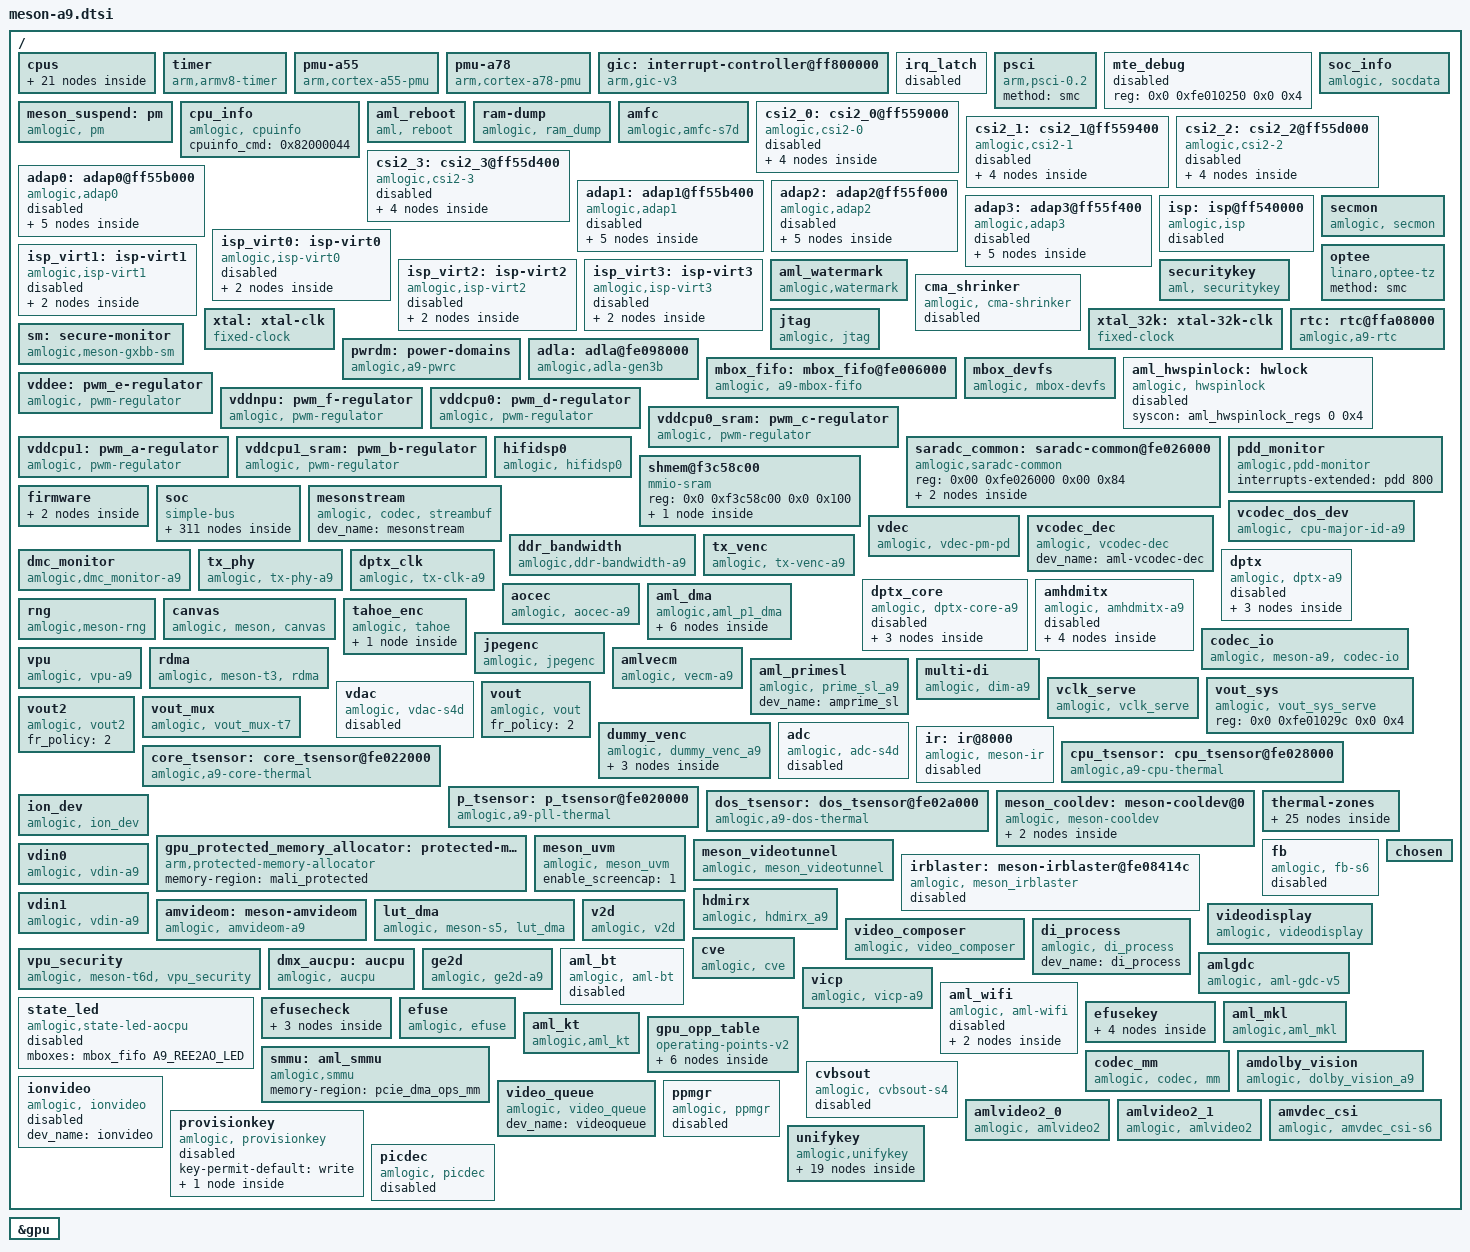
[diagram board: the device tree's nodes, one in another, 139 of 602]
// SPDX-License-Identifier: (GPL-2.0+ OR MIT)
/*
 * Copyright (c) 2019 Amlogic, Inc. All rights reserved.
 */

#include <dt-bindings/clock/axg-audio-clkc.h>
#include <dt-bindings/clock/amlogic,a9-scmi-clkc.h>
#include <dt-bindings/clock/amlogic,a9-clkc.h>
#include <dt-bindings/interrupt-controller/irq.h>
#include <dt-bindings/interrupt-controller/arm-gic.h>
#include <dt-bindings/power/a9-pd.h>
#include <dt-bindings/power/amlogic-a9-power.h>
#include <dt-bindings/dma/amlogic,a9-dma.h>
#include <dt-bindings/gpio/gpio.h>
#include <dt-bindings/gpio/meson-a9-gpio.h>
#include <dt-bindings/reset/amlogic,meson-a9-reset.h>
#include <dt-bindings/pwm/pwm.h>
#include <dt-bindings/pwm/meson.h>
#include <dt-bindings/input/input.h>
#include <dt-bindings/input/meson_ir.h>
#include <dt-bindings/mailbox/amlogic,mbox.h>
#include <dt-bindings/firmware/amlogic,firmware.h>
#include <dt-bindings/mailbox/a9-mbox.h>
#include <dt-bindings/iio/adc/amlogic-saradc.h>
#include <dt-bindings/thermal/ddr-params.h>
#include <dt-bindings/pinctrl/amlogic,pinctrl.h>
#include "meson-ir-map.dtsi"
#include "meson-avalon.dtsi"
#include <dt-bindings/power/meson-pm.h>
#include <dt-bindings/i2c/i2c-meson.h>
/ {
	cpus:cpus {
		#address-cells = <2>;
		#size-cells = <0>;

		cpu-map {
			cluster0:cluster0 {
				core0 {
					cpu = <&CPU0>;
				};
				core1 {
					cpu = <&CPU1>;
				};
				core2 {
					cpu = <&CPU2>;
				};
				core3 {
					cpu = <&CPU3>;
				};
				core4 {
					cpu = <&CPU4>;
				};
				core5 {
					cpu = <&CPU5>;
				};
				core6 {
					cpu = <&CPU6>;
				};
				core7 {
					cpu = <&CPU7>;
				};
			};
		};

		CPU0:cpu@0 {
			device_type = "cpu";
			compatible = "arm,cortex-a55","arm,armv8";
			reg = <0x0 0x0>;
			enable-method = "psci";
			cpu-idle-states = <&CPU_SLEEP_0 &SYSTEM_SLEEP_0>;
			capacity-dmips-mhz = <430>;
			dynamic-power-coefficient = <59>;
			#cooling-cells = <2>;
		};

		CPU1:cpu@1 {
			device_type = "cpu";
			compatible = "arm,cortex-a55","arm,armv8";
			reg = <0x0 0x100>;
			enable-method = "psci";
			cpu-idle-states = <&CPU_SLEEP_0 &SYSTEM_SLEEP_0>;
			capacity-dmips-mhz = <430>;
			dynamic-power-coefficient = <59>;
			#cooling-cells = <2>;
		};

		CPU2:cpu@2 {
			device_type = "cpu";
			compatible = "arm,cortex-a55","arm,armv8";
			reg = <0x0 0x200>;
			enable-method = "psci";
			cpu-idle-states = <&CPU_SLEEP_0 &SYSTEM_SLEEP_0>;
			capacity-dmips-mhz = <430>;
			dynamic-power-coefficient = <59>;
			#cooling-cells = <2>;
		};

		CPU3:cpu@3 {
			device_type = "cpu";
			compatible = "arm,cortex-a55","arm,armv8";
			reg = <0x0 0x300>;
			enable-method = "psci";
			cpu-idle-states = <&CPU_SLEEP_0 &SYSTEM_SLEEP_0>;
			capacity-dmips-mhz = <430>;
			dynamic-power-coefficient = <59>;
			#cooling-cells = <2>;
		};

		CPU4:cpu@4 {
			device_type = "cpu";
			compatible = "arm,cortex-a55","arm,armv8";
			reg = <0x0 0x400>;
			enable-method = "psci";
			cpu-idle-states = <&CPU_SLEEP_0 &SYSTEM_SLEEP_0>;
			capacity-dmips-mhz = <430>;
			dynamic-power-coefficient = <59>;
			#cooling-cells = <2>;
		};

		CPU5:cpu@5 {
			device_type = "cpu";
			compatible = "arm,cortex-a55","arm,armv8";
			reg = <0x0 0x500>;
			enable-method = "psci";
			cpu-idle-states = <&CPU_SLEEP_0 &SYSTEM_SLEEP_0>;
			capacity-dmips-mhz = <430>;
			dynamic-power-coefficient = <59>;
			#cooling-cells = <2>;
		};

		CPU6:cpu@6 {
			device_type = "cpu";
			compatible = "arm,cortex-a78","arm,armv8";
			reg = <0x0 0x600>;
			enable-method = "psci";
			cpu-idle-states = <&CPU_SLEEP_0 &SYSTEM_SLEEP_0>;
			capacity-dmips-mhz = <1024>;
			dynamic-power-coefficient = <416>;
			#cooling-cells = <2>;
		};

		CPU7:cpu@7 {
			device_type = "cpu";
			compatible = "arm,cortex-a78","arm,armv8";
			reg = <0x0 0x700>;
			enable-method = "psci";
			cpu-idle-states = <&CPU_SLEEP_0 &SYSTEM_SLEEP_0>;
			capacity-dmips-mhz = <1024>;
			dynamic-power-coefficient = <416>;
			#cooling-cells = <2>;
		};

		idle-states {
			entry-method = "arm,psci-0.2";
			CPU_SLEEP_0: cpu-sleep-0 {
					compatible = "arm,idle-state";
					arm,psci-suspend-param = <0x0010000>;
					local-timer-stop;
					entry-latency-us = <300>;
					exit-latency-us = <534>;
					min-residency-us = <1600>;
			};
			SYSTEM_SLEEP_0: system-sleep-0 {
					compatible = "arm,idle-state";
					arm,psci-suspend-param = <0x0000000>;
					entry-latency-us = <0x3fffffff>;
					exit-latency-us = <0x40000000>;
					min-residency-us = <0xffffffff>;
			};
		};
	};

	timer {
		compatible = "arm,armv8-timer";
		interrupts = <GIC_PPI 13 0xff08>,
				<GIC_PPI 14 0xff08>,
				<GIC_PPI 11 0xff08>,
				<GIC_PPI 10 0xff08>;
	};

	pmu-a55 {
		compatible = "arm,cortex-a55-pmu";
		private-interrupts;
		interrupts = <GIC_SPI 359 IRQ_TYPE_LEVEL_HIGH>,
			     <GIC_SPI 360 IRQ_TYPE_LEVEL_HIGH>,
			     <GIC_SPI 361 IRQ_TYPE_LEVEL_HIGH>,
			     <GIC_SPI 362 IRQ_TYPE_LEVEL_HIGH>,

			     <GIC_SPI 363 IRQ_TYPE_LEVEL_HIGH>,
			     <GIC_SPI 364 IRQ_TYPE_LEVEL_HIGH>;
		interrupt-affinity = <&CPU0>,
				     <&CPU1>,
				     <&CPU2>,
				     <&CPU3>,
				     <&CPU4>,
				     <&CPU5>;
	};

	pmu-a78 {
		compatible = "arm,cortex-a78-pmu";
		private-interrupts;
		interrupts = <GIC_SPI 365 IRQ_TYPE_LEVEL_HIGH>,
			     <GIC_SPI 366 IRQ_TYPE_LEVEL_HIGH>;
		interrupt-affinity = <&CPU6>,
				     <&CPU7>;
	};

	gic: interrupt-controller@ff800000 {
		compatible = "arm,gic-v3";
		#interrupt-cells = <3>;
		#address-cells = <0>;
		interrupt-controller;
		reg = <0x0 0xff800000 0 0x10000>,
		      <0x0 0xff840000 0 0x100000>;
		interrupts = <GIC_PPI 9 0xf04>;
	};

	irq_latch {
		/* only for GICv3 */
		status = "disabled";
		reg = <0x0 0xfe00a140 0x0 0x30>, /*mode*/
			<0x0 0xfe00a1c0 0x0 0x30>; /*latch clear*/
	};

	psci {
		compatible = "arm,psci-0.2";
		method = "smc";
	};

	mte_debug {
		status = "disabled";
		reg = <0x0 0xfe010250 0x0 0x4>; /*SYSCTRL_DEBUG_REG4*/
	};

	meson_suspend:pm {
		compatible = "amlogic, pm";
		status = "okay";
		device_name = "aml_pm";
		extend_resume_reason;
		clear_suspend_reason = <9>; /* Clear netflix wakeup reason */
		reg = <0x0 0xffa800e4 0x0 0x4>, /*SYSCTRL_STATUS_REG2*/
			<0x0 0xffa8005c 0x0 0x4>; /*SYSCTRL_STICKY_REG7*/
//		deep_mode = <SYSTEM_SUSPEND_EE_PWR_DOWN>;
		/*deep_mode supports custom configuration */
		deep_mode = <(DEFINE(DDR, NORMAL) | DEFINE(EE_PWR_DN, OFF))>;
	};

	cpu_info {
		compatible = "amlogic, cpuinfo";
		status = "okay";
		cpuinfo_cmd = <0x82000044>;
	};

	soc_info {
		compatible = "amlogic, socdata";
		reg =	<0x0 0xfe010000 0x0 0xc>,
			<0x0 0xfe010180 0x0 0x4>;
		read_nocsdata_cmd =<0x82000039>;
		write_nocsdata_cmd=<0x82000038>;
		auth_reg_ops_cmd=<0x820000f0>;
	};

	aml_reboot {
		compatible = "aml, reboot";
		sys_reset = <0x84000009>;
		sys_poweroff = <0x84000008>;
		dis_nb_cpus_in_shutdown;
		extend_reboot_reason; /* Support up to 128 reboot reasons*/
		reg = <0x0 0xfe01037c 0x0 0x4>; /* SEC_AO_SEC_SD_CFG15 */
		status = "okay";
	};

	ram-dump {
		compatible = "amlogic, ram_dump";
		status = "okay";
		reg = <0x0 0xFFA80058 0x0 4>;
		reg-names = "SYSCTRL_STICKY_REG6";
		store_device = "data";
	};

	amfc {
		compatible = "amlogic,amfc-s7d";
		status = "okay";
		/* registers and clk */
		reg = <0x0 0xfe024000 0x0 0x200
		       0x0 0xfe000000 0x0 0x400>;
		interrupts = <0 185 IRQ_TYPE_EDGE_RISING
			      0 186 IRQ_TYPE_EDGE_RISING>;
		interrupt-names = "amfc0", "amfc1";
		power-domains=<&pwrdm PWRC_A9_AMFC_ID>;
		clocks = <&clkc CLKID_AMFC>;
		assigned-clocks = <&clkc CLKID_AMFC>;
		assigned-clock-rates = <666666666>;
	};

	csi2_0: csi2_0@ff559000 {
		compatible = "amlogic,csi2-0";
		reg = <0x0 0xff558000 0x0 0x68>,
		      <0x0 0xff559000 0x0 0x290>,
		      <0x0 0xff55a000 0x0 0xd8>;
		reg-names = "aphy", "dphy", "host";
		clocks = <&clkc CLKID_CSI_PHY>;
		clock-names = "phy";
		assigned-clocks = <&clkc CLKID_CSI_PHY>;
		assigned-clock-rates = <200000000>;
		status = "disabled";

		ports {
			#address-cells = <1>;
			#size-cells = <0>;

			port@0 {
				reg = <0>;
			};

			port@1 {
				reg = <1>;
				csi2_0_out: endpoint {
					remote-endpoint = <&adap0_in>;
				};
			};
		};
	};

	csi2_1: csi2_1@ff559400 {
		compatible = "amlogic,csi2-1";
		reg = <0x0 0xff558000 0x0 0x68>,
		      <0x0 0xff559400 0x0 0x290>,
		      <0x0 0xff55a400 0x0 0xd8>;
		reg-names = "aphy", "dphy", "host";
		clocks = <&clkc CLKID_CSI_PHY>;
		clock-names = "phy";
		assigned-clocks = <&clkc CLKID_CSI_PHY>;
		assigned-clock-rates = <200000000>;
		status = "disabled";

		ports {
			#address-cells = <1>;
			#size-cells = <0>;

			port@0 {
				reg = <0>;
			};

			port@1 {
				reg = <1>;
				csi2_1_out: endpoint {
					remote-endpoint = <&adap1_in>;
				};
			};
		};
	};

	csi2_2: csi2_2@ff55d000 {
		compatible = "amlogic,csi2-2";
		reg = <0x0 0xff55c000 0x0 0x68>,
		      <0x0 0xff55d000 0x0 0x290>,
		      <0x0 0xff55e000 0x0 0xd8>;
		reg-names = "aphy", "dphy", "host";
		clocks = <&clkc CLKID_CSI_PHY>;
		clock-names = "phy";
		assigned-clocks = <&clkc CLKID_CSI_PHY>;
		assigned-clock-rates = <200000000>;
		status = "disabled";

		ports {
			#address-cells = <1>;
			#size-cells = <0>;

			port@0 {
				reg = <0>;
			};

			port@1 {
				reg = <1>;
				csi2_2_out: endpoint {
					remote-endpoint = <&adap2_in>;
				};
			};
		};
	};

	csi2_3: csi2_3@ff55d400 {
		compatible = "amlogic,csi2-3";
		reg = <0x0 0xff55c000 0x0 0x68>,
		      <0x0 0xff55d400 0x0 0x290>,
		      <0x0 0xff55e400 0x0 0xd8>;
		reg-names = "aphy", "dphy", "host";
		clocks = <&clkc CLKID_CSI_PHY>;
		clock-names = "phy";
		assigned-clocks = <&clkc CLKID_CSI_PHY>;
		assigned-clock-rates = <200000000>;
		status = "disabled";

		ports {
			#address-cells = <1>;
			#size-cells = <0>;

			port@0 {
				reg = <0>;
			};

			port@1 {
				reg = <1>;
				csi2_3_out: endpoint {
					remote-endpoint = <&adap3_in>;
				};
			};
		};
	};

	adap0: adap0@ff55b000 {
		compatible = "amlogic,adap0";
		reg = <0x0 0xff55b000 0x0 0xe4>;
		reg-names = "adap";
		power-domains = <&pwrdm PWRC_A9_OPP_ID>;
		clocks = <&clkc CLKID_ISP>;
		clock-names = "isp";
		assigned-clocks = <&clkc CLKID_ISP>;
		assigned-clock-rates = <400000000>;
		status = "disabled";

		ports {
			#address-cells = <1>;
			#size-cells = <0>;

			port@0 {
				reg = <0>;
				adap0_in: endpoint {
					remote-endpoint = <&csi2_0_out>;
				};
			};

			port@1 {
				reg = <1>;
				adap0_out: endpoint {
					remote-endpoint = <&isp_virt0_in>;
				};
			};
		};
	};

	adap1: adap1@ff55b400 {
		compatible = "amlogic,adap1";
		reg = <0x0 0xff55b400 0x0 0xe4>;
		reg-names = "adap";
		power-domains = <&pwrdm PWRC_A9_OPP_ID>;
		clocks = <&clkc CLKID_ISP>;
		clock-names = "isp";
		assigned-clocks = <&clkc CLKID_ISP>;
		assigned-clock-rates = <400000000>;
		status = "disabled";

		ports {
			#address-cells = <1>;
			#size-cells = <0>;

			port@0 {
				reg = <0>;
				adap1_in: endpoint {
					remote-endpoint = <&csi2_1_out>;
				};
			};

			port@1 {
				reg = <1>;
				adap1_out: endpoint {
					remote-endpoint = <&isp_virt1_in>;
				};
			};
		};
	};

	adap2: adap2@ff55f000 {
		compatible = "amlogic,adap2";
		reg = <0x0 0xff55f000 0x0 0xe4>;
		reg-names = "adap";
		power-domains = <&pwrdm PWRC_A9_OPP_ID>;
		clocks = <&clkc CLKID_ISP>;
		clock-names = "isp";
		assigned-clocks = <&clkc CLKID_ISP>;
		assigned-clock-rates = <400000000>;
		status = "disabled";

		ports {
			#address-cells = <1>;
			#size-cells = <0>;

			port@0 {
				reg = <0>;
				adap2_in: endpoint {
					remote-endpoint = <&csi2_2_out>;
				};
			};

			port@1 {
				reg = <1>;
				adap2_out: endpoint {
					remote-endpoint = <&isp_virt2_in>;
				};
			};
		};
	};

	adap3: adap3@ff55f400 {
		compatible = "amlogic,adap3";
		reg = <0x0 0xff55f400 0x0 0xe4>;
		reg-names = "adap";
		power-domains = <&pwrdm PWRC_A9_OPP_ID>;
		clocks = <&clkc CLKID_ISP>;
		clock-names = "isp";
		assigned-clocks = <&clkc CLKID_ISP>;
		assigned-clock-rates = <400000000>;
		status = "disabled";

		ports {
			#address-cells = <1>;
			#size-cells = <0>;

			port@0 {
				reg = <0>;
				adap3_in: endpoint {
					remote-endpoint = <&csi2_3_out>;
				};
			};

			port@1 {
				reg = <1>;
				adap3_out: endpoint {
					remote-endpoint = <&isp_virt3_in>;
				};
			};
		};
	};

	isp: isp@ff540000 {
			compatible = "amlogic,isp";
			reg = <0x0 0xff540000 0x0 0x17780>,
			      <0x0 0xff566000 0x0 0x520>;
			reg-names = "base", "disp";
			interrupts = <GIC_SPI 382 IRQ_TYPE_EDGE_RISING>,
				     <GIC_SPI 371 IRQ_TYPE_EDGE_RISING>,
				     <GIC_SPI 372 IRQ_TYPE_EDGE_RISING>,
				     <GIC_SPI 373 IRQ_TYPE_EDGE_RISING>,
				     <GIC_SPI 379 IRQ_TYPE_EDGE_RISING>;
			interrupt-names = "fe_rst", "fe_done", "be_done",
					  "opp_done", "intf";
			status = "disabled";
	};

	isp_virt0: isp-virt0 {
		compatible = "amlogic,isp-virt0";
		isp = <&isp>;
		power-domains = <&pwrdm PWRC_A9_CVE_ID>;
		clocks = <&clkc CLKID_DEWARPA>, <&clkc CLKID_ISP>;
		clock-names = "dewarp", "isp";
		assigned-clocks = <&clkc CLKID_DEWARPA>, <&clkc CLKID_ISP>;
		assigned-clock-rates = <800000000>, <800000000>;
		status = "disabled";

		port {
			isp_virt0_in: endpoint {
				remote-endpoint = <&adap0_out>;
			};
		};
	};

	isp_virt1: isp-virt1 {
		compatible = "amlogic,isp-virt1";
		isp = <&isp>;
		power-domains = <&pwrdm PWRC_A9_CVE_ID>;
		clocks = <&clkc CLKID_DEWARPA>, <&clkc CLKID_ISP>;
		clock-names = "dewarp", "isp";
		assigned-clocks = <&clkc CLKID_DEWARPA>, <&clkc CLKID_ISP>;
		assigned-clock-rates = <800000000>, <800000000>;
		status = "disabled";

		port {
			isp_virt1_in: endpoint {
				remote-endpoint = <&adap1_out>;
			};
		};
	};

	isp_virt2: isp-virt2 {
		compatible = "amlogic,isp-virt2";
		isp = <&isp>;
		power-domains = <&pwrdm PWRC_A9_CVE_ID>;
		clocks = <&clkc CLKID_DEWARPA>, <&clkc CLKID_ISP>;
		clock-names = "dewarp", "isp";
		assigned-clocks = <&clkc CLKID_DEWARPA>, <&clkc CLKID_ISP>;
		assigned-clock-rates = <800000000>, <800000000>;
		status = "disabled";

		port {
			isp_virt2_in: endpoint {
				remote-endpoint = <&adap2_out>;
			};
		};
	};

	isp_virt3: isp-virt3 {
		compatible = "amlogic,isp-virt3";
		isp = <&isp>;
		power-domains = <&pwrdm PWRC_A9_CVE_ID>;
		clocks = <&clkc CLKID_DEWARPA>, <&clkc CLKID_ISP>;
		clock-names = "dewarp", "isp";
		assigned-clocks = <&clkc CLKID_DEWARPA>, <&clkc CLKID_ISP>;
		assigned-clock-rates = <800000000>, <800000000>;
		status = "disabled";

		port {
			isp_virt3_in: endpoint {
				remote-endpoint = <&adap3_out>;
			};
		};
	};

	secmon:secmon {
		compatible = "amlogic, secmon";
		memory-region = <&secmon_reserved>;
		in_base_func = <0x82000020>;
		out_base_func = <0x82000021>;
		inout_size_func = <0x8200002a>;
		reserve_mem_size = <0x03300000>;
	};

	optee {
		compatible = "linaro,optee-tz";
		method = "smc";
	};

	aml_watermark {
		compatible = "amlogic,watermark";
		soc-name = "s6";
		interrupts = <GIC_SPI 197 IRQ_TYPE_EDGE_RISING>; //=viu-vsync
		interrupt-names = "wm-vsync";
	};

	cma_shrinker: cma_shrinker {
		compatible = "amlogic, cma-shrinker";
		status = "disabled";
		adj  = <0 100 200 250 900 950>;
		free = <8192 12288 16384 24576 28672 32768>;
	};

	securitykey {
		compatible = "aml, securitykey";
		storage_query = <0x82000060>;
		storage_read = <0x82000061>;
		storage_write = <0x82000062>;
		storage_tell = <0x82000063>;
		storage_verify = <0x82000064>;
		storage_status = <0x82000065>;
		storage_list = <0x82000067>;
		storage_remove = <0x82000068>;
		storage_in_func = <0x82000023>;
		storage_out_func = <0x82000024>;
		storage_block_func = <0x82000025>;
		storage_size_func = <0x82000027>;
		storage_set_enctype = <0x8200006A>;
		storage_get_enctype = <0x8200006B>;
		storage_version = <0x8200006C>;
	};

	xtal: xtal-clk {
		compatible = "fixed-clock";
		clock-frequency = <24000000>;
		clock-output-names = "xtal";
		#clock-cells = <0>;
	};

	xtal_32k: xtal-32k-clk {
		compatible = "fixed-clock";
		clock-frequency = <32768>;
		clock-output-names = "xtal_32k";
		#clock-cells = <0>;
	};

	rtc: rtc@ffa08000 {
		compatible = "amlogic,a9-rtc", "amlogic,a4-rtc";
		reg = <0x0 0xffa08000 0x0 0x38>;
		interrupts = <GIC_SPI 404 IRQ_TYPE_LEVEL_HIGH>;
		pinctrl-0 = <&rtc_32k_pins>;
		pinctrl-names = "default";
		clocks = <&xtal_32k>, <&ao_clkc CLKID_AO_SYS_RTC_DIG>;
		clock-names = "osc", "sys";
		status = "okay";
	};

	sm: secure-monitor {
		compatible = "amlogic,meson-gxbb-sm";
	};

	pwrdm: power-domains {
		compatible = "amlogic,a9-pwrc";
		#power-domain-cells = <1>;
		status = "okay";
	};

	adla: adla@fe098000 {
		compatible = "amlogic,adla-gen3b";
		dev_name = "adla";
		status = "okay";
		reg = <0x0 0xfe098000 0x0 0x2000
			0x0 0xf3c19000 0x0 0x3c000
			>;
		reg-names = "adla_reg\0adla_sram";
		interrupt-names = "adla";
		interrupts = <GIC_SPI 260 IRQ_TYPE_LEVEL_HIGH>;
		clocks = <&clkc CLKID_NNA_CORE>;
		clock-names = "adla_core_clk";
		power-domains=<&pwrdm PWRC_A9_NNA_4T_ID>;
		nn_hw_version="r4p0";
		adla_core_clk_rate = <1000000000>;
		adla_smc_cmd = <0x820000b2>;
		smmu;
	};

	jtag {
		compatible = "amlogic, jtag";
		status = "okay";
		select = "disable"; /* disable/jtag_a/jtag_b */
		pinctrl-names="jtag_a_pins", "jtag_b_pins";
		pinctrl-0=<&jtag_a_pins>;
		pinctrl-1=<&jtag_b_pins>;
	};

	mbox_fifo: mbox_fifo@fe006000 {
		status = "okay";
		compatible = "amlogic, a9-mbox-fifo";
		reg = <0x0 0xfe006000 0x0 0x800>,  /* mbox wr fifo */
		      <0x0 0xfe006800 0x0 0x800>,  /* mbox rd fifo */
		      <0x0 0xfe0070c0 0x0 0x40>,   /* mbox set reg */
		      <0x0 0xfe007100 0x0 0x40>,   /* mbox clr reg */
		      <0x0 0xfe007140 0x0 0x40>,   /* mbox sts reg */
		      <0x0 0xfe007020 0x0 0x40>;   /* mbox irqctrl reg */
		interrupts = <GIC_SPI 248 IRQ_TYPE_EDGE_RISING>;   /* mbox top irq */
		mbox-irqctlr = <0>;
		mbox-nums = <A9_MBOX_NUMS>;
		mboxids = <A9_MBOX_DSPA2REE>,
			  <A9_MBOX_REE2DSPA>,
			  <A9_MBOX_AO2REE>,
			  <A9_MBOX_REE2AO>;
		#mbox-cells = <1>;
		mbox-dests = <MAILBOX_ARM>,
			     <MAILBOX_DSPA>,
			     <MAILBOX_ARM>,
			     <MAILBOX_AOCPU>;
		dspa-hang-detect;
		aocpu-sts-mboxid = <A9_AOCPU_STS_CHAN>;
	};

	mbox_devfs {
		status = "okay";
		compatible = "amlogic, mbox-devfs";
		mbox-nums = <4>;
		mbox-names = "ree2aocpu",
			     "aocpu2ree",
			     "dsp_dev",
			     "dspa2ree";
		mboxes = <&mbox_fifo A9_REE2AO_DEV>,
			 <&mbox_fifo A9_AO2REE_DEV>,
			 <&mbox_fifo A9_REE2DSPA_DEV>,
			 <&mbox_fifo A9_DSPA2REE_DEV>;
	};

	aml_hwspinlock: hwlock {
		status = "disabled";
		compatible = "amlogic, hwspinlock";
		syscon = <&aml_hwspinlock_regs 0 0x4>;
		#hwlock-cells = <1>;
	};

	vddee: pwm_e-regulator { //default ee/gpu/ddr and npu_sram/gpu_sram on United One-Way Power
		compatible = "amlogic, pwm-regulator";
		pwms = <&pwm_e MESON_PWM_0 630 0>;
		regulator-name = "vddee";
		regulator-min-microvolt = <680000>;
		regulator-max-microvolt = <830000>;
		regulator-always-on;
		max-duty-cycle = <630>;
		amlogic,vsel-step = <3>;
		amlogic,usleep-time = <200>;
		amlogic,udelay-time = <40 20>;	//pwm 1nF
		/* Voltage Duty-Cycle */
		voltage-table = <830000 0>,
				<820000 7>,
				<810000 13>,
				<800000 20>,
				<790000 27>,
				<780000 33>,
				<770000 40>,
				<760000 47>,
				<750000 53>,
				<740000 60>,
				<730000 67>,
				<720000 73>,
				<710000 80>,
				<700000 87>,
				<690000 93>,
				<680000 100>;
		status = "okay";
	};

	vddnpu: pwm_f-regulator {
		compatible = "amlogic, pwm-regulator";
		pwms = <&pwm_f MESON_PWM_0 840 0>;
		regulator-name = "vddnpu";
		regulator-min-microvolt = <660000>;
		regulator-max-microvolt = <860000>;
		regulator-always-on;
		max-duty-cycle = <840>;
		amlogic,vsel-step = <3>;
		amlogic,usleep-time = <200>;
		amlogic,udelay-time = <40 20>;
		/* Voltage Duty-Cycle */
		voltage-table = <860000 0>,
				<850000 5>,
				<840000 10>,
				<830000 15>,
				<820000 20>,
				<810000 25>,
				<800000 30>,
				<790000 35>,
				<780000 40>,
				<770000 45>,
				<760000 50>,
				<750000 55>,
				<740000 60>,
				<730000 65>,
				<720000 70>,
				<710000 75>,
				<700000 80>,
				<690000 85>,
				<680000 90>,
				<670000 95>,
				<660000 100>;
		status = "okay";
	};

	vddcpu0: pwm_d-regulator {
		compatible = "amlogic, pwm-regulator";
		pwms = <&pwm_d MESON_PWM_0 1260 0>;
		regulator-name = "vddcpu0";
		regulator-min-microvolt = <679000>;
		regulator-max-microvolt = <979000>;
		regulator-always-on;
		max-duty-cycle = <1260>;
		/* Voltage Duty-Cycle */
		voltage-table = <979000 0>,
				<969000 3>,
				<959000 7>,
				<949000 10>,
				<939000 13>,
				<929000 17>,
				<919000 20>,
				<909000 23>,
				<899000 27>,
				<889000 30>,
				<879000 33>,
				<869000 37>,
				<859000 40>,
				<849000 43>,
				<839000 47>,
				<829000 50>,
				<819000 53>,
				<809000 57>,
				<799000 60>,
				<789000 63>,
				<779000 67>,
				<769000 70>,
				<759000 73>,
				<749000 77>,
				<739000 80>,
				<729000 83>,
				<719000 87>,
				<709000 90>,
				<699000 93>,
				<689000 97>,
				<679000 100>;
		status = "okay";
	};

	vddcpu0_sram: pwm_c-regulator {
		vin-supply = <&vdd1v8_ao_reg>;
		compatible = "amlogic, pwm-regulator";
		pwms = <&pwm_c MESON_PWM_0 1260 0>;
		regulator-name = "vddcpu0_sram";
		regulator-min-microvolt = <679000>;
		regulator-max-microvolt = <979000>;
		regulator-always-on;
		max-duty-cycle = <1260>;
		/* Voltage Duty-Cycle */
		voltage-table = <979000 0>,
				<969000 3>,
				<959000 7>,
				<949000 10>,
				<939000 13>,
				<929000 17>,
				<919000 20>,
				<909000 23>,
				<899000 27>,
				<889000 30>,
				<879000 33>,
				<869000 37>,
				<859000 40>,
				<849000 43>,
				<839000 47>,
				<829000 50>,
				<819000 53>,
				<809000 57>,
				<799000 60>,
				<789000 63>,
				<779000 67>,
				<769000 70>,
				<759000 73>,
				<749000 77>,
				<739000 80>,
				<729000 83>,
				<719000 87>,
				<709000 90>,
				<699000 93>,
				<689000 97>,
				<679000 100>;
		status = "okay";
	};

	vddcpu1: pwm_a-regulator {
		compatible = "amlogic, pwm-regulator";
		pwms = <&pwm_a MESON_PWM_0 1260 0>;
		regulator-name = "vddcpu1";
		regulator-min-microvolt = <679000>;
		regulator-max-microvolt = <979000>;
		regulator-always-on;
		max-duty-cycle = <1260>;
		/* Voltage Duty-Cycle */
		voltage-table = <979000 0>,
				<969000 3>,
				<959000 7>,
				<949000 10>,
				<939000 13>,
				<929000 17>,
				<919000 20>,
				<909000 23>,
				<899000 27>,
				<889000 30>,
				<879000 33>,
				<869000 37>,
				<859000 40>,
				<849000 43>,
				<839000 47>,
				<829000 50>,
				<819000 53>,
				<809000 57>,
				<799000 60>,
				<789000 63>,
				<779000 67>,
				<769000 70>,
				<759000 73>,
				<749000 77>,
				<739000 80>,
				<729000 83>,
				<719000 87>,
				<709000 90>,
				<699000 93>,
				<689000 97>,
				<679000 100>;
		status = "okay";
	};

	vddcpu1_sram: pwm_b-regulator {
		vin-supply = <&vdd1v8_ao_reg>;
		compatible = "amlogic, pwm-regulator";
		pwms = <&pwm_b MESON_PWM_0 1260 0>;
		regulator-name = "vddcpu1_sram";
		regulator-min-microvolt = <679000>;
		regulator-max-microvolt = <979000>;
		regulator-always-on;
		max-duty-cycle = <1260>;
		/* Voltage Duty-Cycle */
		voltage-table = <979000 0>,
				<969000 3>,
				<959000 7>,
				<949000 10>,
				<939000 13>,
				<929000 17>,
				<919000 20>,
				<909000 23>,
				<899000 27>,
				<889000 30>,
				<879000 33>,
				<869000 37>,
				<859000 40>,
				<849000 43>,
				<839000 47>,
				<829000 50>,
				<819000 53>,
				<809000 57>,
				<799000 60>,
				<789000 63>,
				<779000 67>,
				<769000 70>,
				<759000 73>,
				<749000 77>,
				<739000 80>,
				<729000 83>,
				<719000 87>,
				<709000 90>,
				<699000 93>,
				<689000 97>,
				<679000 100>;
		status = "okay";
	};

	saradc_common: saradc-common@fe026000 {
		compatible = "amlogic,saradc-common";
		reg = <0x00 0xfe026000 0x00 0x84>;

		saradc: saradc {
			compatible = "amlogic,saradc", "amlogic,a9-saradc";
			interrupts = <GIC_SPI 181 IRQ_TYPE_EDGE_RISING>;
			clock-names = "src", "core", "gate", "mux";
			clocks = <&xtal>,
				 <&clkc CLKID_SYS_SAR_ADC>,
				 <&clkc CLKID_SAR_ADC>,
				 <&clkc CLKID_SAR_ADC_MUX>;
			#io-channel-cells = <1>;
			amlogic,clock-frequency = <3000000>;
			amlogic,test-channel = <7>;
			amlogic,fifo-data-width = <16>;
			/* Filter control */
			amlogic,reg7-init = <0x00000c11>;
			amlogic,reg8-init = <0x0280614d>;
			/* Delay configure */
			amlogic,reg3-init = <0x10a02403>;
			amlogic,reg4-init = <0x021dd080>;
			/* Set aux and external vref */
			amlogic,reg9-init = <0x0000f0f0>;
			amlogic,reg10-init = <0x70503010>;
			amlogic,reg11-init = <0xf0d0b090>;
			status = "okay";
		};

		pdd: pdd {
			compatible = "amlogic,pdd";
			interrupt-controller;
			#interrupt-cells = <1>;
			clock-names = "core";
			clocks = <&clkc CLKID_SYS_SAR_ADC>;
			amlogic,interrupt = <182>;
			amlogic,digital-maps = <0x18 26>, <0x18 23>, <0x18 17>,
					       <0x18 12>, <0x18 14>;
			amlogic,analog-maps = <0x14 26>, <0x14 22>, <0x14 24>;
			amlogic,voltage-maps = <400>, <800>, <800>, <1200>;
			status = "okay";
		};
	};

	pdd_monitor {
		compatible = "amlogic,pdd-monitor";
		/* Trigger threshold voltage: 800 mV */
		interrupts-extended = <&pdd 800>;
		status = "okay";
	};

	hifidsp0: hifidsp0 {
		compatible = "amlogic, hifidsp0";
		status = "okay";
		startup-position = /bits/ 8 <PURE_DDR>; /*host dsp start mode : DDR*/
		memory-region = <&dsp_fw_reserved>;
		reg-names = "base-reg",
			    "health-reg",
			    "device-support-reg",
			    "ddrfw-region",
			    "shm-region";
		reg = <0x0 0xfe350000 0x0 0x114>, /*host base address*/
		      <0x0 0xfe010258 0x0 0x4>, /*host health reg address*/
		      <0x0 0xfe44006c 0x0 0x4>, /*dsp support region*/
		      <0x0 0x0 0x0 0x800000>, /*host ddrfw region [offset size]*/
		      <0x0 0x780000 0x0 0x80000>; /*host shm region [offset size]*/
		clocks = <&clkc CLKID_DSPA>;
		clock-names = "dspa_clk";
		/* host dsp support bit
		 * efuse reg OTP_LIC23 bit[24]
		 * 1: disable
		 * 0: enable
		 */
		dsp-support-bit = <0x1000000>;
		/* bit0: pm_support_suspend
		 * bit1: pm_support_always_on
		 * bit2: pm_support_ffv
		 */
		pm-support = /bits/ 8 <0x0>;
		power-domains = <&pwrdm PWRC_A9_DSPA_ID>;
		power-domain-names = "dspa";
		mboxes = <&mbox_fifo A9_REE2DSPA_HOST>;
		//logbuff-polling-ms = <50>;
		health-polling-ms = <1000>;
		clkfreq-khz = <800000>;
	};

	shmem@f3c58c00 {
		compatible = "mmio-sram";
		status = "okay";
		reg = <0x0 0xf3c58c00 0x0 0x100>;
		#address-cells = <1>;
		#size-cells = <1>;
		ranges = <0 0x0 0xf3c58c00 0x100>;

		scmi_shmem: shmem@0 {
			compatible = "arm,scmi-shmem";
			reg = <0x0 0x100>;
		};
	};

	firmware {
		scmi: scmi {
			compatible = "arm,scmi-smc";
			status = "okay";
			arm,smc-id = <0x820000C1>;
			shmem = <&scmi_shmem>;
			#address-cells = <1>;
			#size-cells = <0>;

			scmi_clk: protocol@14 {
				reg = <0x14>;
				#clock-cells = <1>;
			};
		};
	};

	soc {
		compatible = "simple-bus";
		#address-cells = <2>;
		#size-cells = <2>;
		ranges;

		apb4: apb4@fe000000 {
			compatible = "simple-bus";
			reg = <0x0 0xfe000000 0x0 0x480000>;
			#address-cells = <2>;
			#size-cells = <2>;
			ranges = <0x0 0x0 0x0 0xfe000000 0x0 0x480000>;

			clkc: clock-controller@0 {
				compatible = "amlogic,a9-clkc";
				#clock-cells = <1>;
				reg = <0x0 0x0 0x0 0x590>,
				      <0x0 0x8000 0x0 0x260>;
				reg-names = "basic", "pll";
				clocks = <&xtal>,
					 <&scmi_clk CLKID_GP0_PLL_OSC>,
					 <&scmi_clk CLKID_HIFI_PLL_OSC>,
					 <&scmi_clk CLKID_MCLK_PLL_OSC>,
					 <&scmi_clk CLKID_FCLK_50M>,
					 <&scmi_clk CLKID_FCLK_DIV2>,
					 <&scmi_clk CLKID_FCLK_DIV2P5>,
					 <&scmi_clk CLKID_FCLK_DIV3>,
					 <&scmi_clk CLKID_FCLK_DIV4>,
					 <&scmi_clk CLKID_FCLK_DIV5>,
					 <&scmi_clk CLKID_FCLK_DIV7>,
					 <&scmi_clk CLKID_SYS_CLK>,
					 <&scmi_clk CLKID_AXI_CLK>,
					 <&scmi_clk CLKID_GP1_PLL>,
					 <&scmi_clk CLKID_GP2_PLL>,
					 <&scmi_clk CLKID_SYS_PLL_DIV16>,
					 <&scmi_clk CLKID_CPU_CLK_DIV16>,
					 <&scmi_clk CLKID_A78_CLK_DIV16>,
					 <&scmi_clk CLKID_DSU_CLK_DIV16>,
					 <&scmi_clk CLKID_RTC_CLK>;
				clock-names = "xtal",
					      "gp0_osc",
					      "hifi_osc",
					      "mclk_osc",
					      "fclk_div50m",
					      "fclk_div2",
					      "fclk_div2p5",
					      "fclk_div3",
					      "fclk_div4",
					      "fclk_div5",
					      "fclk_div7",
					      "sys_clk",
					      "axi_clk",
					      "gp1_pll",
					      "gp2_pll",
					      "sys_pll_div16",
					      "cpu_clk_div16",
					      "a78_clk_div16",
					      "dsu_clk_div16",
					      "rtc_clk";
			};

			meson_clk_msr@48000 {
				compatible = "amlogic,meson-a9-clk-measure";
				reg = <0x0 0x48000 0x0 0x1c>;
			};

			watchdog@2100 {
				compatible = "amlogic,meson-a4-wdt";
				status = "okay";
				/* 0:userspace, 1:kernel */
				amlogic,feed_watchdog_mode = <1>;
				reg = <0x0 0x2100 0x0 0x10>,
				      <0x0 0x2124 0x0 0x04>;
				interrupts = <GIC_SPI 9 IRQ_TYPE_EDGE_RISING>;
				clocks = <&xtal>;
			};

			periphs_pinctrl: pinctrl@4000 {
				compatible = "amlogic,pinctrl-a9";
				#address-cells = <2>;
				#size-cells = <2>;
				ranges = <0x0 0x0 0x0 0x4000 0x0 0x340>;
				interrupt-parent = <&gpio_intc>;

				gpioz: gpio@c0 {
					reg = <0 0xc0 0 0x20>, <0 0x18 0 0x8>;
					reg-names = "gpio", "mux";
					gpio-controller;
					#gpio-cells = <2>;
					gpio-ranges = <&periphs_pinctrl 0 (AMLOGIC_GPIO_Z<<8) 16>;
					hw-irq = <48>;
				};

				gpiox: gpio@100 {
					reg = <0 0x100 0 0x24>, <0 0xc 0 0x8>;
					reg-names = "gpio", "mux";
					gpio-controller;
					#gpio-cells = <2>;
					gpio-ranges = <&periphs_pinctrl 0 (AMLOGIC_GPIO_X<<8) 18>;
					hw-irq = <30>;
				};

				gpioh: gpio@140 {
					reg = <0 0x140 0 0x20>, <0 0x2c 0 0x4>;
					reg-names = "gpio", "mux";
					gpio-controller;
					#gpio-cells = <2>;
					gpio-ranges = <&periphs_pinctrl 0 (AMLOGIC_GPIO_H<<8) 8>;
					hw-irq = <22>;
				};

				gpiom: gpio@1a0 {
					reg = <0 0x1a0 0 0x20>, <0 0x20 0 0x4>;
					reg-names = "gpio", "mux";
					gpio-controller;
					#gpio-cells = <2>;
					gpio-ranges = <&periphs_pinctrl 0 (AMLOGIC_GPIO_M<<8) 8>;
					hw-irq = <14>;
				};

				gpiob: gpio@240 {
					reg = <0 0x240 0 0x20>, <0 0x0 0 0x8>;
					reg-names = "gpio", "mux";
					gpio-controller;
					#gpio-cells = <2>;
					gpio-ranges = <&periphs_pinctrl 0 (AMLOGIC_GPIO_B<<8) 14>;
					hw-irq = <0>;
				};

				gpioa: gpio@280 {
					reg = <0 0x280 0 0x24>, <0 0x40 0 0xc>;
					reg-names = "gpio", "mux";
					gpio-controller;
					#gpio-cells = <2>;
					gpio-ranges = <&periphs_pinctrl 0 (AMLOGIC_GPIO_A<<8) 20>;
					hw-irq = <64>;
				};

				gpioy: gpio@2c0 {
					reg = <0 0x2c0 0 0x20>, <0 0x30 0 0x8>;
					reg-names = "gpio", "mux";
					gpio-controller;
					#gpio-cells = <2>;
					gpio-ranges = <&periphs_pinctrl 0 (AMLOGIC_GPIO_Y<<8) 10>;
					hw-irq = <86>;
				};

				gpiocc: gpio@300 {
					reg = <0 0x300 0 0x20>, <0 0x14 0 0x4>;
					reg-names = "gpio", "mux";
					gpio-controller;
					#gpio-cells = <2>;
					gpio-ranges = <&periphs_pinctrl 0 (AMLOGIC_GPIO_CC<<8) 2>;
					hw-irq = <84>;
				};
			};

			gpio_intc: interrupt-controller@4080 {
				compatible = "amlogic,meson-a9-gpio-intc",
					     "amlogic,meson-gpio-intc";
				reg = <0x0 0x4080 0x0 0x20>;
				interrupt-controller;
				#interrupt-cells = <2>;
				amlogic,channel-interrupts =
					<10 11 12 13 14 15 16 17 18 19 20 21>;
			};

			gbl_timer_core: global-timer@30000 {
				compatible = "amlogic,meson-glb-timer-core";
				reg = <0x0 0x30000 0x0 0x28>;
				reg-names = "topctrl";
				clocks = <&clkc CLKID_SYS_GLB>;
				clock-names = "glb_clk";
				//hwlocks = <&aml_hwlock HWSPINLOCK_ID_GLB_TIMER>;
			};

			gbl_timer_isp: global-timer@830040 {
				compatible = "amlogic,meson-glb-timer-isp";
				reg = <0x0 0x30040 0x0 0x140>;
				reg-names = "isp";
			};

			gbl_timer_gpio_input: global-timer@30180 {
				compatible = "amlogic,meson-glb-timer-gpio-input";
				reg-names = "input-src-sel";
				// first 20 trigger sources is ao_irq.
				first_irq_ranges = <384 403>;
				reg = <0x0 0x30180 0x0 0x56c>;
			};

			spisg_c: spi@50000 {
				compatible = "amlogic,meson-t6x-spicc-v2";
				reg = <0x0 0x50000 0x0 0x38>;
				interrupts = <GIC_SPI 183 IRQ_TYPE_LEVEL_HIGH>;
				clocks = <&clkc CLKID_SYS_SPISG0>,
					 <&clkc CLKID_SPISG0>;
				clock-names = "sys", "spi";
				assigned-clocks = <&clkc CLKID_SPISG0>;
				assigned-clock-rates = <500000000>;
				#address-cells = <1>;
				#size-cells = <0>;
				status = "disabled";
			};

/*
			spisg_e: spi@50100 {
				compatible = "amlogic,meson-t6x-spicc-v2";
				reg = <0x0 0x50100 0x0 0x38>;
				interrupts = <GIC_SPI 184 IRQ_TYPE_LEVEL_HIGH>;
				clocks = <&clkc CLKID_SYS_SPISG0>,
					 <&clkc CLKID_SPISG1>;
				clock-names = "sys", "spi";
				assigned-clocks = <&clkc CLKID_SPISG1>;
				assigned-clock-rates = <500000000>;
				#address-cells = <1>;
				#size-cells = <0>;
				status = "disabled";
			};
*/
			spisg_e: spi@50100 {
				compatible = "amlogic,t6x-spisg";
				reg = <0x0 0x50100 0x0 0x38>;
				interrupts = <GIC_SPI 184 IRQ_TYPE_LEVEL_HIGH>;
				clocks = <&clkc CLKID_SYS_SPISG0>,
					 <&clkc CLKID_SPISG1>;
				clock-names = "core", "pclk";
				#address-cells = <1>;
				#size-cells = <0>;
			};

			spisg_f: spi@50200 {
				compatible = "amlogic,meson-t6x-spicc-v2";
				reg = <0x0 0x50200 0x0 0x38>;
				interrupts = <GIC_SPI 187 IRQ_TYPE_LEVEL_HIGH>;
				clocks = <&clkc CLKID_SYS_SPISG0>,
					 <&clkc CLKID_SPISG2>;
				clock-names = "sys", "spi";
				assigned-clocks = <&clkc CLKID_SPISG2>;
				assigned-clock-rates = <500000000>;
				#address-cells = <1>;
				#size-cells = <0>;
				status = "disabled";
			};

			spifc: spi@56000 {
				compatible = "amlogic,meson-spifc";
				status = "disabled";
				reg = <0x0 0x56000 0x0 0x80>;
				//clock-names = "default";
				//clocks = <&clkc CLKID_SPIFC>;
				pinctrl-names = "default";
				pinctrl-0 = <&spifc_pins>;
				#address-cells = <1>;
				#size-cells = <0>;
				spi-nor@0 {
					compatible = "jedec,spi-nor";
					status = "disabled";
					reg = <0>;
					spi-max-frequency = <16000000>;
				};
			};

			pio: pio@3a6000 {
				compatible = "amlogic,pio";
				reg-names = "pio-regs";
				reg = <0x0 0x3a6000 0x0 0x160>;
				status = "disabled";
				clocks = <&clkc CLKID_SYS_PIO>;
				clock-names = "pio_clk";
				amlogic,pio_version = /bits/ 8 <2>;
				interrupt-names = "pio_irq0", "pio_irq1", "pio_debug";
				interrupts = <GIC_SPI 150 IRQ_TYPE_EDGE_RISING
					GIC_SPI 151 IRQ_TYPE_EDGE_RISING
					GIC_SPI 152 IRQ_TYPE_EDGE_RISING>;
			};

			pwm_h: pwm@58000 {
				compatible = "amlogic,meson-pwm-tee";
				reg = <0x0 0x58000 0x0 0x24>;
				#pwm-cells = <3>;
				clocks = <&clkc CLKID_PWM_H>;
				clock-names = "clkin0";
				tee_id = <7>;
				status = "disabled";
			};

			pwm_i: pwm@58200 {
				compatible = "amlogic,meson-pwm-tee";
				reg = <0x0 0x58200 0x0 0x24>;
				#pwm-cells = <3>;
				clocks = <&clkc CLKID_PWM_I>;
				clock-names = "clkin0";
				tee_id = <8>;
				status = "disabled";
			};

			pwm_j: pwm@58400 {
				compatible = "amlogic,meson-pwm-tee";
				reg = <0x0 0x58400 0x0 0x24>;
				#pwm-cells = <3>;
				clocks = <&clkc CLKID_PWM_J>;
				clock-names = "clkin0";
				tee_id = <9>;
				status = "disabled";
			};

			pwm_k: pwm@58600 {
				compatible = "amlogic,meson-pwm-tee";
				reg = <0x0 0x58600 0x0 0x24>;
				#pwm-cells = <3>;
				clocks = <&clkc CLKID_PWM_K>;
				clock-names = "clkin0";
				tee_id = <10>;
				status = "disabled";
			};

			pwm_l: pwm@58800 {
				compatible = "amlogic,meson-pwm-tee";
				reg = <0x0 0x58800 0x0 0x24>;
				#pwm-cells = <3>;
				clocks = <&clkc CLKID_PWM_L>;
				clock-names = "clkin0";
				tee_id = <11>;
				status = "disabled";
			};

			pwm_m: pwm@58a00 {
				compatible = "amlogic,meson-pwm-tee";
				reg = <0x0 0x58a00 0x0 0x24>;
				#pwm-cells = <3>;
				clocks = <&clkc CLKID_PWM_M>;
				clock-names = "clkin0";
				tee_id = <12>;
				status = "disabled";
			};

			pwm_n: pwm@58c00 {
				compatible = "amlogic,meson-pwm-tee";
				reg = <0x0 0x58c00 0x0 0x24>;
				#pwm-cells = <3>;
				clocks = <&clkc CLKID_PWM_N>;
				clock-names = "clkin0";
				tee_id = <13>;
				status = "disabled";
			};

			i2c4: i2c@3a4400 {
				compatible = "amlogic,meson-i2c-v2-1";
				reg = <0x0 0x3a4400 0x0 0x3c>;
				working_mode = <I2C_POLLING_MODE>;
				interrupts = <GIC_SPI 164 IRQ_TYPE_LEVEL_HIGH>;
				#address-cells = <1>;
				#size-cells = <0>;
				clocks = <&clkc CLKID_SYS_I2C_M_E>;
				status = "disabled";
			};

			i2c5: i2c@3a4500 {
				compatible = "amlogic,meson-i2c-v2-1";
				reg = <0x0 0x3a4500 0x0 0x3c>;
				interrupts = <GIC_SPI 165 IRQ_TYPE_LEVEL_HIGH>;
				#address-cells = <1>;
				#size-cells = <0>;
				clocks = <&clkc CLKID_SYS_I2C_M_I>;
				status = "disabled";
			};

			i2c6: i2c@3a4600 {
				compatible = "amlogic,meson-i2c-v2-1";
				reg = <0x0 0x3a4600 0x0 0x3c>;
				interrupts = <GIC_SPI 173 IRQ_TYPE_LEVEL_HIGH>;
				#address-cells = <1>;
				#size-cells = <0>;
				clocks = <&clkc CLKID_SYS_I2C_M_G>;
				status = "disabled";
			};

			i2c7: i2c@3a4700 {
				compatible = "amlogic,meson-i2c-v2-1";
				reg = <0x0 0x3a4700 0x0 0x3c>;
				interrupts = <GIC_SPI 179 IRQ_TYPE_LEVEL_HIGH>;
				#address-cells = <1>;
				#size-cells = <0>;
				clocks = <&clkc CLKID_SYS_I2C_M_H>;
				status = "disabled";
			};

			i2c8: i2c@3a4800 {
				compatible = "amlogic,meson-i2c-v2-1";
				reg = <0x0 0x3a4800 0x0 0x3c>;
				interrupts = <GIC_SPI 166 IRQ_TYPE_LEVEL_HIGH>;
				#address-cells = <1>;
				#size-cells = <0>;
				clocks = <&clkc CLKID_SYS_I2C_M_I>;
				status = "disabled";
			};

			i3c1: i3c@3a7000 {
				compatible = "amlogic,meson-i3c-ee";
				reg = <0x0 0x3a7000 0x0 0x10000>;
				interrupts = <GIC_SPI 153 IRQ_TYPE_LEVEL_HIGH>;
				#address-cells = <3>;
				#size-cells = <0>;
				clocks = <&clkc CLKID_SYS_I2C_M_I>,
					 <&clkc CLKID_I3C>;
				clock-names = "pclk", "fast_clk";
				status = "disabled";
			};

			reset: reset-controller@2000 {
				compatible = "amlogic,meson-t7-reset";
				reg = <0x0 0x2000 0x0 0x98>;
				#reset-cells = <1>;
			};

			cpu_version {
				compatible = "amlogic,meson-gx-ao-secure", "syscon";
				reg=<0x0 0x10220 0x0 0x4>;
			};

			secao_tsens: ao-secure@10354 {
				compatible = "amlogic,meson-gx-ao-secure", "syscon";
				reg=<0x0 0x10354 0x0 0x10>;
			};

			dma: dma@3a0000 {
				compatible = "amlogic,a9-dma";
				reg = <0 0x3a0000 0 0x4000>;
				interrupts = <GIC_SPI 149 IRQ_TYPE_EDGE_RISING>;
				#dma-cells = <2>;
				dma-channels = <24>;
				clocks = <&clkc CLKID_SYS_PP_DMA>;
			};

			aml_hwspinlock_regs: syscon@e300 {
				compatible = "syscon";
				reg = <0x0 0xe300 0x0 0x20>;
			};
		};

		aobus: bus@ffa00000 {
			compatible = "simple-bus";
			reg = <0x0 0xffa00000 0x0 0x100000>;
			#address-cells = <2>;
			#size-cells = <2>;
			ranges = <0x0 0x0 0x0 0xffa00000 0x0 0x100000>;

			ao_clkc: clock-controller@1 {
				compatible = "amlogic,a9-aoclkc";
				reg = <0x0 0x0 0x0 0x58>;
				reg-names = "basic";
				#clock-cells = <1>;
				clocks = <&xtal>,
					 <&xtal_32k>,
					 <&scmi_clk CLKID_SYS_CLK>,
					 <&scmi_clk CLKID_FCLK_DIV5>,
					 <&scmi_clk CLKID_FCLK_DIV4>,
					 <&scmi_clk CLKID_FCLK_DIV3>;
				clock-names = "xtal",
					      "xtal_32k",
					      "sys_clk",
					      "fclk_div5",
					      "fclk_div4",
					      "fclk_div3";
			};

			ao_reset: ao-reset-controller@2000 {
				compatible = "amlogic,meson-a9-ao-reset";
				reg = <0x0 0x2000 0x0 0xc>;
				#reset-cells = <1>;
			};

			pwm_a: pwm@10000 {
				compatible = "amlogic,meson-pwm-tee";
				reg = <0x0 0x10000 0x0 0x24>;
				#pwm-cells = <3>;
				clocks = <&ao_clkc CLKID_AO_PWM_A>;
				clock-names = "clkin0";
				tee_id = <0>;
				status = "okay";
			};

			pwm_b: pwm@10200 {
				compatible = "amlogic,meson-pwm-tee";
				reg = <0x0 0x10200 0x0 0x24>;
				#pwm-cells = <3>;
				clocks = <&ao_clkc CLKID_AO_PWM_B>;
				clock-names = "clkin0";
				tee_id = <1>;
				status = "okay";
			};

			pwm_c: pwm@10400 {
				compatible = "amlogic,meson-pwm-tee";
				reg = <0x0  0x10400 0x0 0x24>;
				#pwm-cells = <3>;
				clocks = <&ao_clkc CLKID_AO_PWM_C>;
				clock-names = "clkin0";
				tee_id = <2>;
				status = "okay";
			};

			pwm_d: pwm@10600 {
				compatible = "amlogic,meson-pwm-tee";
				reg = <0x0 0x10600 0x0 0x24>;
				#pwm-cells = <3>;
				clocks = <&ao_clkc CLKID_AO_PWM_D>;
				clock-names = "clkin0";
				tee_id = <3>;
				status = "okay";
			};

			pwm_e: pwm@10800 {
				compatible = "amlogic,meson-pwm-tee";
				reg = <0x0 0x10800 0x0 0x24>;
				#pwm-cells = <3>;
				clocks = <&ao_clkc CLKID_AO_PWM_E>;
				clock-names = "clkin0";
				tee_id = <4>;
				status = "okay";
			};

			pwm_f: pwm@10a00 {
				compatible = "amlogic,meson-pwm-tee";
				reg = <0x0 0x10a00 0x0 0x24>;
				#pwm-cells = <3>;
				clocks = <&ao_clkc CLKID_AO_PWM_F>;
				clock-names = "clkin0";
				tee_id = <5>;
				status = "okay";
				pinctrl-names="default";
				pinctrl-0=<&pwm_f_pins1>;
			};

			pwm_g: pwm@10c00 {
				compatible = "amlogic,meson-pwm-tee";
				reg = <0x0 0x10c00 0x0 0x24>;
				#pwm-cells = <3>;
				clocks = <&ao_clkc CLKID_AO_PWM_G>;
				clock-names = "clkin0";
				tee_id = <6>;
				status = "okay";
				pinctrl-names="default";
				pinctrl-0=<&pwm_g_pins1>;
			};

			aobus_pinctrl: pinctrl@4000 {
				compatible = "amlogic,pinctrl-a9";
				#address-cells = <2>;
				#size-cells = <2>;
				ranges = <0x0 0x0 0x0 0x4000 0x0 0x0e0>;
				interrupt-parent = <&gpio_ao_intc>;

				gpioao: gpio@1c {
					reg = <0 0x1c 0 0x20>, <0 0x0 0 0x8>;
					reg-names = "gpio", "mux";
					gpio-controller;
					#gpio-cells = <2>;
					gpio-ranges = <&aobus_pinctrl 0 (AMLOGIC_GPIO_AO<<8) 13>;
					hw-irq = <0>;
				};

				gpioc: gpio@3c {
					reg = <0 0x3c 0 0x20>, <0 0x10 0 0x4>;
					reg-names = "gpio", "mux";
					gpio-controller;
					#gpio-cells = <2>;
					gpio-ranges = <&aobus_pinctrl 0 (AMLOGIC_GPIO_C<<8) 7>;
					hw-irq = <31>;
				};

				gpiod: gpio@5c {
					reg = <0 0x5c 0 0x24>, <0 0x8 0 0x8>;
					reg-names = "gpio", "mux";
					gpio-controller;
					#gpio-cells = <2>;
					gpio-ranges = <&aobus_pinctrl 0 (AMLOGIC_GPIO_D<<8) 18>;
					hw-irq = <13>;
				};

				test_n: gpio@c0 {
					reg = <0 0xc0 0 0x20>;
					reg-names = "gpio";
					gpio-controller;
					#gpio-cells = <2>;
					gpio-ranges = <&aobus_pinctrl 0 (AMLOGIC_GPIO_TEST_N<<8) 1>;
					hw-irq = <38>;
				};
			};

			i2c0: i2c@e000 {
				compatible = "amlogic,meson-i2c-v2-1";
				reg = <0x0 0xe000 0x0 0x3c>;
				interrupts = <GIC_SPI 408 IRQ_TYPE_LEVEL_HIGH>;
				#address-cells = <1>;
				#size-cells = <0>;
				clocks = <&ao_clkc CLKID_AO_SYS_I2C_M_A>;
				status = "okay";
			};

			i2c1: i2c@e100 {
				compatible = "amlogic,meson-i2c-v2-1";
				reg = <0x0 0xe100 0x0 0x3c>;
				interrupts = <GIC_SPI 409 IRQ_TYPE_LEVEL_HIGH>;
				#address-cells = <1>;
				#size-cells = <0>;
				clocks = <&ao_clkc CLKID_AO_SYS_I2C_M_B>;
				status = "disabled";
			};

			i2c2: i2c@e200 {
				compatible = "amlogic,meson-i2c-v2-1";
				reg = <0x0 0xe200 0x0 0x3c>;
				interrupts = <GIC_SPI 410 IRQ_TYPE_LEVEL_HIGH>;
				#address-cells = <1>;
				#size-cells = <0>;
				clocks = <&ao_clkc CLKID_AO_SYS_I2C_M_C>;
				status = "disabled";
			};

			i2c3: i2c@e300 {
				compatible = "amlogic,meson-i2c-v2-1";
				reg = <0x0 0xe300 0x0 0x3c>;
				working_mode = <I2C_POLLING_MODE>;
				interrupts = <GIC_SPI 411 IRQ_TYPE_LEVEL_HIGH>;
				#address-cells = <1>;
				#size-cells = <0>;
				clocks = <&ao_clkc CLKID_AO_SYS_I2C_M_D>;
				status = "disabled";
			};

			gpio_ao_intc: interrupt-controller@4080 {
				compatible = "amlogic,meson-a9-gpio-ao-intc",
					     "amlogic,meson-gpio-ao-intc";
				reg = <0x0 0x4080 0x0 0x34>;
				interrupt-controller;
				#interrupt-cells = <2>;
				amlogic,channel-interrupts =
					<384 385 386 387 388 389 390 391 392 393
					394 395 396 397 398 399 400 401 402 403>;
			};

			uart_AO_B: serial@1e000 {
				compatible = "amlogic,meson-uart";
				reg = <0x0 0x1e000 0x0 0x18>;
				interrupts = <GIC_SPI 66 IRQ_TYPE_EDGE_RISING>;
				status = "okay";
				clocks = <&xtal>;
				clock-names = "clk_uart";
				xtal_tick_en = <2>;
				fifosize = < 64 >;
				/* 0 not support; 1 support */
				support-sysrq = <1>;
			};

			uart_AO_C: serial@1c000 {
				compatible = "amlogic,meson-uart";
				reg = <0x0 0x1c000 0x0 0x18>;
				interrupts = <GIC_SPI 65 IRQ_TYPE_EDGE_RISING>;
				status = "disabled";
				clocks = <&xtal>,
					<&ao_clkc CLKID_AO_SYS_UART_C>;
				clock-names = "clk_uart", "clk_gate";
				fifosize = < 64 >;
				pinctrl-names = "default";
				pinctrl-0 = <&c_uart_pins>;
			};

			uart_AO_D: serial@1a000 {
				compatible = "amlogic,meson-uart";
				reg = <0x0 0x1a000 0x0 0x18>;
				interrupts = <GIC_SPI 64 IRQ_TYPE_EDGE_RISING>;
				status = "disabled";
				clocks = <&xtal>,
					<&ao_clkc CLKID_AO_SYS_UART_D>;
				clock-names = "clk_uart", "clk_gate";
				fifosize = < 64 >;
				pinctrl-names = "default";
				pinctrl-0 = <&d_uart_pins1>;
			};

			uart_AO_E: serial@18000 {
				compatible = "amlogic,meson-uart";
				reg = <0x0 0x18000 0x0 0x18>;
				interrupts = <GIC_SPI 415 IRQ_TYPE_EDGE_RISING>;
				status = "disabled";
				clocks = <&xtal>,
					<&ao_clkc CLKID_AO_SYS_UART_E>;
				clock-names = "clk_uart", "clk_gate";
				fifosize = < 64 >;
				pinctrl-names = "default";
				pinctrl-0 = <&e_uart_pins>;
			};

			i3c0: i3c@22000 {
				compatible = "amlogic,meson-i3c-ao";
				reg = <0x0 0x22000 0x0 0x10000>;
				interrupts = <GIC_SPI 72 IRQ_TYPE_LEVEL_HIGH>;
				#address-cells = <3>;
				#size-cells = <0>;
				clocks = <&clkc CLKID_SYS_I2C_M_I>;
				clock-names = "fast_clk";
				status = "disabled";
			};

			spisg_a: spi@30000 {
				compatible = "amlogic,meson-a4-spicc-v2";
				reg = <0x0 0x30000 0x0 0x38>;
				interrupts = <GIC_SPI 67 IRQ_TYPE_LEVEL_HIGH>;
				#address-cells = <1>;
				#size-cells = <0>;
				status = "disabled";
			};

			spisg_b: spi@30100 {
				compatible = "amlogic,meson-a4-spicc-v2";
				reg = <0x0 0x30100 0x0 0x38>;
				interrupts = <GIC_SPI 68 IRQ_TYPE_LEVEL_HIGH>;
				#address-cells = <1>;
				#size-cells = <0>;
				status = "disabled";
			};

			spisg_d: spi@30200 {
				compatible = "amlogic,meson-a4-spicc-v2";
				reg = <0x0 0x30200 0x0 0x38>;
				interrupts = <GIC_SPI 69 IRQ_TYPE_LEVEL_HIGH>;
				#address-cells = <1>;
				#size-cells = <0>;
				status = "disabled";
			};
		};

		typec_mux: mux@0xfe0086dc {
			status = "disabled";
			compatible = "amlogic,typec-mux-meson";
			reg = <0x0 0xfe0086dc 0x0 0x4>;
			mode-switch;
			orientation-switch;
		};

		usbphya: usb-phy@fe488000 {
			compatible = "amlogic,uphy-a9";
			reg = <0x0 0xfe488000 0x0 0x120>;
			#address-cells = <1>;
			#size-cells = <1>;
			ranges = <0x0 0x0 0x0 0xffffffff>;
			status = "disabled";
			u2paport0: u2p@fe488000 {
				#phy-cells = <0>;
				port-speed = <0x0>; /* 0~2: HS HSP SS */
				reg = <0xfe488000 0x100
						0xfe002000 0x100
						0xfe010330 0x4
						0xfe48e000 0x64>;
				reset-level = <0x40>;
				phy-reset-level-bits = <4>;
				usb-comb-reset-bit = <6>;
				phy-apb-reset-bit = <7>;
				pll-settings = <0x0
								0x0
								0x0
								0x0
								0x7>;
				clocks = <&clkc CLKID_SYS_USB3DRD_A>,
							<&clkc CLKID_SYS_PERIPH>,
							<&xtal>;
				clock-names = "usb_general", "apb_bus", "xtal";
				power-domains = <&pwrdm PWRC_A9_U3DRD_A_ID>;
				status = "okay";
			};

			u3paport0: u3p@fe488090 {
				#phy-cells = <0>;
				port-speed = <0x3>; /* 0~2: HS HSP SS */
				reg = <0xfe488090 0x20		/* phy3 cfg base */
						0xfe002000 0x100	/* reset base */
						0xfe48a000 0x1d4	/* phy3 ctrl base */
						0xfe01034c 0x4>;	/* phy3 trim base */
				usb3-phy-reset-bit = /bits/ 8 <3>;
				usb3-apb-reset-bit = /bits/ 8 <2>;
				usb3-controller-reset-bit = /bits/ 8 <5>;
				reset-level-shift = <0x40>;
				lane-muxed;
				clocks = <&clkc CLKID_SYS_USB3DRD_A>,
							<&clkc CLKID_SYS_PERIPH>,
							<&xtal>,
							<&clkc CLKID_USB_250M>;
				clock-names = "u3p_clk_0",
								"apb_bus",
								"xtal",
								"usb_clk_250m";
				assigned-clocks = <&clkc CLKID_USB_250M>;
				assigned-clock-rates = <250000000>;
				power-domains = <&pwrdm PWRC_A9_U3DPPHY_U3_ID>;
				status = "okay";
			};
		};

		dwc3a: dwc3a@f3b00000 {
			status = "disable";
			compatible = "snps,dwc3-meson";
			maximum-speed = "super-speed";
			dr_mode = "otg";
			phy_type = "utmi";
			reg = <0x0 0xf3b00000 0x0 0x100000>;
			interrupts = <GIC_SPI 140 IRQ_TYPE_LEVEL_HIGH>;
			interrupt-names = "dwc_usb3";
			clocks = <&clkc CLKID_SYS_USB3DRD_A>, <&xtal>, <&xtal>;
			clock-names = "bus_early", "ref", "suspend";
			phys = <&u2paport0>, <&u3paport0>;
			phy-names = "usb2-phy", "usb3-phy";
			power-domains = <&pwrdm PWRC_A9_U3DRD_A_ID>;
			resets = <&reset RESET_U3DRD>;
			snps,usb2-lpm-disable;
			//snps,usb3_lpm_capable;
			snps,usb2-gadget-lpm-disable;
			snps,has-lpm-erratum;
			snps,dis_u3_susphy_quirk;
			snps,dis_u2_susphy_quirk;
			snps,dis_enblslpm_quirk;
			snps,rx-thr-num-pkt = <2>;
			snps,rx-max-burst = <16>;
			snps,tx-thr-num-pkt = <2>;
			snps,tx-max-burst = <16>;
			tx-fifo-resize;
			tx-fifo-max-num = <3>;
			snps,incr-burst-type-adjustment = <4>;
			def-drd-controller;
			trim-reg = <0xfe010330>;
			drd-index = <0x0>;
		};

		usbphyb: usb-phy@fe4cc000 {
			compatible = "amlogic,uphy-a9";
			reg = <0x0 0xfe4cc000 0x0 0x120>;
			#address-cells = <1>;
			#size-cells = <1>;
			ranges = <0x0 0x0 0x0 0xffffffff>;
			status = "disabled";
			u2pbport0: u2p@fe4cc000 {
				#phy-cells = <0>;
				port-speed = <0x0>; /* 0~2: HS HSP SS */
				reg = <0xfe4cc000 0x100
						0xfe002000 0x100
						0xfe010330 0x4
						0xfe4ce000 0x64>;
				reset-level = <0x4c>;
				phy-reset-level-bits = <30>;
				usb-comb-reset-bit = <28>;
				phy-apb-reset-bit = <29>;
				pll-settings = <0x0
								0x0
								0x0
								0x0
								0x7>;
				clocks = <&clkc CLKID_SYS_USB3DRD_B>,
							<&clkc CLKID_SYS_PERIPH>,
							<&clkc CLKID_PP>,
							<&xtal>;
				clock-names = "usb_general", "apb_bus", "pp_clk", "xtal";
				assigned-clocks = <&clkc CLKID_PP>;
				assigned-clock-rates = <400000000>;
				power-domains = <&pwrdm PWRC_A9_U3DRD_B_ID>;
				status = "okay";
			};

			u3pbport0: u3p@fe4cc100 {
				#phy-cells = <0>;
				port-speed = <0x3>; /* 0~2: HS HSP SS */
				reg = <0xfe4cc090 0x20		/* phy3 cfg base */
						0xfe00200c 0x100	/* reset base */
						0xfe4c0000 0x1d4	/* phy3 ctrl base */
						0xfe01034c 0x4>;	/* phy3 trim base */
				usb3-phy-reset-bit = /bits/ 8 <24>;
				usb3-apb-reset-bit = /bits/ 8 <23>;
				usb3-controller-reset-bit = /bits/ 8 <27>;
				reset-level-shift = <0x40>;
				combo-phy;
				combo-phy-mux-reg = <0xfe0086e0>;
				clocks = <&clkc CLKID_SYS_USB3DRD_B>,
							<&clkc CLKID_SYS_PERIPH>,
							<&clkc CLKID_PP>,
							<&xtal>,
							<&clkc CLKID_USB_250M>;
				clock-names = "u3p_clk_0",
								"apb_bus",
								"pp_clk",
								"xtal",
								"usb_clk_250m";
				assigned-clocks = <&clkc CLKID_PP>, <&clkc CLKID_USB_250M>;
				assigned-clock-rates = <400000000>, <250000000>;
				power-domains = <&pwrdm PWRC_A9_U3DRD_B_ID>;
				status = "okay";
			};
		};

		dwc3b: dwc3b@f3d00000 {
			status = "disable";
			compatible = "snps,dwc3-meson";
			maximum-speed = "super-speed";
			dr_mode = "host";
			phy_type = "utmi";
			reg = <0x0 0xf3d00000 0x0 0x100000>;
			interrupts = <GIC_SPI 143 IRQ_TYPE_LEVEL_HIGH>;
			interrupt-names = "dwc_usb3";
			clocks = <&clkc CLKID_SYS_USB3DRD_B>, <&xtal>, <&xtal>;
			clock-names = "bus_early", "ref", "suspend";
			phys = <&u2pbport0>, <&u3pbport0>;
			phy-names = "usb2-phy", "usb3-phy";
			power-domains = <&pwrdm PWRC_A9_U3DRD_B_ID>;
			resets = <&reset RESET_U3DRDB>;
			snps,usb2-lpm-disable;
			//snps,usb3_lpm_capable;
			snps,usb2-gadget-lpm-disable;
			snps,has-lpm-erratum;
			snps,dis_u3_susphy_quirk;
			snps,dis_u2_susphy_quirk;
			snps,dis_enblslpm_quirk;
			snps,rx-thr-num-pkt = <2>;
			snps,rx-max-burst = <16>;
			snps,tx-thr-num-pkt = <2>;
			snps,tx-max-burst = <16>;
			tx-fifo-resize;
			tx-fifo-max-num = <3>;
			snps,incr-burst-type-adjustment = <4>;
		};

		usbphyc: usb-phy@fe4ac000 {
			compatible = "amlogic,uphy-a9";
			reg = <0x0 0xfe4ac000 0x0 0x100>;
			#address-cells = <1>;
			#size-cells = <1>;
			ranges = <0x0 0x0 0x0 0xffffffff>;
			status = "disabled";
			u2pcport0: u2p@fe4ac000 {
				#phy-cells = <0>;
				port-speed = <0x0>; /* 0~2: HS HSP SS */
				reg = <0xfe4ac000 0x100
						0xfe002000 0x100
						0xfe010330 0x4
						0xfe4ae000 0x64>;
				reset-level = <0x48>;
				phy-reset-level-bits = <20>;
				usb-comb-reset-bit = <14>;
				/* u2phy apb & dwc3c share the same reset line.
				 * don't trigger it in phy_init().
				 */
				//phy-apb-reset-bit = <13>;
				pll-settings = <0x0
								0x0
								0x0
								0x0
								0x7>;
				clocks = <&clkc CLKID_SYS_U2H>,
					 <&clkc CLKID_SYS_PERIPH>,
					 <&clkc CLKID_PP>,
					 <&xtal>;
				clock-names = "usb_general", "apb_bus", "pp_clk", "xtal";
				assigned-clocks = <&clkc CLKID_PP>;
				assigned-clock-rates = <400000000>;
				power-domains = <&pwrdm PWRC_A9_U2H_ID>;
				sw-hsp;
				status = "okay";
			};
		};

		dwc3c: dwc3c@f3e00000 {
			status = "disable";
			compatible = "snps,dwc3-meson";
			maximum-speed = "high-speed";
			dr_mode = "host";
			phy_type = "utmi";
			reg = <0x0 0xf3e00000 0x0 0x100000>;
			interrupts = <GIC_SPI 136 IRQ_TYPE_LEVEL_HIGH>;
			interrupt-names = "dwc_usb3";
			clocks = <&clkc CLKID_SYS_U2H>, <&xtal>, <&xtal>;
			clock-names = "bus_early", "ref", "suspend";
			phys = <&u2pcport0>;
			phy-names = "usb2-phy";
			power-domains = <&pwrdm PWRC_A9_U2H_ID>;
			resets = <&reset RESET_U2H>;
			snps,usb2-lpm-disable;
			//snps,usb3_lpm_capable;
			snps,usb2-gadget-lpm-disable;
			snps,has-lpm-erratum;
			snps,dis_u3_susphy_quirk;
			snps,dis_u2_susphy_quirk;
			snps,dis_enblslpm_quirk;
			snps,rx-thr-num-pkt = <2>;
			snps,rx-max-burst = <16>;
			snps,tx-thr-num-pkt = <2>;
			snps,tx-max-burst = <16>;
			tx-fifo-resize;
			tx-fifo-max-num = <3>;
			snps,incr-burst-type-adjustment = <4>;
		};

		usbphyd: usb-phy@fe4a4000 {
			compatible = "amlogic,uphy-a9";
			reg = <0x0 0xfe4a4000 0x0 0x100>;
			#address-cells = <1>;
			#size-cells = <1>;
			ranges = <0x0  0x0 0x0  0xffffffff>;
			status = "disabled";
			u2pdport0: u2p@fe4a4000 {
				#phy-cells = <0>;
				port-speed = <0x0>; /* 0~2: HS HSP SS */
				reg = <0xfe4a4000 0x100
						0xfe002000 0x100
						0xfe010330 0x4
						0xfe4a6000 0x64>;
				reset-level = <0x40>;
				phy-reset-level-bits = <75>;
				usb-comb-reset-bit = <15>;
				phy-apb-reset-bit = <13>;
				pll-settings = <0x0
								0x0
								0x0
								0x0
								0x7>;
				clocks = <&clkc CLKID_SYS_USB2DRD>,
							<&clkc CLKID_SYS_PERIPH>,
							<&xtal>;
				clock-names = "usb_general", "apb_bus", "xtal";
				power-domains = <&pwrdm PWRC_A9_U2DRD_ID>;
				status = "okay";
			};
		};

		dwc3d: dwc3d@f3f00000 {
			status = "disable";
			compatible = "snps,dwc3-meson";
			maximum-speed = "high-speed";
			dr_mode = "otg";
			phy_type = "utmi";
			reg = <0x0 0xf3f00000 0x0 0x100000>;
			interrupts = <GIC_SPI 133 IRQ_TYPE_LEVEL_HIGH>;
			interrupt-names = "dwc_usb3";
			clocks = <&clkc CLKID_SYS_USB2DRD>, <&xtal>, <&xtal>;
			clock-names = "bus_early", "ref", "suspend";
			phys = <&u2pdport0>;
			phy-names = "usb2-phy";
			power-domains = <&pwrdm PWRC_A9_U2DRD_ID>;
			resets = <&reset RESET_U2DRD>;
			snps,usb2-lpm-disable;
			//snps,usb3_lpm_capable;
			snps,usb2-gadget-lpm-disable;
			snps,has-lpm-erratum;
			snps,dis_u3_susphy_quirk;
			snps,dis_u2_susphy_quirk;
			snps,dis_enblslpm_quirk;
			snps,rx-thr-num-pkt = <2>;
			snps,rx-max-burst = <16>;
			snps,tx-thr-num-pkt = <2>;
			snps,tx-max-burst = <16>;
			tx-fifo-resize;
			tx-fifo-max-num = <3>;
			snps,incr-burst-type-adjustment = <4>;
			trim-reg = <0xfe010330>;
			drd-index = <0x1>;
		};

		dwc3dotg: dwc3otg@fe4a4000{
			status = "disable";
			compatible = "amlogic,dwc3-meson-drd";
			dr_mode = "otg";
			reg = <0x0 0xfe4a4000 0x0 0x100>;
			phys = <&u2pdport0>;
			phy-names = "usb2-phy";
			interrupts = <GIC_SPI 134 IRQ_TYPE_EDGE_RISING>;
		};

		dolby_fw: dolby_fw {
			compatible = "amlogic, dolby_fw";
			mem_size = <0x100000>;
			status = "okay";
		};

		pcie_phy0: phy@fe4d4000 {
			compatible = "amlogic,a9-pcie-phy";
			reg = <0x0 0xfe4d4000 0x0 0x800
				0x0 0xfe002040 0x0 0x10
				0x0 0xfe01034c 0x0 0x4>;
			reg-names = "phy", "reset", "efuse";

			clocks = <&clkc CLKID_SYS_PCIEPHY>,
				<&clkc CLKID_SYS_PERIPH>;
			clock-names = "pcie_phy", "pcie_apb_bus";
			num-lanes = <1>;
			port-num = <0>;

			pll_setting_number = <7>;
			/* <reg_offset vlaue> */
			phy_pll_setting_1 = <0x0018 0x1f455ed>;
			phy_pll_setting_2 = <0x001c 0x909e7e5>;
			phy_pll_setting_3 = <0x0018 0xdf455ed>;
			phy_pll_setting_4 = <0x0020 0xa03b9788>;
			phy_pll_setting_5 = <0x000c 0x40000071>;
			phy_pll_setting_6 = <0x000c 0x4000007d>;
			/* open ssc 5000 ppm
			 * phy_pll_setting_7 = <0x0014 0x2328e050>;
			 */
			phy_pll_setting_7 = <0x017c 0x3000000>;

			resets = <&reset RESET_PCIEA_PIPE>,
				<&reset RESET_PCIE_A_POR>,
				<&reset RESET_PCIEA_PHY>,
				<&reset RESET_PCIEA_MAC_APB>,
				<&reset RESET_PCIEA_PHY_APB>,
				<&reset RESET_PCIEA_0>,
				<&reset RESET_PCIEA_1>,
				<&reset RESET_PCIEA_2>,
				<&reset RESET_PCIEA_3>,
				<&reset RESET_PCIEA_4>,
				<&reset RESET_PCIEA_5>,
				<&reset RESET_PCIEA_6>,
				<&reset RESET_PCIEA_7>;
			reset-names = "pipe", "por", "phy", "mac_apb", "phy_apb", "rst0",
					"rst1", "rst2", "rst3", "rst4", "rst5", "rst6", "rst7";
			pcie_rst_number = <1>;
			/* <reg_offset vlaue> */
			pcie_rst_1 = <0x04 0xFF007800>;
			pcie-phy-apb-rst = <0x4 0x400>;
			#phy-cells = <0>;
			power-domains = <&pwrdm PDID_A9_PCIE3PHY>;
			status = "disabled";
		};

		pcie_phy1: phy1@fe4d4000 {
			compatible = "amlogic,a9-pcie-phy";
			reg = <0x0 0xfe4d4000 0x0 0x1800
				0x0 0xfe002040 0x0 0x10
				0x0 0xfe01034c 0x0 0x4>;
			reg-names = "phy", "reset", "efuse";

			clocks = <&clkc CLKID_SYS_PCIEPHY>,
				<&clkc CLKID_SYS_PERIPH>;
			clock-names = "pcie_phy", "pcie_apb_bus";
			num-lanes = <1>;
			port-num = <1>;

			/* port B X1 */
			pll_setting_number = <11>;
			/* <reg_offset vlaue> */
			phy_pll_setting_1 = <0x0018 0x1f455ed>;
			phy_pll_setting_2 = <0x001c 0x909e7e5>;
			phy_pll_setting_3 = <0x0018 0xdf455ed>;
			phy_pll_setting_4 = <0x0020 0xa03b9788>;
			phy_pll_setting_5 = <0x000c 0x40000071>;
			phy_pll_setting_6 = <0x000c 0x4000007d>;
			phy_pll_setting_7 = <0x017c 0x3000000>;

			phy_pll_setting_8 = <0x1020 0xa03b9788>;
			phy_pll_setting_9 = <0x100c 0x40000071>;
			phy_pll_setting_10 = <0x100c 0x4000007d>;
			/* open ssc 5000 ppm
			 * phy_pll_setting_11 = <0x0014 0x2328e050>;
			 * phy_pll_setting_12 = <0x1014 0x2328e050>;
			 */
			phy_pll_setting_11 = <0x117c 0x3000000>;

			resets = <&reset RESET_PCIEB_PIPE>,
				<&reset RESET_PCIE_B_POR>,
				<&reset RESET_PCIEB_PHY>,
				<&reset RESET_PCIEB_MAC_APB>,
				/* <&reset RESET_PCIEA_PHY_APB>, */
				<&reset RESET_PCIEB_0>,
				<&reset RESET_PCIEB_1>,
				<&reset RESET_PCIEB_2>,
				<&reset RESET_PCIEB_3>,
				<&reset RESET_PCIEB_4>,
				<&reset RESET_PCIEB_5>,
				<&reset RESET_PCIEB_6>,
				<&reset RESET_PCIEB_7>;
			reset-names = "pipe", "por", "phy", "mac_apb", "rst0",
					"rst1", "rst2", "rst3", "rst4", "rst5", "rst6", "rst7";
			pcie_rst_number = <2>;
			/* <reg_offset vlaue> */
			pcie_rst_1 = <0x04 0x18>;
			pcie_rst_2 = <0x0c 0x1FF8>;
			pcie-phy-apb-rst = <0x4 0x400>;
			#phy-cells = <0>;
			power-domains = <&pwrdm PDID_A9_PCIE3PHY>;
			status = "disabled";
		};

		pcie_phy2: phy@fe4c4000 {
			compatible = "amlogic,a9-pcie-phy";
			reg = <0x0 0xfe4c4000 0x0 0x800
				0x0 0xfe002040 0x0 0x10
				0x0 0xfe01034c 0x0 0x4>;
			reg-names = "phy", "reset", "efuse";

			clocks = <&clkc CLKID_SYS_PCIEPHY>,
				<&clkc CLKID_SYS_PERIPH>;
			clock-names = "pcie_phy", "pcie_apb_bus";
			num-lanes = <1>;
			port-num = <2>;

			pll_setting_number = <7>;
			/* <reg_offset vlaue> */
			phy_pll_setting_1 = <0x0014 0x01f455ed>;
			phy_pll_setting_2 = <0x0018 0x0909e7e5>;
			phy_pll_setting_3 = <0x0014 0x0df455ed>;
			phy_pll_setting_4 = <0x0028 0xa03b9788>;
			phy_pll_setting_5 = <0x001c 0x40000071>;
			phy_pll_setting_6 = <0x001c 0x4000007d>;
			/* open ssc 5000 ppm
			 * phy_pll_setting_7 = <0x0024 0x2328e050>;
			 */
			phy_pll_setting_7 = <0x017c 0x3000000>;

			resets = <&reset RESET_U3HSG_PCIE_PIPE>,
				<&reset RESET_PCIE_B_POR>,
				<&reset RESET_U3HSG_PCIE2_PHY>,
				<&reset RESET_PCIEB_MAC_APB>,
				<&reset RESET_U3HSG_PCIE2_PHY_APB>,
				<&reset RESET_PCIEB_0>,
				<&reset RESET_PCIEB_1>,
				<&reset RESET_PCIEB_2>,
				<&reset RESET_PCIEB_3>,
				<&reset RESET_PCIEB_4>,
				<&reset RESET_PCIEB_5>,
				<&reset RESET_PCIEB_6>,
				<&reset RESET_PCIEB_7>;
			reset-names = "pipe", "por", "phy", "mac_apb", "phy_apb", "rst0",
					"rst1", "rst2", "rst3", "rst4", "rst5", "rst6", "rst7";
			pcie_rst_number = <2>;
			/* <reg_offset vlaue> */
			pcie_rst_1 = <0x04 0x18>;
			pcie_rst_2 = <0x0c 0x1FF8>;
			pcie-phy-apb-rst = <0x4 0x400>;
			#phy-cells = <0>;
			power-domains = <&pwrdm PDID_A9_U3HSG_PCIE2>;
			status = "disabled";
		};

		pcie_a: pcie@f4000000 {
			compatible = "amlogic, amlogic-pcie-v4";
			reg = <0x0 0xf4000000 0x0 0x400000
				0x0 0xfe4d0000 0x0 0x1000
				0x0 0xf4400000 0x0 0x200000
				0x0 0xfe002040 0x0 0x10>;
			reg-names = "dbi", "cfg", "config", "reset";
			linux,pci-domain = <0>;
			bus-range = <0x0 0xff>;
			#address-cells = <3>;
			#size-cells = <2>;
			interrupts = <GIC_SPI 293 IRQ_TYPE_EDGE_RISING>;
			interrupt-names = "msi";
			#interrupt-cells = <1>;
			interrupt-map-mask = <0 0 0 0>;
			interrupt-map = <0 0 0 0 &gic GIC_SPI 303 IRQ_TYPE_EDGE_RISING>;
			device_type = "pci";
			ranges =
				/* downstream I/O */
				<0x81000000 0 0 0 0xf4600000 0x0 0x200000>,
				/* non-prefetchable memory */
				<0x82000000 0 0xf4800000 0x0 0xf4800000 0 0x3800000>;
			num-lanes = <1>;
			port-num = <0>;
			phys = <&pcie_phy0>;
			phy-names = "pcie-phy";
			/*
			 * pinctrl-names = "default";
			 * pinctrl-0 = <&pcieck_pins>;
			 */

			clocks = <&clkc CLKID_SYS_PCIEMAC_A>,
				 <&clkc CLKID_SYS_PCIEPHY>,
				 <&clkc CLKID_PCIE0_TL>,
				 <&clkc CLKID_PP>;
			clock-names = "pcie_mac", "pcie_phy", "pcie_tl", "pp_clk";
			pcie_tl_clk = <20000000>;
			assigned-clocks = <&clkc CLKID_PP>;
			assigned-clock-rates = <400000000>;

			/*reset-gpio-type
			 *0:Shared pad(no reset)
			 *1:OD pad2:Normal pad
			 */
			gpio-type = <2>;
			pcie_rst_number = <1>;
			/* <reg_offset vlaue> */
			pcie_rst_1 = <0x04 0xFF007800>;
			pcie-phy-apb-rst = <0x4 0x400>;
			power-domains = <&pwrdm PWRC_A9_PCIE_A_ID>;
			status = "disabled";
			dma-ranges = <0x0 0x0 0x0 0x0 0x0 0x0 0xe0000000>;
		};

		pcie_b: pcie@f8000000 {
			compatible = "amlogic, amlogic-pcie-v4";
			reg = <0x0 0xf8000000 0x0 0x400000
				0x0 0xfe4d2000 0x0 0x1000
				0x0 0xf8400000 0x0 0x200000
				0x0 0xfe002040 0x0 0x10>;
			reg-names = "dbi", "cfg", "config", "reset";
			linux,pci-domain = <1>;
			bus-range = <0x0 0xff>;
			#address-cells = <3>;
			#size-cells = <2>;
			interrupts = <GIC_SPI 325 IRQ_TYPE_EDGE_RISING>;
			interrupt-names = "msi";
			#interrupt-cells = <1>;
			interrupt-map-mask = <0 0 0 0>;
			interrupt-map = <0 0 0 0 &gic GIC_SPI 335 IRQ_TYPE_EDGE_RISING>;
			device_type = "pci";
			ranges =
				/* downstream I/O */
				<0x81000000 0 0 0 0xf8600000 0x0 0x200000>,
				/* non-prefetchable memory */
				<0x82000000 0 0xf8800000 0x0 0xf8800000 0 0x3800000>;
			num-lanes = <1>;
			port-num = <1>;
			phys = <&pcie_phy2>;
			phy-names = "pcie-phy";
			/*
			 * pinctrl-names = "default";
			 * pinctrl-0 = <&pcieck_pins>;
			 */

			clocks = <&clkc CLKID_SYS_PCIEMAC_B>,
				 <&clkc CLKID_PCIE1_TL>,
				 <&clkc CLKID_PP>;
			clock-names = "pcie_mac", "pcie_tl", "pp_clk";
			pcie_tl_clk = <20000000>;
			assigned-clocks = <&clkc CLKID_PP>;
			assigned-clock-rates = <400000000>;

			/*reset-gpio-type
			 *0:Shared pad(no reset)
			 *1:OD pad2:Normal pad
			 */
			gpio-type = <1>;
			pcie_rst_number = <2>;
			/* <reg_offset vlaue> */
			pcie_rst_1 = <0x04 0x18>;
			pcie_rst_2 = <0x0c 0x1FF8>;
			pcie-phy-apb-rst = <0x4 0x400>;
			power-domains = <&pwrdm PWRC_A9_PCIE_B_ID>;
			status = "disabled";
			dma-ranges = <0x0 0x0 0x0 0x0 0x0 0x0 0xe0000000>;
		};

		sd_emmc_c: mmc@fe08c000 {
			compatible = "amlogic,meson-v8-mmc";
			reg = <0x0 0xfe08c000 0x0 0x1000>,
				<0x0 0xfe000294 0x0 0x4>,
				<0x0 0xfe004000 0x0 0x4>;
			interrupts = <GIC_SPI 178 IRQ_TYPE_EDGE_RISING>;
			status = "disabled";
			clocks = <&clkc CLKID_SYS_SD_EMMC_C>,
				<&clkc CLKID_SD_EMMC_C_MUX>,
				 <&clkc CLKID_SD_EMMC_C>,
				 <&xtal>,
				 <&clkc CLKID_GP0_PLL>,
				 <&clkc CLKID_GP0_PLL>;
			clock-names = "core", "mux0", "mux1",
					"clkin0", "clkin1", "clkin2";
			no-sdio;
			no-sd;
			card_type = <1>;
			ignore_desc_busy;
			mmc_debug_flag;
			src_clk_rate = <1152000000>;
			assigned-clocks = <&clkc CLKID_GP0_PLL>,
					    <&clkc CLKID_SD_EMMC_C>;
			assigned-clock-rates = <1152000000>,
						 <1152000000>;
			tx_delay = <16>;
			cap-mmc-crypto;
			cap-mmc-64bit-dma;
			mmc-hs400-enhanced-strobe;
		//	power-domains=<&pwrdm PDID_A9_SD_EMMC_C>;
		//	nwr_cnt = <0>;
		//	resets = <&reset RESET_SD_EMMC_C>;
		};

		sd_emmc_b: sd@fe08a000 {
			compatible = "amlogic,meson-v8-mmc";
			reg = <0x0 0xfe08a000 0x0 0x1000>,
				<0x0 0xfe000290 0x0 0x4>,
				<0x0 0xffa04010 0x0 0x4>;
			interrupts = <GIC_SPI 177 IRQ_TYPE_EDGE_RISING>;
			status = "disabled";
			clocks = <&clkc CLKID_SYS_SD_EMMC_B>,
				<&clkc CLKID_SD_EMMC_B_MUX>,
				 <&clkc CLKID_SD_EMMC_B>,
				 <&xtal>,
				 <&scmi_clk CLKID_FCLK_DIV2>;
			clock-names = "core", "mux0", "mux1",
					"clkin0", "clkin1";
			card_type = <5>;
			mmc_debug_flag;
			no-mmc;
			no-sdio;
			power-domains=<&pwrdm PWRC_A9_SD_EMMC_B_ID>;
			//resets = <&reset RESET_SD_EMMC_B>;
		};

		sd_emmc_a: sdio@fe088000 {
			compatible = "amlogic,meson-v8-mmc";
			reg = <0x0 0xfe088000 0x0 0x1000>,
				<0x0 0xfe000290 0x0 0x4>,
				<0x0 0xfe00400c 0x0 0x4>;
			interrupts = <GIC_SPI 176 IRQ_TYPE_LEVEL_HIGH>;
			status = "disabled";
			clocks = <&clkc CLKID_SYS_SD_EMMC_A>,
				<&clkc CLKID_SD_EMMC_A_MUX>,
				 <&clkc CLKID_SD_EMMC_A>,
				 <&xtal>,
				 <&scmi_clk CLKID_FCLK_DIV2>;
			clock-names = "core", "mux0", "mux1",
					"clkin0", "clkin1";
			card_type = <3>;
			mmc_debug_flag;
			cap-sdio-irq;
			keep-power-in-suspend;
			use_intf3_tuning;
			no-mmc;
			no-sd;
			power-domains=<&pwrdm PWRC_A9_SD_EMMC_A_ID>;
			//resets = <&reset RESET_SD_EMMC_A>;
		};

		mtd_nand: nfc@fe08c800 {
			compatible = "amlogic,meson-nfc-single-ecc-bl2ex";
			status = "disabled";
			reg = <0x0 0xfe08c800 0x0 0x200>;
			interrupts = <GIC_SPI 175 IRQ_TYPE_EDGE_RISING>;

			//clocks = <&clkc CLKID_SD_EMMC_C>,
			//	   <&scmi_clk CLKID_FCLK_DIV2>;
			//clock-names = "gate", "fdiv2pll";
			nand_clk_ctrl = <0xfe08c000>;
		};

		serdes0: hsgmii-phy@fe4c2000 {
			compatible = "amlogic,hsgmii-phy";
			reg = <0x0 0xfe4c2000 0x0 0x22c>;
			clocks = <&clkc CLKID_SYS_U3HSG>;
			clock-names = "hsg_general";
			resets = <&reset RESET_HSG>,
				 <&reset RESET_U3HSG_HSG>;
			reset-names = "hsg_rst", "hsg_apb_rst";
			hsg-trim-reg = <0xfe01034c>;
			u3hsg-combo-reg = <0xfe0086e0>;
			combo-hsg-sel-val = <0x0>;
			#phy-cells = <0>;
			power-domains=<&pwrdm PWRC_A9_U3HSG_HSG_ID>;
			status = "disabled";
		};

		ethmac_a: ethernet@fe498000 {
			compatible = "amlogic,meson-axg-dwmac",
				     "snps,dwmac-4.00";
			reg = <0x0 0xfe498000 0x0 0x12ec>,
			      <0x0 0xfe494000 0x0 0x2c>;
			interrupts = <GIC_SPI 75 IRQ_TYPE_LEVEL_HIGH>;
			interrupt-names = "macirq";
			clocks = <&clkc CLKID_SYS_ETH>,
				 <&scmi_clk CLKID_FCLK_DIV2>,
				 <&scmi_clk CLKID_FCLK_50M>,
				 <&clkc CLKID_SYS_PERIPH>;
			clock-names = "stmmaceth", "clkin0", "clkin1", "sys_apb";
			// resets = <&reset RESET_ETH>;
			// reset-names = "stmmaceth";
			rx-fifo-depth = <4096>;
			tx-fifo-depth = <4096>;
			mboxes = <&mbox_fifo A9_REE2AO_ETH>;
			internal_phy = <2>;
			/* ignore integrated PCS link states */
			amlogic,ignore-pcs-stats;
			power-domains=<&pwrdm PWRC_A9_ETH_ID>;
			status = "disabled";

			ext_mdio_a: mdio {
				#address-cells = <1>;
				#size-cells = <0>;
				compatible = "snps,dwmac-mdio";
				status = "disabled";

				external_phy_a: ethernet-phy@0 {
						reg = <0>;
						max-speed = <1000>;

						reset-assert-us = <20000>;
						reset-deassert-us = <50000>;
						reset-gpios = <&gpioz 15 (GPIO_ACTIVE_LOW |
									GPIO_OPEN_DRAIN)>;
						realtek,clkout-disable;
						realtek,aldps-enable;
				};
			};
		};

		ethmac_b: ethernet@fe4e8000 {
			compatible = "amlogic,meson-axg-dwmac",
				     "snps,dwmac-4.00";
			reg = <0x0 0xfe4e8000 0x0 0x12ec>,
			      <0x0 0xfe4e4000 0x0 0x2c>;
			interrupts = <GIC_SPI 190 IRQ_TYPE_LEVEL_HIGH>;
			interrupt-names = "macirq";
			clocks = <&clkc CLKID_SYS_ETH_1G_MAC>,
				 <&scmi_clk CLKID_FCLK_DIV2>,
				 <&scmi_clk CLKID_FCLK_50M>,
				 <&clkc CLKID_SYS_PERIPH>;
			clock-names = "stmmaceth", "clkin0", "clkin1", "sys_apb";
			// resets = <&reset RESET_ETH_1G>;
			// reset-names = "stmmaceth";
			rx-fifo-depth = <4096>;
			tx-fifo-depth = <4096>;
			mboxes = <&mbox_fifo A9_REE2AO_ETH>;
			// amlogic,smc-id = <0x8200009d>;
			internal_phy = <2>;
			power-domains=<&pwrdm PWRC_A9_ETH_1G_ID>;
			status = "disabled";

			ext_mdio_b: mdio {
				#address-cells = <1>;
				#size-cells = <0>;
				compatible = "snps,dwmac-mdio";
				status = "disabled";

				external_phy_b: ethernet-phy@0 {
						reg = <0>;
						max-speed = <1000>;

						reset-assert-us = <20000>;
						reset-deassert-us = <50000>;
						reset-gpios = <&gpioa 15 (GPIO_ACTIVE_LOW |
									GPIO_OPEN_DRAIN)>;
						realtek,clkout-disable;
						realtek,aldps-enable;
				};
			};
		};

		uart_A: serial@fe078000 {
			compatible = "amlogic,meson-uart";
			reg = <0x0 0xfe078000 0x0 0x18>;
			interrupts = <GIC_SPI 168 IRQ_TYPE_EDGE_RISING>;
			status = "disabled";
			clocks = <&xtal>,
				 <&clkc CLKID_SYS_UART_A>;
			clock-names = "clk_uart", "clk_gate";
			fifosize = < 64 >;
			pinctrl-names = "default";
			pinctrl-0 = <&a_uart_pins>;
		};

		uart_F: serial@fe082000 {
			compatible = "amlogic,meson-uart";
			reg = <0x0 0xfe082000 0x0 0x18>;
			interrupts = <GIC_SPI 167 IRQ_TYPE_EDGE_RISING>;
			status = "disabled";
			clocks = <&xtal>,
				 <&clkc CLKID_SYS_UART_F>;
			clock-names = "clk_uart", "clk_gate";
			fifosize = < 64 >;
			pinctrl-names = "default";
			pinctrl-0 = <&f_uart_pins>;
		};
	};

	mesonstream {
		compatible = "amlogic, codec, streambuf";
		dev_name = "mesonstream";
		status = "okay";
	};

	vcodec_dos_dev: vcodec_dos_dev {
		compatible = "amlogic, cpu-major-id-a9";
		dev_name = "vcodec_dos_dev";
		status = "okay";
		reg = <0x0 0xfe320000 0x0 0x10000>,
			<0x0 0xfe036000 0x0 0x2000>,
			<0x0 0xfe010000 0x0 0x2000>;
		reg-names = "dosbus",
			"dmcbus",
			"sysctrl";
		clocks = <&clkc CLKID_SYS_DOS>,
			 <&clkc CLKID_HCODEC>,
			 <&clkc CLKID_HEVCF>;
		clock-names = "vdec",
			"clk_hcodec_mux",
			"clk_hevcf_mux";
		assigned-clocks = <&scmi_clk CLKID_GP1_PLL>;
		assigned-clock-rates = <852000000>;
	};

	vdec {
		compatible = "amlogic, vdec-pm-pd";
		dev_name = "vdec.0";
		status = "okay";
		interrupts = <0 3 1
			0 155 1
			0 32 1
			0 87 1
			0 88 1
			0 89 1
			0 252 1
			0 201 1
			0 113 1>;
		interrupt-names = "vsync",
			"demux",
			"parser",
			"mailbox_0",
			"mailbox_1",
			"mailbox_2",
			"assist_mbox_irq_ee",
			"viff_empty",
			"axi_monitor";
		power-domains = <&pwrdm PWRC_A9_DOS_HEVC_ID>,
			<&pwrdm PWRC_A9_DOS_HCODEC_ID>;
		power-domain-names = "pwrc-hevc",
			"pwrc-hcodec";
		reset-names = "hevcf_dmc_pipel";
		resets = <&reset RESET_BRG_HEVCF_DMC_PIPEL>;
	};

	vcodec_dec {
		compatible = "amlogic, vcodec-dec";
		dev_name = "aml-vcodec-dec";
		status = "okay";
	};

	ddr_bandwidth {
		compatible = "amlogic,ddr-bandwidth-a9";
		status = "okay";
		reg = <0x0 0xfe036000 0x0 0x1000
		       0x0 0xfe036ca8 0x0 0x4>;
		interrupts = <0 78 IRQ_TYPE_EDGE_RISING>;
		interrupt-names = "ddr_bandwidth";
	};

	dmc_monitor {
		compatible = "amlogic,dmc_monitor-a9";
		status = "okay";
		memory-region = <&dmc_reserved>;
		reg = <0x0 0xfe036000 0x0 0x1000>;
		reg_base = <0xfe036000>;
		interrupts = <0 62 IRQ_TYPE_LEVEL_HIGH
			      0 61 IRQ_TYPE_EDGE_RISING>;
	};

	tx_venc: tx_venc {
		compatible = "amlogic, tx-venc-a9";
		status = "okay";
		reg = <0x0 0xFF500000 0x0 0x3ffff>;
		reg-names = "vcbus";
		venc_offset = <0x0 0x600>;
	};

	tx_phy: tx_phy {
		compatible = "amlogic, tx-phy-a9";
		reg = <0x0 0xfe008000 0x0 0x1000>,
		      <0x0 0xfe48c000 0x0 0x100>;
		reg-names = "anactrl_typec_dp_reg", "dpphy_ctrl_reg";
		dptx-aux-gpios = <&gpiocc 0 GPIO_ACTIVE_HIGH
				  &gpiocc 1 GPIO_ACTIVE_HIGH>;
		status = "okay";
	};

	dptx_clk: dptx_clk {
		compatible = "amlogic, tx-clk-a9";
		status = "okay";
		reg = <0x0 0xFE016000 0x0 0x2000
			0x0 0xfe000000 0x0 0x2000>;
		reg-names = "ana_ctrl",
			"clk_ctrl";
	};

	dptx: dptx {
		compatible = "amlogic, dptx-a9";
		dev_name = "dptx";
		status = "disabled";
		tx_phy = <&tx_phy>;
		tx_clk = <&dptx_clk>;
		dev_index = <0>;
		interrupts = <GIC_SPI 285 IRQ_TYPE_LEVEL_HIGH
			GIC_SPI 286 IRQ_TYPE_LEVEL_HIGH>;
		interrupt-names = "apb_dp_int", "hdcp2tx_intr";

		reg = <0x0 0xFE484000 0x0 0x2000
			0x0 0xFE010000 0x0 0x2000
			0x0 0xFE016000 0x0 0x2000
			0x0 0xFE00C000 0x0 0x2000
			0x0 0xFE002000 0x0 0x2000
			0x0 0xFE000000 0x0 0x2000
			0x0 0xFF500000 0x0 0x3ffff
			0x0 0xFE004000 0x0 0x2000>;
		reg-names = "dptx",
			"sys_ctrl",
			"ana_ctrl",
			"pwr_ctrl",
			"reset_ctrl",
			"clk_ctrl",
			"vpu_ctrl",
			"pad_ctrl";
		ports {
			port {
				#address-cells = <1>;
				#size-cells = <0>;
				dptx_to_drm: endpoint@0 {
					reg = <0>;
					remote-endpoint = <0>;
				};
			};
		};
	};

	/* Used by the edptx driver */
	dptx_core: dptx_core {
		compatible = "amlogic, dptx-core-a9";
		dev_name = "dptx_core";
		status = "disabled";
		tx_phy = <&tx_phy>;
		tx_clk = <&dptx_clk>;
		dev_index = <1>;

		reg = <0x0 0xFE074000 0x0 0x2000
			0x0 0xFE010000 0x0 0x2000
			0x0 0xFE016000 0x0 0x2000
			0x0 0xFE00C000 0x0 0x2000
			0x0 0xFE002000 0x0 0x2000
			0x0 0xFE000000 0x0 0x2000
			0x0 0xFF500000 0x0 0x3ffff
			0x0 0xFE004000 0x0 0x2000>;
		reg-names = "edptx",
			"sys_ctrl",
			"ana_ctrl",
			"pwr_ctrl",
			"reset_ctrl",
			"clk_ctrl",
			"vpu_ctrl",
			"pad_ctrl";
		ports {
			port {
				#address-cells = <1>;
				#size-cells = <0>;
				edp_to_drm: endpoint@0 {
					reg = <0>;
					remote-endpoint = <0>;
				};
			};
		};
	};

	amhdmitx: amhdmitx{
		compatible = "amlogic, amhdmitx-a9";
		dev_name = "amhdmitx";
		status = "disabled";
		//power-domains = <&pwrdm PDID_T7_VI_CLK2>;
		vend-data = <&vend_data>;
		pinctrl-names="hdmitx_hpd", "hdmitx_ddc";
		pinctrl-0=<&hdmitx_hpd>;
		pinctrl-1=<&hdmitx_ddc>;
		hdmitx-gpios-hpd = <&gpioh 6 GPIO_ACTIVE_HIGH>;
		hdmitx-gpios-scl = <&gpioh 5 GPIO_ACTIVE_HIGH>;
		hdmitx-gpios-sda = <&gpioh 4 GPIO_ACTIVE_HIGH>;
		interrupts = <GIC_SPI 204 IRQ_TYPE_LEVEL_HIGH
			GIC_SPI 197 IRQ_TYPE_EDGE_RISING>;
		interrupt-names = "hdmitx_hpd", "hdmitx_vsync";
		enc_idx = <0>;
		max_refresh_rate = <120>; /* the max fresh_rate of A9 is upto 120hz */
		reg =	<0x0 0xff500000 0x0 0x40000>,
			<0x0 0xfe310000 0x0 0x10000>,
			<0x0 0xfe300000 0x0 0x10000>,
			<0x0 0xfe010000 0x0 0x2000>,
			<0x0 0xfe00c000 0x0 0x2000>,
			<0x0 0xfe008000 0x0 0x2000>,
			<0x0 0xfe002000 0x0 0x2000>,
			<0x0 0xfe000000 0x0 0x2000>,
			<0x0 0xfe004000 0x0 0x2000>;
		reg-names = "vpu",
			    "hdmitxcor",
			    "hdmitxtop",
			    "sysctrl",
			    "pwrctrl",
			    "anactrl",
			    "resetctrl",
			    "clkctrl",
			    "padctrl";
		frac_enable = <1>;

		vend_data: vend_data{ /* Should modified by Customer */
			vendor_name = "CUS_NAME"; /* Max Chars: 8 */
			product_desc = "PRODUCT_NAME"; /* Max Chars: 16 */
			/* standards.ieee.org/develop/regauth/oui/oui.txt */
			vendor_id = <0x000000>;
		};

		ports {
			port {
				#address-cells = <1>;
				#size-cells = <0>;
				hdmitx_to_drm: endpoint@0 {
					reg = <0>;
					remote-endpoint = <0>;
				};
			};
		};
	};

	aocec: aocec {
		compatible = "amlogic, aocec-a9";
		dev_name = "aocec";
		status = "okay";
		vendor_name = "Amlogic"; /* Max Chars: 8     */
		/* Refer to the following URL at:
		 * http://standards.ieee.org/develop/regauth/oui/oui.txt
		 */
		vendor_id = <0xffffff>;
		product_desc = "A9"; /* Max Chars: 16    */
		cec_osd_string = "AML_MBOX"; /* Max Chars: 14    */
		cec_version = <5>;/*5:1.4;6:2.0*/
		port_num = <1>;
		cec_sel = <1>;/*1:use one ip, 2:use 2 ip*/
		ee_cec;
		arc_port_mask = <0x1>;
		interrupts = <GIC_SPI 407 IRQ_TYPE_EDGE_RISING>;/*1:ts*/
		interrupt-names = "hdmi_aocecb";
		pinctrl-names = "default","hdmitx_aocecb","cec_pin_sleep";
		pinctrl-0=<&eecec_b>;
		pinctrl-1=<&eecec_b>;
		pinctrl-2=<&eecec_b>;
		clocks = <&ao_clkc CLKID_AO_CECB_CLK>;
		clock-names = "cecb_clk";
		assigned-clocks = <&ao_clkc CLKID_AO_CECB_DUAL>;
		assigned-clock-rates = <32768>;
		reg = <0x0 0xffa16000 0x0 0x2ff
		       0x0 0xfe010000 0x0 0xfff
		       0x0 0xffa00000 0x0 0xfff
		       0x0 0xfe004000 0x0 0x2000>;
		reg-names = "ao","periphs","clock","pad_reg";
		mbox-names = "mbox_cec";
		mboxes = <&mbox_fifo A9_REE2AO_AOCEC>;
	};

	aml_dma {
		compatible = "amlogic,aml_p1_dma";
		reg = <0x0 0xfe440400 0x0 0x48>;
		interrupts = <0 24 1>;
		dma_bus64 = /bits/ 8 <0x1>;

		aml_aes {
			compatible = "amlogic,aes_g12a_dma";
			dev_name = "aml_aes_dma";
			status = "okay";
			iv_swap = /bits/ 8 <0x0>;
		};

		aml_sha {
			compatible = "amlogic,sha_dma";
			dev_name = "aml_sha_dma";
			hw_ctx_sz = /bits/ 32 <0x28>;
			status = "okay";
		};

		aml_sha3 {
			compatible = "amlogic,sha3_dma";
			dev_name = "aml_sha3_dma";
			status = "okay";
		};

		aml_tdes {
			compatible = "amlogic,des_dma,tdes_dma";
			dev_name = "aml_tdes_dma";
			status = "okay";
		};

		aml_sm4 {
			compatible = "amlogic,sm4_dma";
			dev_name = "aml_sm4_dma";
			status = "okay";
			iv_swap = /bits/ 8 <0x0>;
		};

		crypto {
			compatible = "amlogic,crypto_s5";
			dev_name = "aml_crypto_dev";
			status = "okay";
			thread = /bits/ 8 <0x1>;
			interrupts = <0 25 1>;
		};
	};

	rng {
		compatible = "amlogic,meson-rng";
		status = "okay";
		#address-cells = <2>;
		#size-cells = <2>;
		reg = <0x0 0xfe440788 0x0 0x0c>;
		quality = /bits/ 16 <1000>;
		version = <2>;
	};

	canvas: canvas{
		compatible = "amlogic, meson, canvas";
		status = "okay";
	};

	codec_io: codec_io {
		compatible = "amlogic, meson-a9, codec-io";
		status = "okay";
		#address-cells=<2>;
		#size-cells=<2>;
		ranges;
		reg =	<0x0 0xfe002000 0x0 0x2000>,
			<0x0 0xfe320000 0x0 0x10000>,
			<0x0 0x0 0x0 0x0>,
			<0x0 0x0 0x0 0x00>,
			<0x0 0xff500000 0x0 0x40000>,
			<0x0 0xfe036000 0x0 0x2000>,
			<0x0 0x0 0x0 0x0>;
		reg-names = "cbus",
			    "dosbus",
			    "hiubus",
			    "aobus",
			    "vcbus",
			    "dmcbus",
			    "efusebus";
	};

	tahoe_enc {
		compatible = "amlogic, tahoe";
		dev_name = "tahoe";
		status = "okay";
		clocks = <&clkc CLKID_HCODEC>;
		clock-names = "clk_tahoe";
		interrupts = <GIC_SPI 259 IRQ_TYPE_EDGE_RISING>;
		interrupt-names = "tahoe_irq0";
		power-domains = <&pwrdm PWRC_A9_TAHOE_ID>;
		reset-names = "tahoe_core_rst", "tahoe_a_rst", "tahoe_apb_rst", "tahoe_sys_rst";
		resets = <&reset RESET_TAHOE_CORE>,
			<&reset RESET_TAHOE>,
			<&reset RESET_TAHOE_APB>,
			<&reset RESET_TAHOE_SYS>;
		#address-cells=<2>;
		#size-cells=<2>;
		ranges;
		io_reg_base {
			reg = <0x0 0xfe370000 0x0 0x10000>;
		};
	};

	jpegenc{
		compatible = "amlogic, jpegenc";
		dev_name = "jpegenc";
		status = "okay";
		clocks = <&clkc CLKID_SYS_DOS>,
			<&clkc CLKID_HCODEC>;
		clock-names =
			"clk_dos",
			"clk_jpeg_enc";

		power-domains = <&pwrdm PWRC_A9_DOS_HCODEC_ID>;
		interrupts = <0 87 1 0 88 1 0 89 1>;
		interrupt-names = "dos_mbox_slow_irq0", "dos_mbox_slow_irq1", "dos_mbox_slow_irq2";
		//reset-names = "jpegenc_rst";
		//resets = <&reset RESET_BRG_HCODEC_PIPL0>;
	};

	vpu: vpu {
		compatible = "amlogic, vpu-a9";
		status = "okay";
		reg =	<0x0 0xfe000000 0x0 0x2000    /* clk */
			 0x0 0xfe00c000 0x0 0x70     /* pwrctrl */
			 0x0 0xff500000 0x0 0x40000>; /* vcbus */
		clocks = <&clkc CLKID_VAPB>,
			 <&clkc CLKID_VPU>;
		clock-names =	"vapb_clk",
				"vpu_clk";
		clk_level = <8>;
		/* 0: 24.0M  1: 100.0M    2: 166.7M    3: 200.0M    4: 250.0M */
		/* 5: 333.3M    6: 400.0M    7: 500.0M    8: 666.7M */
	};

	rdma {
		compatible = "amlogic, meson-t3, rdma";
		status = "okay";
		interrupts = <GIC_SPI 215 IRQ_TYPE_EDGE_RISING>;
		interrupt-names = "rdma";
		/* after sc2 */
		reset-names = "rdma";
		resets = <&reset RESET_RDMA>;
		rdma_table_page_count = <16>;
	};

	amlvecm: amlvecm {
		compatible = "amlogic, vecm-a9";
		dev_name = "aml_vecm";
		status = "okay";
		gamma_en = <0>;/*1:enable ;0:disable*/
		wb_en = <0>;/*1:enable ;0:disable*/
		/*0: 709/601  1: bt2020*/
		tx_op_color_primary = <0>;
	};

	aml_primesl {
		compatible = "amlogic, prime_sl_a9";
		dev_name = "amprime_sl";
		status = "okay";
	};

	multi-di {
		compatible = "amlogic, dim-a9";
		/* s6 same as s7d */
		status = "okay";
		/* 0:use reserved; 1:use cma; 2:use cma as reserved */
		flag_cma = <4>;	//<1>;
		//memory-region = <&di_reserved>;
		//memory-region = <&di_cma_reserved>;
		interrupts = <0 203 1
				0 202 1>;
		interrupt-names = "pre_irq", "post_irq";
		clocks = <&clkc CLKID_VPU_CLKB>,
			 <&clkc CLKID_VPU>;
		clock-names = "vpu_clkb",
			"vpu_mux";
		clock-range = <334 400>;
		/* buffer-size = <3621952>;(yuv422 8bit) */
		buffer-size = <4074560>;/*yuv422 fullpack*/
		/* reserve-iomap = "true"; */
		/* if enable nr10bit, set nr10bit-support to 1 */
		post-wr-support = <1>;
		nr10bit-support = <1>;
		nrds-enable = <1>;
		pps-enable = <1>;
		en_4k = <0>;
		keep_dec_vf = <0>;
		po_fmt = <0>;
		post_nub = <11>;
		alloc_sct = <0>;
		hf = <0>;
		dct = <0>;
		sub_v = <0>;//sub version
		afbce_loss_en = <0>;//t5w loss mode enable for DI output
		prelink_en = <0>;
		ponly_mode = <0>;
		t5db_afbcd_en = <1>;
		postlink_en = <0>;
		/***************************************************
		 * t5w t3 support 4k ,same with t7 ,no canvas,
		 * post_nub---default is 11
		 *            (T7/T3/SC2/S4 new path)
		 *            post 11*5222400 = 56M,local 7*4075520 = 28m
		 * flag_cma---0: use reserved; 1:use cma;
		 *            2:use cma as reserved 4:use codec mem
		 * en_4k :en_4k---0: not support 4K;  1: enable 4K
		 *                2: dynamic: vdin: 4k enable,
		 *                   other source 4k disable
		 *                8: when 4k,
		 *                   output with a resolution is below 1080p
		 * keep_dec_vf---0:not keep; 1: keep dec vf for p;
		 *               2: dynamic keep dec vf for p,other is disable
		 * po_fmt---1: NV21/8;  2: nv12/8;  3: AFBC 422/10BIT;
		 *          4: dynamic(4K AFBC,10/422);
		 *          6: dynamic(from decoder 4K source,
		 *             out is AFBC,10/420),
		 *             other is 422/10BIT
		 * bypass_mem---0:nr not bypass; 1: nr bypass;
		 *              2: when 4k input ,nr is bypass;
		 *              3: bypass nr for 4k,but not from vdin;
		 * alloc_sct---0:not support; bit 0: for 4k; bit 1: for 1080p
		 * hf---0:not enable; 1: enable
		 * dct---0:not enable; 1: enable 1 ch; 2: enable 2 ch
		 * sub_v---0:major; 1: sub
		 * afbce_loss_en---1:check the loss flag in vf and set for di,0:disable
		 ***************************************************/
	};

	vclk_serve: vclk_serve {
		compatible = "amlogic, vclk_serve";
		status = "okay";
		reg = <0x0 0xfe008000 0x0 0x400    /* ana reg */
			0x0 0xfe000000 0x0 0x590>; /* clk reg */
	};

	vout_sys: vout_sys {
		compatible = "amlogic, vout_sys_serve";
		status = "okay";
		reg = <0x0 0xfe01029c 0x0 0x4>;
	};

	vdac {
		compatible = "amlogic, vdac-s4d";
		status = "disabled";
	};

	vout: vout {
		compatible = "amlogic, vout";
		status = "okay";

		/* fr_policy:
		 *    0: disable
		 *    1: nearby (only for 60->59.94 and 30->29.97)
		 *    2: force (60/50/30/24/59.94/23.97)
		 */
		fr_policy = <2>;
	};

	vout2: vout2 {
		compatible = "amlogic, vout2";
		status = "okay";

		/* fr_policy:
		 *    0: disable
		 *    1: nearby (only for 60->59.94 and 30->29.97)
		 *    2: force (60/50/30/24/59.94/23.97)
		 */
		fr_policy = <2>;
	};

	vout_mux: vout_mux {
		compatible = "amlogic, vout_mux-t7";
		status = "okay";
		clocks = <&scmi_clk CLKID_FCLK_DIV5>, <&clkc CLKID_VDIN_MEAS>;
		clock-names = "fclk_div5", "vdin_meas_clk";
	};

	dummy_venc: dummy_venc {
		compatible = "amlogic, dummy_venc_a9";
		status = "okay";

		ports {
			port {
				#address-cells = <1>;
				#size-cells = <0>;
				dummyl_to_drm: endpoint@0 {
					reg = <0>;
					remote-endpoint = <0>;
				};
			};
		};
	};

	adc: adc {
		compatible = "amlogic, adc-s4d";
		status = "disabled";
		reg = <0x0 0xff654000 0x0 0x2000/* afe reg base */
			0x0 0xfe008000 0x0 0x2000/* hiu base */
			>;
	};

	ir: ir@8000 {
		compatible = "amlogic, meson-ir";
		reg = <0x0 0xffa14080 0x0 0xA4>,
			<0x0 0xffa14000 0x0 0x58>;
		status = "disable";
		protocol = <REMOTE_TYPE_NEC>;
		interrupts = <GIC_SPI 413 IRQ_TYPE_EDGE_RISING>;
		map = <&custom_maps>;
		wakeup_map = <&ir_wakeup_key>;
		mboxes = <&mbox_fifo A9_REE2AO_IR>;
		max_frame_time = <200>;
	};

	cpu_tsensor: cpu_tsensor@fe028000 {
		compatible = "amlogic,a9-cpu-thermal";
		status = "okay";
		reg = <0x0 0xfe028000 0x0 0x50>;
		clocks = <&clkc CLKID_TS>;
		clock-names = "ts_comp";
		reset-temp = <110000>;
		amlogic,ao-secure = <&secao_tsens>;
		#thermal-sensor-cells = <0>;
	};

	core_tsensor: core_tsensor@fe022000 {
		compatible = "amlogic,a9-core-thermal";
		status = "okay";
		reg = <0x0 0xfe022000 0x0 0x50>;
		clocks = <&clkc CLKID_TS>;
		clock-names = "ts_comp";
		reset-temp = <110000>;
		amlogic,ao-secure = <&secao_tsens>;
		#thermal-sensor-cells = <0>;
	};

	p_tsensor: p_tsensor@fe020000 {
		compatible = "amlogic,a9-pll-thermal";
		status = "okay";
		reg = <0x0 0xfe020000 0x0 0x50>;
		clocks = <&clkc CLKID_TS>;
		clock-names = "ts_comp";
		reset-temp = <110000>;
		amlogic,ao-secure = <&secao_tsens>;
		#thermal-sensor-cells = <0>;
	};

	dos_tsensor: dos_tsensor@fe02a000 {
		compatible = "amlogic,a9-dos-thermal";
		status = "okay";
		reg = <0x0 0xfe02a000 0x0 0x50>;
		clocks = <&clkc CLKID_TS>;
		clock-names = "ts_comp";
		reset-temp = <110000>;
		amlogic,ao-secure = <&secao_tsens>;
		#thermal-sensor-cells = <0>;
	};

	meson_cooldev: meson-cooldev@0 {
			status = "okay";
			compatible = "amlogic, meson-cooldev";
			cooling_devices {
				gpufreq_cool {
					dyn_coeff = <140>;
					node_name = "avalon";
					device_type = "gpufreq";
				};
			};
		};/*meson cooling devices end*/

	thermal-zones {
		soc_thermal: soc_thermal {
			polling-delay = <1000>;
			polling-delay-passive = <100>;
			sustainable-power = <1760>;
			thermal-sensors = <&cpu_tsensor>;
			trips {
				cpu_switch_on: trip-point@0 {
					temperature = <85000>;
					hysteresis = <5000>;
					type = "passive";
				};
				cpu_control: trip-point@1 {
					temperature = <95000>;
					hysteresis = <5000>;
					type = "passive";
				};
				cpu_critical: trip-point@2 {
					temperature = <105000>;
					hysteresis = <1000>;
					type = "critical";
				};
			};
			cooling-maps {
				a78_cooling_map {
					trip = <&cpu_control>;
					cooling-device = <&CPU6 0 8>;
					contribution = <1024>;
				};
			};
		};

		c_thermal: c_thermal {
			polling-delay = <1000>;
			polling-delay-passive = <100>;
			sustainable-power = <695>;
			thermal-sensors = <&core_tsensor>;
			trips {
				c_switch_on: trip-point@0 {
					temperature = <85000>;
					hysteresis = <5000>;
					type = "passive";
				};
				c_control: trip-point@1 {
					temperature = <95000>;
					hysteresis = <5000>;
					type = "passive";
				};
				c_critical: trip-point@2 {
					temperature = <105000>;
					hysteresis = <1000>;
					type = "critical";
				};
			};

			cooling-maps {
				gpu_cooling_map {
					trip = <&c_control>;
					cooling-device = <&gpu 0 3>;
					contribution = <1024>;
				};
				a55_cooling_map {
					trip = <&c_control>;
					cooling-device = <&CPU0 0 6>;
					contribution = <1024>;
				};
			};
		};

		pll_thermal: pll_thermal {
			polling-delay = <1000>;
			polling-delay-passive = <100>;
			sustainable-power = <1160>;
			thermal-sensors = <&p_tsensor>;
			trips {
				p_switch_on: trip-point@0 {
					temperature = <85000>;
					hysteresis = <5000>;
					type = "passive";
				};
				p_control: trip-point@1 {
					temperature = <95000>;
					hysteresis = <5000>;
					type = "passive";
				};
				p_critical: trip-point@2 {
					temperature = <105000>;
					hysteresis = <1000>;
					type = "critical";
				};
			};
		};

		dos_thermal: dos_thermal {
			polling-delay = <1000>;
			polling-delay-passive = <100>;
			sustainable-power = <1160>;
			thermal-sensors = <&dos_tsensor>;
			trips {
				dos_switch_on: trip-point@0 {
					temperature = <85000>;
					hysteresis = <5000>;
					type = "passive";
				};
				dos_control: trip-point@1 {
					temperature = <95000>;
					hysteresis = <5000>;
					type = "passive";
				};
				dos_critical: trip-point@2 {
					temperature = <105000>;
					hysteresis = <1000>;
					type = "critical";
				};
			};
		};
	};/*thermal zone end*/

	ion_dev {
		compatible = "amlogic, ion_dev";
		memory-region = <&ion_cma_reserved
				&ion_fb_reserved>;
	};

	gpu_protected_memory_allocator: protected-memory-allocator {
		compatible = "arm,protected-memory-allocator";
		memory-region = <&mali_protected>;
	};

	meson_uvm {
		compatible = "amlogic, meson_uvm";
		status = "okay";
		enable_screencap = <1>;
	};

	meson_videotunnel{
		compatible = "amlogic, meson_videotunnel";
		status = "okay";
	};

	fb: fb {
		compatible = "amlogic, fb-s6";
		memory-region = <&logo_reserved>;
		status = "disabled";
		interrupts = <GIC_SPI 197 IRQ_TYPE_EDGE_RISING
			GIC_SPI 194 IRQ_TYPE_EDGE_RISING
			GIC_SPI 215 IRQ_TYPE_EDGE_RISING>;
		interrupt-names = "viu-vsync", "viu2-vsync", "rdma";
		/* uboot logo,fb0/fb1 memory size,if afbcd fb0=0x01851000*/
		display_mode_default = "1080p60hz";
		scale_mode = <1>;
		/** 0:VPU free scale 1:OSD free scale 2:OSD super scale */
		display_size_default = <1920 1080 1920 2160 32>;
		/*1920*1080*4*3 = 0x17BB000*/
		display_device_cnt = <2>;
		//clocks = <&clkc CLKID_VPU_CLKC>;
		clock-names = "vpu_clkc";
	};

	irblaster: meson-irblaster@fe08414c {
		compatible = "amlogic, meson_irblaster";
		status = "disabled";
		reg = <0x0 0xfe08414c 0x0 0x10>;
		#irblaster-cells = <2>;
		interrupts = <GIC_SPI 81 IRQ_TYPE_EDGE_RISING>;
	};

	hdmirx: hdmirx {
		compatible = "amlogic, hdmirx_a9";
		#address-cells=<1>;
		#size-cells=<1>;
		/*memory-region = <&hdmirx_emp_cma_reserved>;*/
		status = "okay";
		pinctrl-names = "hdmirx_pins";
		pinctrl-0 = <&hdmirx_a_mux>;
		repeat = <0>;
		/*power-domains = <&pwrdm PDIP_T6D_VPU_HDMI>;*/
		interrupts = <0 284 IRQ_TYPE_LEVEL_HIGH>;
		clocks = <&clkc CLKID_HDMIRX_CFG>,
			<&clkc CLKID_HDMIRX_ACR_REF>,
			<&clkc CLKID_HDMIRX_METER>,
			<&clkc CLKID_HDMIRX_2M>,
			<&clkc CLKID_HDMIRX_5M>,
			<&clkc CLKID_HDMIRX_HDCP2X>,
			<&xtal>,
			<&scmi_clk CLKID_FCLK_DIV4>,
			<&scmi_clk CLKID_FCLK_DIV5>;
		clock-names = "hdmirx_cfg_clk",
				"cts_hdmirx_acr_ref_clk",
				"cts_hdmirx_meter_clk",
				"cts_hdmirx_2m_clk",
				"cts_hdmirx_5m_clk",
				"cts_hdmirx_hdcp2x_eclk",
				"xtal",
				"fclk_div4",
				"fclk_div5";
		//power-domains = <&pwrdm 2>;
		hdmirx_id = <0>;
		en_4k_2_2k = <0>;
		hpd_low_cec_off = <1>;
		arc_port = <0>;
		vrr_range_dynamic_update_en = <1>;
		/* bit4: enable feature, bit3~0: port number */
		disable_port = <0x0>;
		/* MAP_ADDR_MODULE_CBUS */
		/* MAP_ADDR_MODULE_HIU */
		/* MAP_ADDR_MODULE_HDMIRX_CAPB3 */
		/* MAP_ADDR_MODULE_SEC_AHB */
		/* MAP_ADDR_MODULE_SEC_AHB2 */
		/* MAP_ADDR_MODULE_APB4 */
		/* MAP_ADDR_MODULE_TOP */
		/* MAP_ADDR_MODULE_CLK_CTRL */
		/* MAP_ADDR_MODULE_ANA_CTRL */
		reg = < 0x0 0x0 0x0 0x0
			0x0 0x0 0x0 0x0
			0x0 0x0 0x0 0x0
			0x0 0x0 0x0 0x0
			0x0 0x0 0x0 0x0
			0x0 0x0 0x0 0x0
			0x0 0xfe400000 0x0 0x18000
			0x0 0xfe000000 0x0 0x2000
			0x0 0xfe008000 0x0 0x2000>;
	};

	/*if you want to use vdin just modify status to "ok"*/
	vdin0: vdin0 {
		compatible = "amlogic, vdin-a9";
		dev_name = "vdin0";
		status = "okay";
		reserve-iomap = "true";
		/*bit8: 0-total buffer num apply,1-one buffer apply*/
		flag_cma = <0x30101>;/*1:share with codec_mm;2:cma alone*/
		/*MByte, if 10bit disable: 64M(YUV422),
		 *if 10bit enable: 64*1.5 = 96M(YUV422)
		 *if support 4K2K-YUV444-10bit-WR:3840*2160*4*4 ~= 128M
		 *if support 4K2K-YUV422-10bit-wr:3840*2160*3*4 ~= 96M
		 *if support 4K2K-YUV422-8BIT-WR:3840*2160*2*4 ~= 64M
		 *if support 1080p-YUV422-8BIT-WR:1920*1080*2*4 ~= 16M
		 */
		/*cma_size = <16>;*/
		interrupts = <0 210 1>;
		interrupt-names = "vsync_int";
		rdma-irq = <2>;
		clocks = <&scmi_clk CLKID_FCLK_DIV5>, <&clkc CLKID_VDIN_MEAS>;
		clock-names = "fclk_div5", "cts_vdin_meas_clk";
		vdin_id = <0>;
		tv_bit_mode = <0x235>;
		afbce_bit_mode = <0x11>;
		chk_wr_done_en;
		/* urgent_en; */
		double_write_en;
		/* vdin v4l2 */
		v4l_support_en = <0>;
		v4l_vd_num = <70>;
		/* v4l2 capability */
		driver   = "vdin_video";
		card     = "meson-a9";
		bus_info = "vdin0 v4l2";
		version  = <0x20260423>;
		/* fe_ports refer to tvin.h */
		fe_ports = <0x00001001   /* CVBS1 */
			0x00010000   /* MIPI */
			0x00004000   /* HDMI0 */
			0x00004001   /* HDMI1 */
			0x00004002>; /* HDMI2 */
		/* vdin v4l2 end */
	};
	vdin1: vdin1 {
		compatible = "amlogic, vdin-a9";
		dev_name = "vdin1";
		status = "okay";
		reserve-iomap = "true";
		/* flag_cma = <0x30101>;1:share with codec_mm;0:cma alone;bit16:scatter*/
		interrupts = <0 212 1>;
		interrupt-names = "vsync_int";
		rdma-irq = <4>;
		clocks = <&scmi_clk CLKID_FCLK_DIV5>, <&clkc CLKID_VDIN_MEAS>;
		clock-names = "fclk_div5", "cts_vdin_meas_clk";
		vdin_id = <1>;
		tv_bit_mode = <0x215>;
		afbce_bit_mode = <0x0>;
		chk_wr_done_en;
		double_write_en;
		/* vdin v4l2 */
		v4l_support_en = <0>;
		v4l_vd_num = <71>;
		/* v4l2 capability */
		driver   = "vdin_video";
		card     = "meson-a9";
		bus_info = "vdin1 v4l2";
		version  = <0x20251030>;
		/* fe_ports refer to tvin.h */
		fe_ports = <0x0000a002   /* WB0_VD1 */
			0x0000a003   /* WB0_VD2 */
			0x0000a004   /* WB0_OSD1 */
			0x0000a005   /* WB0_OSD2 */
			0x0000a006   /* WB0_VPP */
			0x0000a007   /* WB0_VDIN_BIST */
			0x0000a008   /* WB0_POST_BLEND */
			0x0000a001>; /* VIDEO */
		/* vdin v4l2 end */
	};

	amvideom: meson-amvideom {
		compatible = "amlogic, amvideom-a9";
		dev_name = "amvideom";
		status = "okay";
		interrupts = <GIC_SPI 197 IRQ_TYPE_EDGE_RISING
			GIC_SPI 194 IRQ_TYPE_EDGE_RISING>;
		interrupt-names = "vsync", "vsync_viu2";
	};

	lut_dma:lut_dma {
		compatible = "amlogic, meson-s5, lut_dma";
		status = "okay";
	};

	v2d {
		compatible = "amlogic, v2d";
		vpu_dma_mask = <1>;  /* 0: <= 4G, 1: > 4G*/
		dev_name = "v2d";
		status = "okay";
	};

	videodisplay {
		compatible = "amlogic, videodisplay";
		vpu_dma_mask = <1>;  /* 0: <= 4G, 1: > 4G*/
		dev_name = "videodisplay";
		status = "okay";
	};

	video_composer {
		compatible = "amlogic, video_composer";
		vpu_dma_mask = <1>;  /* 0: <= 4G, 1: > 4G*/
		dev_name = "video_composer";
		status = "okay";
	};

	di_process {
		compatible = "amlogic, di_process";
		dev_name = "di_process";
		status = "okay";
	};

	vpu_security {
		compatible = "amlogic, meson-t6d, vpu_security";
		dev_name = "amlogic-vpu-security";
		status = "okay";
		interrupts = <GIC_SPI 220 IRQ_TYPE_EDGE_RISING>;
		interrupt-names = "vpu_security";
	};

	dmx_aucpu: aucpu {
		compatible = "amlogic, aucpu";
		dev_name = "aml_aucpu";
		status = "okay";
		interrupts = <0 77 1>;
		interrupt-names = "aucpu_irq";
		reg = <0x0 0xfe09e080 0x0 0x100>;
	};

	cve {
		compatible = "amlogic, cve";
		reg = <0x0 0xFF561000 0x0 0x1000>;
		reg-names = "cve";
		interrupts = <GIC_SPI 218 IRQ_TYPE_EDGE_RISING>;
		interrupt-names = "cve";
		clocks = <&clkc CLKID_CVE>,
			<&clkc CLKID_VGE>;
		clock-names = "clk_cve", "clk_vge";
		clk-rate = <666000000>;
		power-domains = <&pwrdm PWRC_A9_CVE_ID>;
		status = "okay";
	};

	ge2d {
		compatible = "amlogic, ge2d-a9";
		status = "okay";
		interrupts = <GIC_SPI 217 IRQ_TYPE_EDGE_RISING>;
		interrupt-names = "ge2d";
		clocks = <&clkc CLKID_VAPB>,
			 <&clkc CLKID_GE2D>,
			 <&clkc CLKID_VGE>;
		clock-names = "clk_vapb_0",
			"clk_ge2d_gate",
			"cve_arb";
		reg = <0x0 0xff560000 0x0 0x100>;
		power-domains = <&pwrdm PWRC_A9_GE2D_ID>;
	};

	amlgdc {
		#address-cells=<2>;
		#size-cells=<2>;
		status = "okay";
		compatible = "amlogic, aml-gdc-v5";
		reg = <0 0xff566c00 0 0x000030c>;
		interrupts = <GIC_SPI 383 IRQ_TYPE_EDGE_RISING>;
		interrupt-names = "amlgdc";
		clocks = <&clkc CLKID_DEWARPA>, <&clkc CLKID_VGE>;
		clock-names = "clk_gate", "cve_arb";
		clk-rate = <800000000>;
		//power-domains = <&pwrdm PDID_S6_DEWARP>;
		//assigned-clocks = <&clkc CLKID_DEWARPA>;
		//assigned-clock-rates = <800000000>;
	};

	vicp {
		compatible = "amlogic, vicp-a9";
		dev_name = "vicp";
		status = "okay";
		interrupts = <GIC_SPI 263 IRQ_TYPE_EDGE_RISING>,
			<GIC_SPI 262 IRQ_TYPE_EDGE_RISING>,
			<GIC_SPI 261 IRQ_TYPE_EDGE_RISING>;
		interrupt-names = "vicp_err", "vicp_rdma", "vicp_proc";
		clocks = <&clkc CLKID_VAPB>,
			<&clkc CLKID_CVE>,
			<&clkc CLKID_CMPR>;
		clock-names = "clk_vapb_0",
			"clk_cve",
			"clk_vicp_gate";
		assigned-clocks = <&clkc CLKID_VAPB>,
			<&clkc CLKID_CVE>,
			<&clkc CLKID_CMPR>;
		assigned-clock-rates = <666666666>,
			<666666666>,
			<800000000>;
		reg = <0x0 0xff564000 0x0 0xe80>;
		power-domains = <&pwrdm PWRC_A9_VICP_ID>;
	};

	aml_bt: aml_bt {
		compatible = "amlogic, aml-bt";
		status = "disabled";
	};

	aml_wifi: aml_wifi {
		compatible = "amlogic, aml-wifi";
		status = "disabled";
		wifi_pwm_tee;
		irq_trigger_type = "IRQF_TRIGGER_LOW";
		wifi_static_buf = <0>;
		//pinctrl-0 = <&pwm_k_pins>;
		//pinctrl-names = "default";
		pwm_channel1_conf {
			pwms = <&pwm_k 0 30541 0>;
			duty-cycle = <15270>;
			times = <7>;
		};
		pwm_channel2_conf {
			pwms = <&pwm_k 1 30500 0>;
			duty-cycle = <15250>;
			times = <10>;
		};
	};

	state_led: state_led {
		compatible = "amlogic,state-led-aocpu";
		mboxes = <&mbox_fifo A9_REE2AO_LED>;
		status = "disabled";
	};

	efusecheck: efusecheck{
		maincmd = <0x8200003E>;
		checknum = <3>;
		check0 = <&check_0>;
		check1 = <&check_1>;
		check2 = <&check_2>;
		check_0:check_0{
			checkname = "dgpk1";
			subcmd = <0x1000>;
		};
		check_1:check_1{
			checkname = "dgpk2";
			subcmd = <0x1001>;
		};
		check_2:check_2{
			checkname = "aud_id";
			subcmd = <0x1002>;
		};
	};
	efuse: efuse{
		compatible = "amlogic, efuse";
		reg=<0x0 0xfe440040 0x0 0x4>;
		secureboot_mask = <0x00000c00>;
		mem_size = <0x100000>;
		read_cmd = <0x82000030>;
		write_cmd = <0x82000031>;
		get_max_cmd = <0x82000033>;
		mem_in_base_cmd = <0x82000020>;
		mem_out_base_cmd = <0x82000021>;
		efuse_pattern_size = <0x600>;
		efuse_obj_cmd_status = <0x1>;
		efuse_cali_item_read = <0x1>;
		key = <&efusekey>;
		check = <&efusecheck>;
		clock-names = "efuse_clk";
		status = "okay";
	};

	efusekey:efusekey{
		keynum = <4>;
		key0 = <&key_0>;
		key1 = <&key_1>;
		key2 = <&key_2>;
		key3 = <&key_3>;
		key_0:key_0{
			keyname = "mac";
			offset = <0>;
			size = <6>;
		};
		key_1:key_1{
			keyname = "mac_bt";
			offset = <6>;
			size = <6>;
		};
		key_2:key_2{
			keyname = "mac_wifi";
			offset = <12>;
			size = <6>;
		};
		key_3:key_3{
			keyname = "usid";
			offset = <18>;
			size = <16>;
		};
	};

	aml_mkl {
		compatible = "amlogic,aml_mkl";
		reg = <0x0 0xfe440200 0x0 0xf0>;
		kl_type = <1>;
		kl_vid_type = <0>;
		kl_offset = <0x80 0x88 0x8c 0x90>;
		status = "okay";
	};

	aml_kt {
		compatible = "amlogic,aml_kt";
		reg = <0x0 0xfe440500 0x0 0xa0>;
		kt_offset = <0x80 0x88 0x8c 0x90 0x94 0x98 0x9c>;
		kt_cap = <0x2597 0x6bf 0 64 0 32>;
		kt_reserved = <0>;
		kt_host_key_max_len = <32>;
		status = "okay";
	};

	chosen:chosen {
		bootargs = "usbcore.autosuspend=-1 dm_mod.reserved_bio_based_ios=8 swiotlb=noforce";
	};

	gpu_opp_table: gpu_opp_table {
		compatible = "operating-points-v2";
		opp-285 {
			opp-hz = /bits/ 64 <285714281>;
			opp-microvolt = <690000>;
		};
		opp-400 {
			opp-hz = /bits/ 64 <400000000>;
			opp-microvolt = <710000>;
		};
		opp-500 {
			opp-hz = /bits/ 64 <500000000>;
			opp-microvolt = <730000>;
		};
		opp-666 {
			opp-hz = /bits/ 64 <666666666>;
			opp-microvolt = <750000>;
		};
		opp-800 {
			opp-hz = /bits/ 64 <800000000>;
			opp-microvolt = <790000>;
		};
		opp-1000 {
			opp-hz = /bits/ 64 <1000000000>;
			opp-microvolt = <820000>;
		};
	};

	smmu: aml_smmu {
		compatible = "amlogic,smmu";
		status = "okay";
		#iommu-cells = <1>;
		memory-region = <&pcie_dma_ops_mm>;
	};

	codec_mm {
		compatible = "amlogic, codec, mm";
		memory-region = <&codec_mm_cma &codec_mm_reserved &secure_vdec_reserved\
			&codec_mm_reserved_ext>;
		dev_name = "codec_mm";
		status = "okay";
		/*
		 * scatter_alloc_mode: the mode of scatter memory allocation
		 * 0: default mode, alloc from system and cma
		 * 1: only alloc from system
		 */
		scatter_alloc_mode = <1>;
		/* secure memory controller para <switch  align_2n> */
		secure_ctrl_para = <1 16>;
	};

	amdolby_vision {
		compatible = "amlogic, dolby_vision_a9";
		dev_name = "aml_amdolby_vision_driver";
		status = "okay";
		tv_mode = <0>;/*1:enable ;0:disable*/
	};

	cvbsout {
		compatible = "amlogic, cvbsout-s4";
		status = "disabled";

		/* clk path */
		/* 0:vid_pll vid2_clk */
		/* 1:gp0_pll vid2_clk */
		/* 2:vid_pll vid1_clk */
		/* 3:gp0_pll vid1_clk */
		clk_path = <0>;

		/* performance: reg_address, reg_value */
		/* s4 */
		performance_pal = <0x1bf0  0x9 /* default Matrx625 CTCC value*/
			0x1b12  0x80c0
			0x1b05  0xf7
			0x1b56  0x333
			0x1c59  0xf25c
			0xffff  0x0>; /* ending flag */
		performance = <0x1bf0  0x9 /* ccitt033 SVA value */
			0x1b12  0x8040
			0x1b05  0xfd
			0x1b56  0x333
			0x1c59  0xf654
			0xffff  0x0>; /* ending flag */
		performance_ntsc = <0x1bf0  0x9
			0x1b12  0x8020
			0x1b03  0x0
			0x1b04  0x0
			0x1b05  0x0
			0x1b06  0x0
			0x1b56  0x333
			0x1c59  0xf850
			0xffff  0x0>; /* ending flag */
	};

	ionvideo {
		compatible = "amlogic, ionvideo";
		dev_name = "ionvideo";
		status = "disabled";
	};

	video_queue {
		compatible = "amlogic, video_queue";
		dev_name = "videoqueue";
		status = "okay";
	};

	amlvideo2_0: amlvideo2_0 {
		compatible = "amlogic, amlvideo2";
		dev_name = "amlvideo2";
		vpu_dma_mask = <1>;  /* 0: <= 4G, 1: > 4G*/
		status = "okay";
		amlvideo2_id = <0>;
		cma_mode = <1>;
	};

	amlvideo2_1: amlvideo2_1 {
		compatible = "amlogic, amlvideo2";
		dev_name = "amlvideo2";
		vpu_dma_mask = <1>;  /* 0: <= 4G, 1: > 4G*/
		status = "okay";
		amlvideo2_id = <1>;
		cma_mode = <1>;
		support_4k = <1>;
	};

	amvdec_csi: amvdec_csi {
		compatible = "amlogic, amvdec_csi-s6";
		status = "okay";
		csi_id = <0>;
		squlech_mode = <0>;
		deskew_mode = <0>;
		reg = <0x0 0xfe014000 0x0 0x00000100>,
			<0x0 0xfe016000 0x0 0x00000100>,
			<0x0 0xfe018000 0x0 0x00000100>;
		reg-names = "csi_phy", "csi_host", "csi_adapt";

		//clocks = <&clkc CLKID_CSI2_ADAPT>,
		//	   <&clkc CLKID_CSI_PHY>;
		clock-names = "cts_csi_adapt_clk_composite",
			"cts_csi_phy_clk_composite";

		// depends on power domain.
		//power-domains = <&pwrdm PDID_S6_ADAPT>;

		// 88 for csi2_adap_int
		interrupts = <GIC_SPI 88 IRQ_TYPE_EDGE_RISING>;
		interrupt-names = "csi_phy";
	};

	ppmgr {
		compatible = "amlogic, ppmgr";
		memory-region = <&ppmgr_reserved>;
		dev_name = "ppmgr";
		status = "disabled";
	};

	provisionkey {
		compatible = "amlogic, provisionkey";
		status = "disabled";
		key-permit-default = "write";
		//new key not need add dts if started with KEY_PROVISION_
		KEY_PROVISION_XXX { };
		//test_my_added_keyname { };
	};//End provisionkey

	unifykey{
		compatible = "amlogic,unifykey";
		status = "okay";
		unifykey-num = <19>;
		unifykey-index-0 = <&keysn_0>;
		unifykey-index-1 = <&keysn_1>;
		unifykey-index-2 = <&keysn_2>;
		unifykey-index-3 = <&keysn_3>;
		unifykey-index-4 = <&keysn_4>;
		unifykey-index-5 = <&keysn_5>;
		unifykey-index-6 = <&keysn_6>;
		unifykey-index-7 = <&keysn_7>;
		unifykey-index-8 = <&keysn_8>;
		unifykey-index-9 = <&keysn_9>;
		unifykey-index-10= <&keysn_10>;
		unifykey-index-11= <&keysn_11>;
		unifykey-index-12= <&keysn_12>;
		unifykey-index-13= <&keysn_13>;
		unifykey-index-14= <&keysn_14>;
		unifykey-index-15= <&keysn_15>;
		unifykey-index-16= <&keysn_16>;
		unifykey-index-17= <&keysn_17>;
		unifykey-index-18= <&keysn_18>;

		keysn_0: key_0{
			key-name = "usid";
			key-device = "normal";
			key-permit = "read","write","del";
		};
		keysn_1:key_1{
			key-name = "mac";
			key-device = "normal";
			key-permit = "read","write","del";
		};
		keysn_2:key_2{
			key-name = "hdcp";
			key-device = "secure";
			key-type = "sha1";
			key-permit = "read","write","del";
		};
		keysn_3:key_3{
			key-name = "secure_boot_set";
			key-device = "efuse";
			key-permit = "write";
		};
		keysn_4:key_4{
			key-name = "mac_bt";
			key-device = "normal";
			key-permit = "read","write","del";
			key-type  = "mac";
		};
		keysn_5:key_5{
			key-name = "mac_wifi";
			key-device = "normal";
			key-permit = "read","write","del";
			key-type = "mac";
		};
		keysn_6:key_6{
			key-name = "hdcp2_tx";
			key-device = "normal";
			key-permit = "read","write","del";
		};
		keysn_7:key_7{
			key-name = "hdcp2_rx";
			key-device = "normal";
			key-permit = "read","write","del";
		};
		keysn_8:key_8{
			key-name = "widevinekeybox";
			key-device = "secure";
			key-permit = "read","write","del";
		};
		keysn_9:key_9{
			key-name = "deviceid";
			key-device = "normal";
			key-permit = "read","write","del";
		};
		keysn_10:key_10{
			key-name = "hdcp22_fw_private";
			key-device = "secure";
			key-permit = "read","write","del";
		};
		keysn_11:key_11{
			key-name = "PlayReadykeybox25";
			key-device = "secure";
			key-permit = "read","write","del";
		};
		keysn_12:key_12{
			key-name = "prpubkeybox";//PlayReady
			key-device = "secure";
			key-permit = "read","write","del";
		};
		keysn_13:key_13{
			key-name = "prprivkeybox";//PlayReady
			key-device = "secure";
			key-permit = "read","write","del";
		};
		keysn_14:key_14{
			key-name = "attestationkeybox";//attestation key
			key-device = "secure";
			key-permit = "read","write","del";
		};
		keysn_15:key_15{
			key-name = "region_code";
			key-device = "normal";
			key-permit = "read","write","del";
		};
		keysn_16:key_16{
			key-name = "netflix_mgkid";
			key-device = "secure";
			key-permit = "read","write","del";
		};
		keysn_17:key_17{
			key-name = "attestationdevidbox";//attest dev id box
			key-device = "secure";
			key-permit = "read","write","del";
		};
		keysn_18:key_18{
			key-name = "oemkey";
			key-device = "normal";
			key-permit = "read","write","del";
		};
	};//End unifykey

	picdec {
		compatible = "amlogic, picdec";
		status = "disabled";
	};
};

&aobus_pinctrl {
	func-pwm-a {
		pwm_a_pins1: group-pwm-a-pins1 {
			pinmux = <AML_PINMUX(AMLOGIC_GPIO_D, 10, 3)>;
		};

		pwm_a_pins2: group-pwm-a-pins2 {
			pinmux = <AML_PINMUX(AMLOGIC_GPIO_AO, 0, 1)>;
		};

		pwm_a_pins3: group-pwm-a-pins3 {
			pinmux = <AML_PINMUX(AMLOGIC_GPIO_AO, 11, 2)>;
		};

		pwm_a_hiz_pins: group-pwm-a-hiz-pins {
			pinmux = <AML_PINMUX(AMLOGIC_GPIO_D, 10, 1)>;
		};
	};

	func-pwm-b {
		pwm_b_pins1: group-pwm-b-pins {
			pinmux = <AML_PINMUX(AMLOGIC_GPIO_AO, 1, 1)>;
		};
	};

	func-pwm-c {
		pwm_c_pins1: group-pwm-c-pins {
			pinmux = <AML_PINMUX(AMLOGIC_GPIO_AO, 2, 1)>;
		};

		pwm_c_hiz_pins: group-pwm-c-hiz-pins {
			pinmux = <AML_PINMUX(AMLOGIC_GPIO_D, 10, 4)>;
		};
	};

	func-pwm-d {
		pwm_d_pins1: group-pwm-d-pins {
			pinmux = <AML_PINMUX(AMLOGIC_GPIO_AO, 3, 1)>;
		};
	};

	func-pwm-e {
		pwm_e_pins1: group-pwm-e-pins {
			pinmux = <AML_PINMUX(AMLOGIC_GPIO_AO, 4, 1)>;
		};
	};

	func-pwm-f {
		pwm_f_pins1: group-pwm-f-pins {
			pinmux = <AML_PINMUX(AMLOGIC_GPIO_AO, 5, 1)>;
		};
	};

	func-pwm-g {
		pwm_g_pins1: group-pwm-g-pins1 {
			pinmux = <AML_PINMUX(AMLOGIC_GPIO_D, 11, 3)>;
		};

		pwm_g_pins2: group-pwm-g-pins2 {
			pinmux = <AML_PINMUX(AMLOGIC_GPIO_AO, 6, 4)>;
		};

		pwm_g_hiz_pins: group-pwm-g-hiz-pins {
			pinmux = <AML_PINMUX(AMLOGIC_GPIO_D, 11, 4)>;
		};
	};

	func-i2c0 {
		i2c0_pins1: group-i2c0-pins1 {
			pinmux = <AML_PINMUX(AMLOGIC_GPIO_D, 2, 1)>,
				 <AML_PINMUX(AMLOGIC_GPIO_D, 3, 1)>;
			bias-disable;
		};

		i2c0_pins2: group-i2c0-pins2 {
			pinmux = <AML_PINMUX(AMLOGIC_GPIO_C, 4, 4)>,
				 <AML_PINMUX(AMLOGIC_GPIO_C, 5, 4)>;
			bias-disable;
		};

		i2c0_pins3: group-i2c0-pins3 {
			pinmux = <AML_PINMUX(AMLOGIC_GPIO_D, 6, 1)>,
				 <AML_PINMUX(AMLOGIC_GPIO_D, 7, 1)>;
			bias-disable;
		};

		i2c0_pins4: group-i2c0-pins4 {
			pinmux = <AML_PINMUX(AMLOGIC_GPIO_AO, 0, 2)>,
				 <AML_PINMUX(AMLOGIC_GPIO_AO, 1, 2)>;
			bias-disable;
		};
	};

	func-i2c1 {
		i2c1_pins1: group-i2c1-pins1 {
			pinmux = <AML_PINMUX(AMLOGIC_GPIO_AO, 4, 2)>,
				 <AML_PINMUX(AMLOGIC_GPIO_AO, 5, 2)>;
			bias-disable;
		};

		i2c1_pins2: group-i2c1-pins2 {
			pinmux = <AML_PINMUX(AMLOGIC_GPIO_C, 2, 4)>,
				 <AML_PINMUX(AMLOGIC_GPIO_C, 3, 4)>;
			bias-disable;
		};
	};

	func-i2c2 {
		i2c2_pins1: group-i2c2-pins1 {
			pinmux = <AML_PINMUX(AMLOGIC_GPIO_D, 13, 1)>,
				 <AML_PINMUX(AMLOGIC_GPIO_D, 14, 1)>;
			bias-disable;
		};

		i2c2_pins2: group-i2c2-pins2 {
			pinmux = <AML_PINMUX(AMLOGIC_GPIO_C, 0, 4)>,
				 <AML_PINMUX(AMLOGIC_GPIO_C, 1, 4)>;
			bias-disable;
		};

		i2c2_pins3: group-i2c2-pins3 {
			pinmux = <AML_PINMUX(AMLOGIC_GPIO_AO, 6, 2)>,
				 <AML_PINMUX(AMLOGIC_GPIO_AO, 7, 2)>;
			bias-disable;
		};
	};

	func-i2c3 {
		i2c3_pins1: group-i2c3-pins1 {
			pinmux = <AML_PINMUX(AMLOGIC_GPIO_D, 15, 1)>,
				 <AML_PINMUX(AMLOGIC_GPIO_D, 16, 1)>;
			bias-disable;
		};

		i2c3_pins2: group-i2c3-pins2 {
			pinmux = <AML_PINMUX(AMLOGIC_GPIO_AO, 11, 1)>,
				 <AML_PINMUX(AMLOGIC_GPIO_AO, 12, 1)>;
			bias-disable;
		};

		i2c3_pins3: group-i2c3-pins3 {
			pinmux = <AML_PINMUX(AMLOGIC_GPIO_AO, 8, 2)>,
				 <AML_PINMUX(AMLOGIC_GPIO_AO, 9, 2)>;
			bias-disable;
		};
	};

	func-i3c0 {
		i3c0_ao_pins1: group-i3c0-ao-pins1 {
			pinmux = <AML_PINMUX(AMLOGIC_GPIO_D, 2, 3)>,
				 <AML_PINMUX(AMLOGIC_GPIO_D, 3, 3)>;
			bias-disable;
		};

		i3c0_ao_pins2: group-i3c0-ao-pins2 {
			pinmux = <AML_PINMUX(AMLOGIC_GPIO_C, 0, 7)>,
				 <AML_PINMUX(AMLOGIC_GPIO_C, 1, 7)>;
			bias-disable;
		};
	};

	func-ir-in {
		remote_pins: group-remote-pins {
			pinmux = <AML_PINMUX(AMLOGIC_GPIO_D, 5, 1)>;
			bias-disable;
		};

		remote_pins_1: group-remote-pins-1 {
			pinmux = <AML_PINMUX(AMLOGIC_GPIO_D, 9, 3)>;
			bias-disable;
		};
	};

	func-gpio-periphs {
		sd_to_ao_uart_clr_pins: group-sd2aoaurt-clr-pin {
			pinmux = <AML_PINMUX(AMLOGIC_GPIO_D, 0, 0)>,
				 <AML_PINMUX(AMLOGIC_GPIO_D, 1, 0)>;
			drive-strength = <3>;
			bias-pull-up;
		};

		sd_clr_all_pins: group-sd-clr-pins1 {
			pinmux = <AML_PINMUX(AMLOGIC_GPIO_C, 0, 0)>,
				 <AML_PINMUX(AMLOGIC_GPIO_C, 1, 0)>,
				 <AML_PINMUX(AMLOGIC_GPIO_C, 2, 0)>,
				 <AML_PINMUX(AMLOGIC_GPIO_C, 3, 0)>,
				 <AML_PINMUX(AMLOGIC_GPIO_C, 5, 0)>;
			output-high;
		};

		/* Attention use together with sd_clr_all_pins because of not mux */
		sd_clr_all_pins2: group-sd-clr-pins2 {
			pinmux = <AML_PINMUX(AMLOGIC_GPIO_C, 4, 0)>;
			output-low;
		};

		sd_clr_noall_pins: group-sd-clr-no-pins {
			pinmux = <AML_PINMUX(AMLOGIC_GPIO_C, 0, 0)>,
				 <AML_PINMUX(AMLOGIC_GPIO_C, 1, 0)>,
				 <AML_PINMUX(AMLOGIC_GPIO_C, 4, 0)>,
				 <AML_PINMUX(AMLOGIC_GPIO_C, 5, 0)>;
			output-high;
		};
	};
};

&periphs_pinctrl {
	func-gpio-periphs {
		bl_pwm_off_pins: group-bl-pwm-off-pin {
			pinmux = <AML_PINMUX(AMLOGIC_GPIO_F, 4, 0)>;
			drive-strength = <3>;
			bias-pull-up;
		};
	};

	func-pwm-h {
		pwm_h_pins1: group-pwm-h-pins {
			pinmux = <AML_PINMUX(AMLOGIC_GPIO_X, 17, 1)>;
		};
	};

	func-pwm-i {
		pwm_i_pins1: group-pwm-i-pins {
			pinmux = <AML_PINMUX(AMLOGIC_GPIO_Y, 1, 1)>;
		};
	};

	func-pwm-j {
		pwm_j_pins1: group-pwm-j-pins1 {
			pinmux = <AML_PINMUX(AMLOGIC_GPIO_Y, 5, 1)>;
		};

		pwm_j_pins2: group-pwm-j-pins2 {
			pinmux = <AML_PINMUX(AMLOGIC_GPIO_M, 4, 5)>;
		};
	};

	func-pwm-k {
		pwm_k_pins1: group-pwm-k-pins1 {
			pinmux = <AML_PINMUX(AMLOGIC_GPIO_X, 15, 1)>;
		};

		pwm_k_pins2: group-pwm-k-pins2 {
			pinmux = <AML_PINMUX(AMLOGIC_GPIO_Y, 2, 1)>;
		};
	};

	func-pwm-l {
		pwm_l_pins1: group-pwm-l-pins {
			pinmux = <AML_PINMUX(AMLOGIC_GPIO_Y, 3, 1)>;
		};
	};

	func-pwm-m {
		pwm_m_pins1: group-pwm-m-pins1 {
			pinmux = <AML_PINMUX(AMLOGIC_GPIO_H, 4, 3)>;
		};

		pwm_m_pins2: group-pwm-m-pins2 {
			pinmux = <AML_PINMUX(AMLOGIC_GPIO_Y, 4, 1)>;
		};
	};

	func-pwm-n {
		pwm_n_pins1: group-pwm-n-pins1 {
			pinmux = <AML_PINMUX(AMLOGIC_GPIO_Y, 0, 1)>;
		};
	};

	func-i2c3 {
		i2c3_pins4: group-i2c3-pins4 {
			pinmux = <AML_PINMUX(AMLOGIC_GPIO_A, 14, 3)>,
				 <AML_PINMUX(AMLOGIC_GPIO_A, 15, 3)>;
			bias-disable;
		};

		i2c3_pins4_sleep:group-i2c3-pins4-sleep {
			pinmux = <AML_PINMUX(AMLOGIC_GPIO_A, 14, 0)>,
				 <AML_PINMUX(AMLOGIC_GPIO_A, 15, 0)>;
			input-enable;
		};
	};

	func-i2c4 {
		i2c4_pins1: group-i2c4-pins1 {
			pinmux = <AML_PINMUX(AMLOGIC_GPIO_A, 5, 3)>,
				 <AML_PINMUX(AMLOGIC_GPIO_A, 6, 3)>;
			bias-disable;
		};

		i2c4_pins2: group-i2c4-pins2 {
			pinmux = <AML_PINMUX(AMLOGIC_GPIO_M, 2, 1)>,
				 <AML_PINMUX(AMLOGIC_GPIO_M, 2, 1)>;
			bias-disable;
		};

		i2c4_pins3: group-i2c4-pins3 {
			pinmux = <AML_PINMUX(AMLOGIC_GPIO_Y, 5, 2)>,
				 <AML_PINMUX(AMLOGIC_GPIO_Y, 6, 2)>;
			bias-disable;
		};

		i2c4_pins3_sleep:group-i2c4-pins3-sleep {
			pinmux = <AML_PINMUX(AMLOGIC_GPIO_Y, 5, 0)>,
				 <AML_PINMUX(AMLOGIC_GPIO_Y, 6, 0)>;
			input-enable;
		};

		i2c4_pins4: group-i2c4-pins4 {
			pinmux = <AML_PINMUX(AMLOGIC_GPIO_Z, 0, 6)>,
				 <AML_PINMUX(AMLOGIC_GPIO_Z, 1, 6)>;
			bias-disable;
		};
	};

	func-i2c5 {
		i2c5_pins1: group-i2c5-pins1 {
			pinmux = <AML_PINMUX(AMLOGIC_GPIO_Z, 2, 6)>,
				 <AML_PINMUX(AMLOGIC_GPIO_Z, 3, 6)>;
			bias-disable;
		};

		i2c5_pins2: group-i2c5-pins2 {
			pinmux = <AML_PINMUX(AMLOGIC_GPIO_H, 4, 2)>,
				 <AML_PINMUX(AMLOGIC_GPIO_H, 5, 2)>;
			bias-disable;
		};

		i2c5_pins3: group-i2c5-pins3 {
			pinmux = <AML_PINMUX(AMLOGIC_GPIO_CC, 0, 1)>,
				 <AML_PINMUX(AMLOGIC_GPIO_CC, 1, 1)>;
			bias-disable;
		};

		i2c5_pins4: group-i2c5-pins4 {
			pinmux = <AML_PINMUX(AMLOGIC_GPIO_M, 4, 1)>,
				 <AML_PINMUX(AMLOGIC_GPIO_M, 5, 1)>;
			bias-disable;
		};
	};

	func-i2c6 {
		i2c6_pins1: group-i2c6-pins1 {
			pinmux = <AML_PINMUX(AMLOGIC_GPIO_A, 3, 3)>,
				 <AML_PINMUX(AMLOGIC_GPIO_A, 4, 3)>;
			bias-disable;
		};

		i2c6_pins2: group-i2c6-pins2 {
			pinmux = <AML_PINMUX(AMLOGIC_GPIO_M, 0, 1)>,
				 <AML_PINMUX(AMLOGIC_GPIO_M, 1, 1)>;
			bias-disable;
		};

		i2c6_pins3: group-i2c6-pins3 {
			pinmux = <AML_PINMUX(AMLOGIC_GPIO_Z, 4, 6)>,
				 <AML_PINMUX(AMLOGIC_GPIO_Z, 5, 6)>;
			bias-disable;
		};
	};

	func-i2c7 {
		i2c7_pins1: group-i2c7-pins1 {
			pinmux = <AML_PINMUX(AMLOGIC_GPIO_X, 2, 4)>,
				 <AML_PINMUX(AMLOGIC_GPIO_X, 3, 4)>;
			bias-disable;
		};

		i2c7_pins2: group-i2c7-pins2 {
			pinmux = <AML_PINMUX(AMLOGIC_GPIO_M, 6, 1)>,
				 <AML_PINMUX(AMLOGIC_GPIO_M, 7, 1)>;
			bias-disable;
		};

		i2c7_pins3: group-i2c7-pins3 {
			pinmux = <AML_PINMUX(AMLOGIC_GPIO_Z, 6, 6)>,
				 <AML_PINMUX(AMLOGIC_GPIO_Z, 7, 6)>;
			bias-disable;
		};
	};

	func-i2c8 {
		i2c8_pins1: group-i2c8-pins1 {
			pinmux = <AML_PINMUX(AMLOGIC_GPIO_X, 0, 4)>,
				 <AML_PINMUX(AMLOGIC_GPIO_X, 1, 4)>;
			bias-disable;
		};

		i2c8_pins2: group-i2c8-pins2 {
			pinmux = <AML_PINMUX(AMLOGIC_GPIO_A, 12, 3)>,
				 <AML_PINMUX(AMLOGIC_GPIO_A, 13, 3)>;
			bias-disable;
		};

		i2c8_pins3: group-i2c8-pins3 {
			pinmux = <AML_PINMUX(AMLOGIC_GPIO_Y, 8, 3)>,
				 <AML_PINMUX(AMLOGIC_GPIO_Y, 9, 3)>;
			bias-disable;
		};
	};

	func-i3c0 {
		i3c0_pins1: group-i3c0-pins1 {
			pinmux = <AML_PINMUX(AMLOGIC_GPIO_A, 18, 4)>,
				 <AML_PINMUX(AMLOGIC_GPIO_A, 19, 4)>;
			bias-disable;
		};
	};

	func-i3c1 {
		i3c1_pins1: group-i3c1-pins1 {
			pinmux = <AML_PINMUX(AMLOGIC_GPIO_X, 1, 7)>,
				 <AML_PINMUX(AMLOGIC_GPIO_X, 2, 7)>;
			bias-disable;
		};

		i3c1_pins2: group-i3c1-pins2 {
			pinmux = <AML_PINMUX(AMLOGIC_GPIO_A, 14, 5)>,
				 <AML_PINMUX(AMLOGIC_GPIO_A, 15, 5)>;
			bias-disable;
		};

		i3c1_pins3: group-i3c1-pins3 {
			pinmux = <AML_PINMUX(AMLOGIC_GPIO_X, 0, 7)>,
				 <AML_PINMUX(AMLOGIC_GPIO_X, 1, 7)>,
				 <AML_PINMUX(AMLOGIC_GPIO_X, 2, 7)>,
				 <AML_PINMUX(AMLOGIC_GPIO_X, 3, 7)>,
				 <AML_PINMUX(AMLOGIC_GPIO_X, 4, 7)>;
			bias-disable;
		};

		i3c1_pins4: group-i3c1-pins4 {
			pinmux = <AML_PINMUX(AMLOGIC_GPIO_A, 13, 5)>,
				 <AML_PINMUX(AMLOGIC_GPIO_A, 14, 5)>,
				 <AML_PINMUX(AMLOGIC_GPIO_A, 15, 5)>,
				 <AML_PINMUX(AMLOGIC_GPIO_A, 16, 5)>,
				 <AML_PINMUX(AMLOGIC_GPIO_A, 17, 5)>;
			bias-disable;
		};
	};

	func-uart-a {
		a_uart_pins: group-uart-a-pins {
			pinmux = <AML_PINMUX(AMLOGIC_GPIO_X, 11, 1)>,
				 <AML_PINMUX(AMLOGIC_GPIO_X, 12, 1)>,
				 <AML_PINMUX(AMLOGIC_GPIO_X, 13, 1)>,
				 <AML_PINMUX(AMLOGIC_GPIO_X, 14, 1)>;
			drive-strength = <3>;
			bias-pull-up;
		};
	};

	func-uart-c {
		c_uart_pins: group-uart-c-pins {
			pinmux = <AML_PINMUX(AMLOGIC_GPIO_H, 0, 2)>,
				 <AML_PINMUX(AMLOGIC_GPIO_H, 1, 2)>;
			drive-strength = <3>;
			bias-pull-up;
		};
	};

	func-uart-d {
		d_uart_pins1: group-uart-d-pins1 {
			pinmux = <AML_PINMUX(AMLOGIC_GPIO_Z, 0, 7)>,
				 <AML_PINMUX(AMLOGIC_GPIO_Z, 1, 7)>,
				 <AML_PINMUX(AMLOGIC_GPIO_Z, 2, 7)>,
				 <AML_PINMUX(AMLOGIC_GPIO_Z, 3, 7)>;
			drive-strength = <3>;
			bias-pull-up;
		};

		d_uart_pins2: group-uart-d-pins2 {
			pinmux = <AML_PINMUX(AMLOGIC_GPIO_M, 0, 2)>,
				 <AML_PINMUX(AMLOGIC_GPIO_M, 1, 2)>,
				 <AML_PINMUX(AMLOGIC_GPIO_M, 2, 2)>,
				 <AML_PINMUX(AMLOGIC_GPIO_M, 3, 2)>;
			drive-strength = <3>;
			bias-pull-up;
		};
	};

	func-uart-e {
		e_uart_pins: group-uart-e-pins {
			pinmux = <AML_PINMUX(AMLOGIC_GPIO_Z, 6, 7)>,
				 <AML_PINMUX(AMLOGIC_GPIO_Z, 7, 7)>,
				 <AML_PINMUX(AMLOGIC_GPIO_Z, 8, 7)>,
				 <AML_PINMUX(AMLOGIC_GPIO_Z, 9, 7)>;
			drive-strength = <3>;
			bias-pull-up;
		};
	};

	func-uart-f {
		f_uart_pins: group-uart-f-pins {
			pinmux = <AML_PINMUX(AMLOGIC_GPIO_M, 4, 2)>,
				 <AML_PINMUX(AMLOGIC_GPIO_M, 5, 2)>,
				 <AML_PINMUX(AMLOGIC_GPIO_M, 6, 2)>,
				 <AML_PINMUX(AMLOGIC_GPIO_M, 7, 2)>;
			drive-strength = <3>;
			bias-pull-up;
		};
	};

	func-emmc {
		emmc_pins: group-emmc-pins {
			pinmux = <AML_PINMUX(AMLOGIC_GPIO_B, 0, 1)>,
				 <AML_PINMUX(AMLOGIC_GPIO_B, 1, 1)>,
				 <AML_PINMUX(AMLOGIC_GPIO_B, 2, 1)>,
				 <AML_PINMUX(AMLOGIC_GPIO_B, 3, 1)>,
				 <AML_PINMUX(AMLOGIC_GPIO_B, 4, 1)>,
				 <AML_PINMUX(AMLOGIC_GPIO_B, 5, 1)>,
				 <AML_PINMUX(AMLOGIC_GPIO_B, 6, 1)>,
				 <AML_PINMUX(AMLOGIC_GPIO_B, 7, 1)>,
				 <AML_PINMUX(AMLOGIC_GPIO_B, 8, 1)>, /* emmc_clk */
				 <AML_PINMUX(AMLOGIC_GPIO_B, 10, 1)>;
			bias-pull-up;
			drive-strength-microamp = <3000>;
		};

		emmc_ds_pins: group-emmc-ds-pins {
			pinmux = <AML_PINMUX(AMLOGIC_GPIO_B, 11, 1)>;
			bias-pull-down;
			drive-strength-microamp = <3000>;
		};

		emmc_clk_gate_pins: group-emmc-clk-gate-pins {
			pinmux = <AML_PINMUX(AMLOGIC_GPIO_B, 8, 0)>;
			bias-pull-down;
			drive-strength-microamp = <3000>;
		};
	};

	func-nand {
		all_nand_pins: group-nand-pins {
			pinmux = <AML_PINMUX(AMLOGIC_GPIO_B, 0, 1)>,
				 <AML_PINMUX(AMLOGIC_GPIO_B, 1, 1)>,
				 <AML_PINMUX(AMLOGIC_GPIO_B, 2, 1)>,
				 <AML_PINMUX(AMLOGIC_GPIO_B, 3, 1)>,
				 <AML_PINMUX(AMLOGIC_GPIO_B, 4, 1)>,
				 <AML_PINMUX(AMLOGIC_GPIO_B, 5, 1)>,
				 <AML_PINMUX(AMLOGIC_GPIO_B, 6, 1)>,
				 <AML_PINMUX(AMLOGIC_GPIO_B, 7, 1)>, /* mux emmc-data[0:7] */
				 <AML_PINMUX(AMLOGIC_GPIO_B, 8, 2)>,
				 <AML_PINMUX(AMLOGIC_GPIO_B, 9, 2)>,
				 <AML_PINMUX(AMLOGIC_GPIO_B, 10, 2)>,
				 <AML_PINMUX(AMLOGIC_GPIO_B, 11, 2)>,
				 <AML_PINMUX(AMLOGIC_GPIO_B, 12, 2)>;
			input-enable;
		};

		nand_cs_pins: group-nand-cs-pins {
			pinmux = <AML_PINMUX(AMLOGIC_GPIO_B, 12, 2)>; /* ce0 */
		};
	};

	func-sdio {
		sd_iso7816_pins: group-sd-iso7816-pins {
			pinmux = <AML_PINMUX(AMLOGIC_GPIO_Z, 0, 2)>,
				 <AML_PINMUX(AMLOGIC_GPIO_Z, 1, 2)>;
			input-enable;
			bias-pull-down;
		};

		sdio_pins: group-sdio-pins {
			pinmux = <AML_PINMUX(AMLOGIC_GPIO_X, 0, 1)>,
				 <AML_PINMUX(AMLOGIC_GPIO_X, 1, 1)>,
				 <AML_PINMUX(AMLOGIC_GPIO_X, 2, 1)>,
				 <AML_PINMUX(AMLOGIC_GPIO_X, 3, 1)>,
				 <AML_PINMUX(AMLOGIC_GPIO_X, 4, 1)>,
				 <AML_PINMUX(AMLOGIC_GPIO_X, 5, 1)>;
			bias-pull-up;
			drive-strength-microamp = <3000>;
		};

		sdio_clk_gate_pins: group-sdio-clk-gate-pins {
			pinmux = <AML_PINMUX(AMLOGIC_GPIO_X, 4, 0)>;
			bias-pull-down;
			drive-strength-microamp = <3000>;
		};
	};

	func-hdmi {
		hdmitx_hpd: group-hdmitx-hpd-pins {
			pinmux = <AML_PINMUX(AMLOGIC_GPIO_H, 6, 1)>;
			bias-disable;
		};

		hdmitx_hpd_gpio: group-hdmitx-hpd-gpio-pins {
			pinmux = <AML_PINMUX(AMLOGIC_GPIO_H, 1, 0)>; /* ??? GPIO_H_6 */
			bias-disable;
		};

		hdmitx_ddc: group-hdmitx-ddc-pins {
			pinmux = <AML_PINMUX(AMLOGIC_GPIO_H, 4, 1)>,
				 <AML_PINMUX(AMLOGIC_GPIO_H, 5, 1)>;
			bias-disable;
			drive-strength = <3>;
		};

		hdmirx_a_mux: group-hdmirx-a-mux-pins {
			pinmux = <AML_PINMUX(AMLOGIC_GPIO_H, 0, 1)>,
				 <AML_PINMUX(AMLOGIC_GPIO_H, 1, 1)>,
				 <AML_PINMUX(AMLOGIC_GPIO_H, 2, 1)>,
				 <AML_PINMUX(AMLOGIC_GPIO_H, 3, 1)>;
		};
	};

	func-lcd {
		lcd_vbyone_a_pins: group-lcd-vbyone-a-pins {
			pinmux = <AML_PINMUX(AMLOGIC_GPIO_Y, 7, 1)>,
				 <AML_PINMUX(AMLOGIC_GPIO_Y, 9, 1)>;
		};

		lcd_vbyone_a_off_pins: group-lcd-vbyone-a-off-pins {
			pinmux = <AML_PINMUX(AMLOGIC_GPIO_Y, 7, 0)>,
				 <AML_PINMUX(AMLOGIC_GPIO_Y, 9, 0)>;
			input-enable;
		};
	};

	func-edp {
		edptx_0_hpd_pins: group-edptx-0-hpd-pins {
			pinmux = <AML_PINMUX(AMLOGIC_GPIO_Y, 9, 2)>;
		};

		edptx_0_hpd_off_pins: group-edptx-0-hpd-off-pins {
			pinmux = <AML_PINMUX(AMLOGIC_GPIO_Y, 9, 0)>;
			input-enable;
		};
	};

	func-backlight {
		bl0_pwm_off_pins: group-bl0-pwm-off-pins {
			pinmux = <AML_PINMUX(AMLOGIC_GPIO_Y, 1, 0)>;
			output-low;
		};

		bl1_pwm_off_pins: group-bl1-pwm-off-pins {
			pinmux = <AML_PINMUX(AMLOGIC_GPIO_Y, 5, 0)>;
			output-low;
		};
	};

	func-dtv {
		dtvdemod_if_agc_pins: group-dtvdemod-if-agc-pins {
			pinmux = <AML_PINMUX(AMLOGIC_GPIO_Y, 9, 2)>; /* ??dtv_a_if_agc_z10 */
		};

		dtvdemod_if_agc2_pins: group-dtvdemod-if-agc2-pins {
			pinmux = <AML_PINMUX(AMLOGIC_GPIO_Y, 9, 2)>; /* ?? dtv_b_if_agc */
		};

		dtvdemod_rf_agc_pins: group-dtvdemod-rf-agc-pins {
			pinmux = <AML_PINMUX(AMLOGIC_GPIO_Y, 9, 2)>; /* ?? dtv_a_rf_agc */
		};
	};

	func-dis {
		diseqc_out: group-diseqc-out-pins {
			pinmux = <AML_PINMUX(AMLOGIC_GPIO_Y, 9, 2)>; /* ??diseqc_out */
			bias-pull-down;
		};

		diseqc_in: group-diseqc-in-pins {
			pinmux = <AML_PINMUX(AMLOGIC_GPIO_Y, 9, 2)>; /* ??diseqc_in */
			bias-pull-down;
		};
	};

	func-spisg-c {
		spisg_c_pins_a: group-spisg-c-pins1 {
			pinmux = <AML_PINMUX(AMLOGIC_GPIO_A, 8, 3)>,
				 <AML_PINMUX(AMLOGIC_GPIO_A, 9, 3)>,
				 <AML_PINMUX(AMLOGIC_GPIO_A, 10, 3)>,
				 <AML_PINMUX(AMLOGIC_GPIO_A, 11, 3)>;
			drive-strength-microamp = <3000>;
		};

		spisg_c_pins_m: group-spisg-c-pins2 {
			pinmux = <AML_PINMUX(AMLOGIC_GPIO_M, 0, 5)>,
				 <AML_PINMUX(AMLOGIC_GPIO_M, 1, 5)>,
				 <AML_PINMUX(AMLOGIC_GPIO_M, 2, 5)>,
				 <AML_PINMUX(AMLOGIC_GPIO_M, 3, 5)>;
			drive-strength-microamp = <3000>;
		};
	};

	func-spisg-e {
		spisg_e_pins_z: group-spisg-e-pins {
			pinmux = <AML_PINMUX(AMLOGIC_GPIO_Z, 0, 4)>,
				 <AML_PINMUX(AMLOGIC_GPIO_Z, 1, 4)>,
				 <AML_PINMUX(AMLOGIC_GPIO_Z, 2, 4)>,
				 <AML_PINMUX(AMLOGIC_GPIO_Z, 3, 4)>;
			drive-strength-microamp = <3000>;
		};
	};

	func-spisg-f {
		spisg_f_pins_z: group-spisg-f-pins {
			pinmux = <AML_PINMUX(AMLOGIC_GPIO_Z, 4, 4)>,
				 <AML_PINMUX(AMLOGIC_GPIO_Z, 5, 4)>,
				 <AML_PINMUX(AMLOGIC_GPIO_Z, 6, 4)>,
				 <AML_PINMUX(AMLOGIC_GPIO_Z, 7, 4)>;
			drive-strength-microamp = <3000>;
		};
	};

	func-spisg-b {
		spisg_b_pins_z: group-spisg-b-pins {
			pinmux = <AML_PINMUX(AMLOGIC_GPIO_Z, 8, 4)>,
				 <AML_PINMUX(AMLOGIC_GPIO_Z, 9, 4)>,
				 <AML_PINMUX(AMLOGIC_GPIO_Z, 10, 4)>,
				 <AML_PINMUX(AMLOGIC_GPIO_Z, 11, 4)>,
				 <AML_PINMUX(AMLOGIC_GPIO_Z, 12, 4)>,
				 <AML_PINMUX(AMLOGIC_GPIO_Z, 13, 4)>;
			drive-strength-microamp = <3000>;
		};
	};

	/* ??? spif_hold spif_mo spif_mi spif_clk spif_wp spif_cs */
	func-spifc {
		spifc_pins: group-spifc-pins {
			pinmux = <AML_PINMUX(AMLOGIC_GPIO_Z, 8, 4)>;
			drive-strength-microamp = <3000>;
		};
	};

	func-irblaster {
		/* ??? ir_remote_out_f */
		irblaster_pin_f: group-irblaster-f-pins {
			pinmux = <AML_PINMUX(AMLOGIC_GPIO_Z, 8, 4)>;
			drive-strength-microamp = <3000>;
		};

		/* ??? ir_remote_out_h */
		irblaster_pin_h: group-irblaster-h-pins {
			pinmux = <AML_PINMUX(AMLOGIC_GPIO_Z, 8, 4)>;
			drive-strength-microamp = <3000>;
		};

		/* ??? ir_remote_out_z */
		irblaster_pin_z: group-irblaster-z-pins {
			pinmux = <AML_PINMUX(AMLOGIC_GPIO_Z, 8, 4)>;
			drive-strength-microamp = <3000>;
		};
		/* ??? ir_remote_out_a */
		irblaster_pin_a: group-irblaster-a-pins {
			pinmux = <AML_PINMUX(AMLOGIC_GPIO_Z, 8, 4)>;
			drive-strength-microamp = <3000>;
		};
	};

	/* ??? spdif_in */
	func-spdif {
		spdifin: group-spdif-pins {
			pinmux = <AML_PINMUX(AMLOGIC_GPIO_Z, 8, 4)>;
			drive-strength-microamp = <3000>;
		};
	};

	func-eth-a {
		eth_a_mdio_pins: group-eth-a-mdio-pins {
			pinmux = <AML_PINMUX(AMLOGIC_GPIO_Z, 0, 1)>,
				 <AML_PINMUX(AMLOGIC_GPIO_Z, 1, 1)>;
			drive-strength-microamp = <3000>;
			bias-disable;
		};

		eth_a_pins: group-eth-a-pins {
			pinmux = <AML_PINMUX(AMLOGIC_GPIO_Z, 0, 1)>,
				 <AML_PINMUX(AMLOGIC_GPIO_Z, 1, 1)>,
				 <AML_PINMUX(AMLOGIC_GPIO_Z, 2, 1)>,
				 <AML_PINMUX(AMLOGIC_GPIO_Z, 3, 1)>,
				 <AML_PINMUX(AMLOGIC_GPIO_Z, 4, 1)>,
				 <AML_PINMUX(AMLOGIC_GPIO_Z, 5, 1)>,
				 <AML_PINMUX(AMLOGIC_GPIO_Z, 9, 1)>,
				 <AML_PINMUX(AMLOGIC_GPIO_Z, 10, 1)>,
				 <AML_PINMUX(AMLOGIC_GPIO_Z, 11, 1)>;
			drive-strength-microamp = <3000>;
			bias-disable;
		};

		eth_a_rgmii_pins: group-eth-a-rgmii-pins {
			pinmux = <AML_PINMUX(AMLOGIC_GPIO_Z, 6, 1)>,
				 <AML_PINMUX(AMLOGIC_GPIO_Z, 7, 1)>,
				 <AML_PINMUX(AMLOGIC_GPIO_Z, 8, 1)>,
				 <AML_PINMUX(AMLOGIC_GPIO_Z, 12, 1)>,
				 <AML_PINMUX(AMLOGIC_GPIO_Z, 13, 1)>;
			drive-strength-microamp = <3000>;
			bias-disable;
		};
	};

	func-eth-b {
		eth_b_pins: group-eth-b-pins {
			pinmux = <AML_PINMUX(AMLOGIC_GPIO_A, 0, 7)>,
				 <AML_PINMUX(AMLOGIC_GPIO_A, 1, 7)>,
				 <AML_PINMUX(AMLOGIC_GPIO_A, 2, 7)>,
				 <AML_PINMUX(AMLOGIC_GPIO_A, 3, 7)>,
				 <AML_PINMUX(AMLOGIC_GPIO_A, 4, 7)>,
				 <AML_PINMUX(AMLOGIC_GPIO_A, 5, 7)>,
				 <AML_PINMUX(AMLOGIC_GPIO_A, 9, 7)>,
				 <AML_PINMUX(AMLOGIC_GPIO_A, 10, 7)>,
				 <AML_PINMUX(AMLOGIC_GPIO_A, 11, 7)>;
			drive-strength-microamp = <3000>;
			bias-disable;
		};

		eth_b_rgmii_pins: group-eth-b-rgmii-pins {
			pinmux = <AML_PINMUX(AMLOGIC_GPIO_A, 6, 7)>,
				 <AML_PINMUX(AMLOGIC_GPIO_A, 7, 7)>,
				 <AML_PINMUX(AMLOGIC_GPIO_A, 8, 7)>,
				 <AML_PINMUX(AMLOGIC_GPIO_A, 12, 7)>,
				 <AML_PINMUX(AMLOGIC_GPIO_A, 13, 7)>;
			drive-strength-microamp = <3000>;
			bias-disable;
		};
	};

	/* from mesona9_aduio.dtsi */
	func-audio {
		tdmb_pin: group-audio-tdmb-pins {
			pinmux = <AML_PINMUX(AMLOGIC_GPIO_A, 1, 1)>,
				 <AML_PINMUX(AMLOGIC_GPIO_A, 2, 1)>,
				 <AML_PINMUX(AMLOGIC_GPIO_A, 3, 1)>,
				 <AML_PINMUX(AMLOGIC_GPIO_A, 4, 1)>,
				 <AML_PINMUX(AMLOGIC_GPIO_A, 5, 1)>,
				 <AML_PINMUX(AMLOGIC_GPIO_A, 6, 1)>,
				 <AML_PINMUX(AMLOGIC_GPIO_A, 7, 1)>;
		};

		tdmout_b_gpio: group-audio-tdmout-b-pins {
			pinmux = <AML_PINMUX(AMLOGIC_GPIO_A, 1, 0)>,
				 <AML_PINMUX(AMLOGIC_GPIO_A, 2, 0)>,
				 <AML_PINMUX(AMLOGIC_GPIO_A, 3, 0)>,
				 <AML_PINMUX(AMLOGIC_GPIO_A, 4, 0)>,
				 <AML_PINMUX(AMLOGIC_GPIO_A, 5, 0)>,
				 <AML_PINMUX(AMLOGIC_GPIO_A, 6, 0)>,
				 <AML_PINMUX(AMLOGIC_GPIO_A, 7, 0)>;
			output-low;
		};

		mclk_1_pad: group-audio-mclk-pad-pins {
			pinmux = <AML_PINMUX(AMLOGIC_GPIO_A, 0, 1)>;
		};
	};

	/* from ervery dts */
	func-dvb {
		dvb_s_ts0_pins: group-dvb-s-ts0-pins {
			pinmux = <AML_PINMUX(AMLOGIC_GPIO_A, 0, 5)>,
				 <AML_PINMUX(AMLOGIC_GPIO_A, 1, 5)>,
				 <AML_PINMUX(AMLOGIC_GPIO_A, 2, 5)>,
				 <AML_PINMUX(AMLOGIC_GPIO_A, 3, 5)>;
		};
	};

	/* from ervery dts */
	func-tdm {
		bt_pcm_gpio_x_pins: group-tdma-bt-pcm-pins {
			pinmux = <AML_PINMUX(AMLOGIC_GPIO_X, 7, 1)>,
				 <AML_PINMUX(AMLOGIC_GPIO_X, 8, 1)>,
				 <AML_PINMUX(AMLOGIC_GPIO_X, 9, 1)>,
				 <AML_PINMUX(AMLOGIC_GPIO_X, 10, 1)>;
		};
	};
};

&aobus_pinctrl {
	func-jtag-a {
		jtag_a_pins: group-jtag-a-pins {
			pinmux = <AML_PINMUX(AMLOGIC_GPIO_D, 8, 2)>,
				 <AML_PINMUX(AMLOGIC_GPIO_D, 9, 2)>,
				 <AML_PINMUX(AMLOGIC_GPIO_D, 10, 2)>,
				 <AML_PINMUX(AMLOGIC_GPIO_D, 11, 2)>;
		};
	};

	func-aocec {
		eecec_b: group-eecec-b-pins {
			pinmux = <AML_PINMUX(AMLOGIC_GPIO_D, 14, 2)>;
			bias-pull-up;
		};
	};

	func-jtag-b {
		jtag_b_pins: group-jtag-b-pins {
			pinmux = <AML_PINMUX(AMLOGIC_GPIO_C, 0, 2)>,
				 <AML_PINMUX(AMLOGIC_GPIO_C, 1, 2)>,
				 <AML_PINMUX(AMLOGIC_GPIO_C, 4, 2)>,
				 <AML_PINMUX(AMLOGIC_GPIO_C, 5, 2)>;
		};
	};

	func-sdcard {
		sdcard_pins: group-sdcard-pins {
			pinmux = <AML_PINMUX(AMLOGIC_GPIO_C, 0, 1)>,
				 <AML_PINMUX(AMLOGIC_GPIO_C, 1, 1)>,
				 <AML_PINMUX(AMLOGIC_GPIO_C, 2, 1)>,
				 <AML_PINMUX(AMLOGIC_GPIO_C, 3, 1)>,
				 <AML_PINMUX(AMLOGIC_GPIO_C, 4, 1)>,
				 <AML_PINMUX(AMLOGIC_GPIO_C, 5, 1)>;
			bias-pull-up;
			drive-strength-microamp = <4000>;
		};

		sd_1bit_pins: group-sd-1bit-pins {
			pinmux = <AML_PINMUX(AMLOGIC_GPIO_C, 0, 1)>,
				 <AML_PINMUX(AMLOGIC_GPIO_C, 4, 1)>,
				 <AML_PINMUX(AMLOGIC_GPIO_C, 5, 1)>;
			bias-pull-up;
			drive-strength-microamp = <4000>;
		};

		sdcard_clk_gate_pins: group-sdcard-clk-gate-pins {
			pinmux = <AML_PINMUX(AMLOGIC_GPIO_C, 4, 0)>;
			bias-pull-down;
			drive-strength-microamp = <4000>;
		};
	};

	func-spisg-a {
		spisg_a_pins_d: group-spisg-a-pins1 {
			pinmux = <AML_PINMUX(AMLOGIC_GPIO_D, 2, 2)>,
				 <AML_PINMUX(AMLOGIC_GPIO_D, 3, 2)>,
				 <AML_PINMUX(AMLOGIC_GPIO_D, 4, 2)>,
				 <AML_PINMUX(AMLOGIC_GPIO_D, 5, 2)>,
				 <AML_PINMUX(AMLOGIC_GPIO_D, 6, 2)>,
				 <AML_PINMUX(AMLOGIC_GPIO_D, 7, 2)>;
			bias-pull-up;
			drive-strength-microamp = <3000>;
		};

		spisg_a_pins_ao: group-spisg-a-pins2 {
			pinmux = <AML_PINMUX(AMLOGIC_GPIO_AO, 0, 3)>,
				 <AML_PINMUX(AMLOGIC_GPIO_AO, 1, 3)>,
				 <AML_PINMUX(AMLOGIC_GPIO_AO, 2, 3)>,
				 <AML_PINMUX(AMLOGIC_GPIO_AO, 3, 3)>;
			bias-pull-up;
			drive-strength-microamp = <3000>;
		};
	};

	func-spisg-b {
		spisg_b_pins_ao: group-spisg-b-pins1 {
			pinmux = <AML_PINMUX(AMLOGIC_GPIO_AO, 4, 3)>,
				 <AML_PINMUX(AMLOGIC_GPIO_AO, 5, 3)>,
				 <AML_PINMUX(AMLOGIC_GPIO_AO, 6, 3)>,
				 <AML_PINMUX(AMLOGIC_GPIO_AO, 7, 3)>,
				 <AML_PINMUX(AMLOGIC_GPIO_AO, 8, 3)>,
				 <AML_PINMUX(AMLOGIC_GPIO_AO, 9, 3)>;
			bias-pull-up;
			drive-strength-microamp = <3000>;
		};
	};

	func-spisg-d {
		spisg_d_pins_c: group-spisg-d-pins1 {
			pinmux = <AML_PINMUX(AMLOGIC_GPIO_C, 0, 3)>,
				 <AML_PINMUX(AMLOGIC_GPIO_C, 1, 3)>,
				 <AML_PINMUX(AMLOGIC_GPIO_C, 2, 3)>,
				 <AML_PINMUX(AMLOGIC_GPIO_C, 3, 3)>,
				 <AML_PINMUX(AMLOGIC_GPIO_C, 4, 3)>,
				 <AML_PINMUX(AMLOGIC_GPIO_C, 5, 3)>;
			bias-pull-up;
			drive-strength-microamp = <3000>;
		};
	};

	func-rtc-32k {
		rtc_32k_pins: group-rtc-32k-pins1 {
			pinmux = <AML_PINMUX(AMLOGIC_GPIO_D, 4, 3)>;
			bias-pull-up;
			input-enable;
		};
	};

	func-uart-b {
		b_ao_uart_pins: group-uart-b-pins {
			pinmux = <AML_PINMUX(AMLOGIC_GPIO_D, 0, 1)>,
				 <AML_PINMUX(AMLOGIC_GPIO_D, 1, 1)>;
			drive-strength = <3>;
			bias-pull-up;
		};
	};

	func-uart-c {
		c_ao_uart_pins: group-uart-c-pins {
			pinmux = <AML_PINMUX(AMLOGIC_GPIO_AO, 2, 4)>,
				 <AML_PINMUX(AMLOGIC_GPIO_AO, 3, 4)>,
				 <AML_PINMUX(AMLOGIC_GPIO_AO, 4, 4)>,
				 <AML_PINMUX(AMLOGIC_GPIO_AO, 5, 4)>;
			drive-strength = <3>;
			bias-pull-up;
		};
	};

	func-uart-d {
		d_ao_uart_pins: group-uart-d-pins {
			pinmux = <AML_PINMUX(AMLOGIC_GPIO_C, 0, 6)>,
				 <AML_PINMUX(AMLOGIC_GPIO_C, 1, 6)>,
				 <AML_PINMUX(AMLOGIC_GPIO_C, 5, 6)>,
				 <AML_PINMUX(AMLOGIC_GPIO_C, 6, 6)>;
			drive-strength = <3>;
			bias-pull-up;
		};
	};

	func-uart-e {
		e_ao_uart_pins: group-uart-e-pins {
			pinmux = <AML_PINMUX(AMLOGIC_GPIO_D, 8, 5)>,
				 <AML_PINMUX(AMLOGIC_GPIO_D, 9, 5)>,
				 <AML_PINMUX(AMLOGIC_GPIO_D, 10, 5)>,
				 <AML_PINMUX(AMLOGIC_GPIO_D, 11, 5)>;
			drive-strength = <3>;
			bias-pull-up;
		};
	};

	/* from mesona9_aduio.dtsi */
	func-audio {
		pdmin: group-aduio-pdmin-pins {
			pinmux = <AML_PINMUX(AMLOGIC_GPIO_AO, 6, 1)>,
				 <AML_PINMUX(AMLOGIC_GPIO_AO, 7, 1)>,
				 <AML_PINMUX(AMLOGIC_GPIO_AO, 8, 1)>,
				 <AML_PINMUX(AMLOGIC_GPIO_AO, 9, 1)>,
				 <AML_PINMUX(AMLOGIC_GPIO_AO, 10, 1)>;
		};

		spdifout_a: group-aduio-spdifout-a-pins {
			pinmux = <AML_PINMUX(AMLOGIC_GPIO_D, 13, 2)>;
		};

		spdifout_a_mute: group-aduio-spdifout-a-mute-pins {
			pinmux = <AML_PINMUX(AMLOGIC_GPIO_D, 13, 0)>;
		};
		spdifin_a: group-aduio-spdifin-a-pins {
			pinmux = <AML_PINMUX(AMLOGIC_GPIO_D, 13, 3)>;
		};
	};
};

&gpu{
	status = "okay";
	operating-points-v2 = <&gpu_opp_table>;
	reg =   <0x0 0xFD000000 0x0 0x800000>, /*mali APB bus base address*/
		<0x0 0xFE002000 0x0 0x01000>; /*reset register*/

	interrupts = <GIC_SPI 146 IRQ_TYPE_LEVEL_HIGH>,
		     <GIC_SPI 147 IRQ_TYPE_LEVEL_HIGH>,
		     <GIC_SPI 145 IRQ_TYPE_LEVEL_HIGH>;
	interrupt-names = "GPU", "MMU", "JOB";

	/* Protected memory allocator default not available*/
	//protected-memory-allocator = <&gpu_protected_memory_allocator>;

	qchannel-reg = <0xFE010404>;
	qchannel-enabled = <1>;
	qchannel-supported = <1>;

	num_of_pp = <1>;
	system-coherency = <31>;
	clocks = <&clkc CLKID_MALI>,
		 <&clkc CLKID_MALI_STACK>;
	clock-names = "gpu_mux", "gpu_stack";

	assigned-clocks = <&clkc CLKID_MALI>,
			  <&clkc CLKID_MALI_STACK>;
	assigned-clock-rates = <400000000>,
			       <400000000>;

};

#include "mesona9_cpufreq.dtsi"
